VERSION ""

NS_ :

BS_:

BU_: SCCM RF_HUB PTS ORC OCM IC HCP HALF ETM ESM ESC EPS ECM EBCM DIAGNOST DASM CBC AirSusp TCM DTCM ELSDM

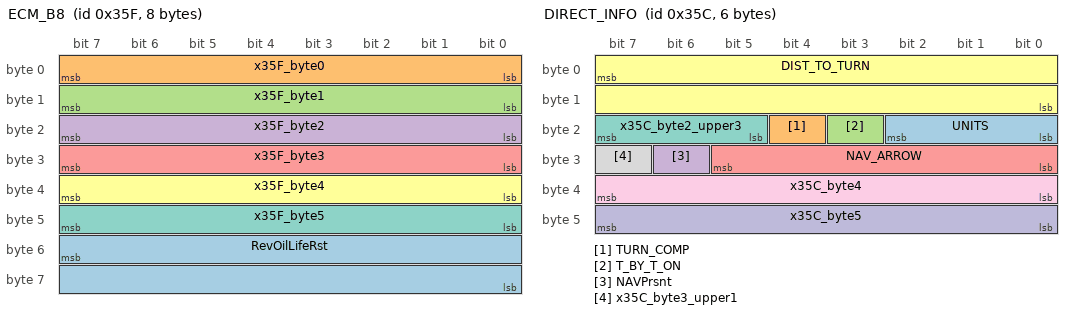
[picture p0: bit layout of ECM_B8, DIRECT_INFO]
BO_ 863 ECM_B8: 8 ECM
 SG_ RevOilLifeRst : 55|16@0+ (1000,0) [0|65534000] "Rev's"  CBC
 SG_ x35F_byte0 : 7|8@0+ (1,0) [0|0] "" Vector__XXX
 SG_ x35F_byte1 : 15|8@0+ (1,0) [0|0] "" Vector__XXX
 SG_ x35F_byte2 : 23|8@0+ (1,0) [0|0] "" Vector__XXX
 SG_ x35F_byte3 : 31|8@0+ (1,0) [0|0] "" Vector__XXX
 SG_ x35F_byte4 : 39|8@0+ (1,0) [0|0] "" Vector__XXX
 SG_ x35F_byte5 : 47|8@0+ (1,0) [0|0] "" Vector__XXX

BO_ 860 DIRECT_INFO: 6 CBC
 SG_ UNITS : 16|3@1+ (1,0) [0|7] ""  IC
 SG_ TURN_COMP : 20|1@1+ (1,0) [0|1] ""  IC
 SG_ T_BY_T_ON : 19|1@1+ (1,0) [0|1] ""  IC
 SG_ NAVPrsnt : 30|1@1+ (1,0) [0|1] ""  IC
 SG_ NAV_ARROW : 24|6@1+ (1,0) [1|63] "Arrow"  IC
 SG_ DIST_TO_TURN : 7|16@0+ (1,0) [0|65534] ""  IC
 SG_ x35C_byte2_upper3 : 21|3@1+ (1,0) [0|7] "" Vector__XXX
 SG_ x35C_byte3_upper1 : 31|1@1+ (1,0) [0|1] "" Vector__XXX
 SG_ x35C_byte4 : 32|8@1+ (1,0) [0|255] "" Vector__XXX
 SG_ x35C_byte5 : 40|8@1+ (1,0) [0|255] "" Vector__XXX

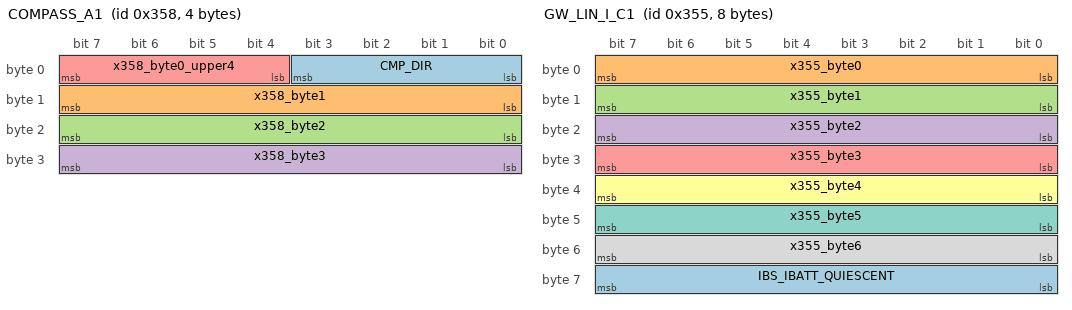
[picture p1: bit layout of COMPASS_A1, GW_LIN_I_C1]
BO_ 856 COMPASS_A1: 4 CBC
 SG_ CMP_DIR : 0|4@1+ (1,0) [0|0] ""  IC
 SG_ x358_byte1 : 8|8@1+ (1,0) [0|255] "" Vector__XXX
 SG_ x358_byte2 : 16|8@1+ (1,0) [0|255] "" Vector__XXX
 SG_ x358_byte3 : 24|8@1+ (1,0) [0|255] "" Vector__XXX
 SG_ x358_byte0_upper4 : 4|4@1+ (1,0) [0|15] "" Vector__XXX

BO_ 853 GW_LIN_I_C1: 8 CBC
 SG_ IBS_IBATT_QUIESCENT : 56|8@1+ (0.00390625,0) [0|0.984375] "Amp" Vector__XXX
 SG_ x355_byte0 : 0|8@1+ (1,0) [0|0] "" Vector__XXX
 SG_ x355_byte1 : 8|8@1+ (1,0) [0|0] "" Vector__XXX
 SG_ x355_byte2 : 16|8@1+ (1,0) [0|0] "" Vector__XXX
 SG_ x355_byte3 : 24|8@1+ (1,0) [0|0] "" Vector__XXX
 SG_ x355_byte4 : 32|8@1+ (1,0) [0|0] "" Vector__XXX
 SG_ x355_byte5 : 40|8@1+ (1,0) [0|0] "" Vector__XXX
 SG_ x355_byte6 : 48|8@1+ (1,0) [0|0] "" Vector__XXX

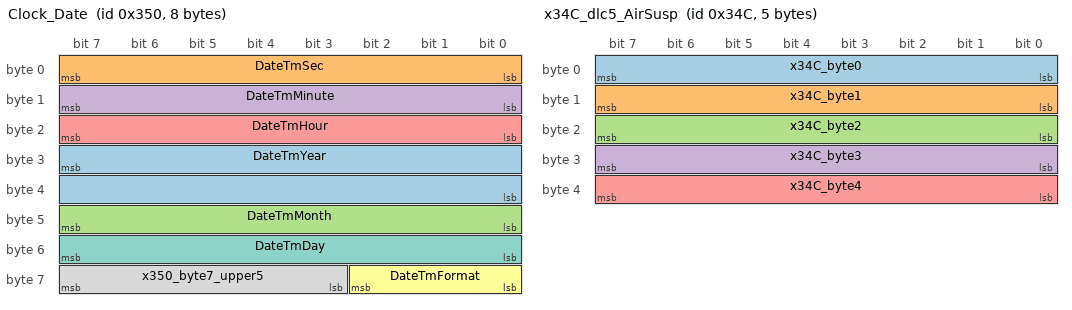
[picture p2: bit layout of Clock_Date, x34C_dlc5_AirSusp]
BO_ 848 Clock_Date: 8 CBC
 SG_ DateTmYear : 31|16@0+ (1,0) [0|65534] "Years"  RF_HUB,IC
 SG_ DateTmSec : 0|8@1+ (1,0) [0|59] "sec"  IC
 SG_ DateTmMonth : 40|8@1+ (1,0) [1|12] "Months"  RF_HUB,IC
 SG_ DateTmMinute : 8|8@1+ (1,0) [0|59] "min"  RF_HUB,IC
 SG_ DateTmHour : 16|8@1+ (1,0) [0|23] "Hours"  RF_HUB,IC
 SG_ DateTmFormat : 56|3@1+ (1,0) [0|0] ""  IC
 SG_ DateTmDay : 48|8@1+ (1,0) [1|31] "Days"  RF_HUB,IC
 SG_ x350_byte7_upper5 : 59|5@1+ (1,0) [0|31] "" Vector__XXX

BO_ 844 x34C_dlc5_AirSusp: 5 AirSusp
 SG_ x34C_byte0 : 0|8@1+ (1,0) [0|255] "" Vector__XXX
 SG_ x34C_byte1 : 8|8@1+ (1,0) [0|255] "" Vector__XXX
 SG_ x34C_byte2 : 16|8@1+ (1,0) [0|255] "" Vector__XXX
 SG_ x34C_byte3 : 24|8@1+ (1,0) [0|255] "" Vector__XXX
 SG_ x34C_byte4 : 32|8@1+ (1,0) [0|255] "" Vector__XXX

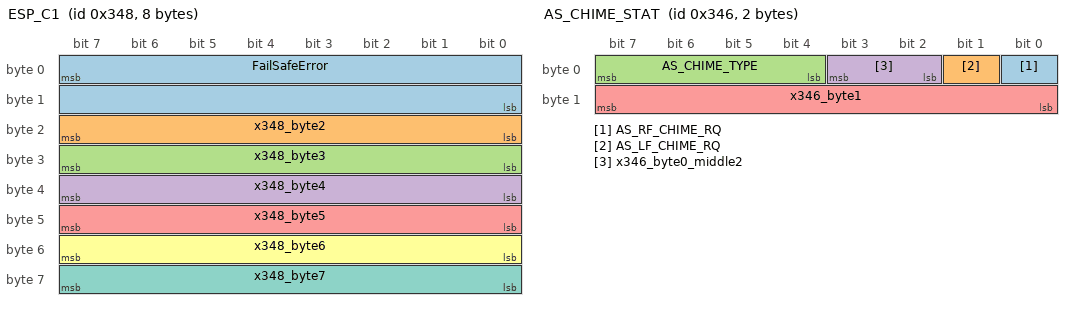
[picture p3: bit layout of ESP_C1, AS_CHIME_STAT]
BO_ 840 ESP_C1: 8 ESC
 SG_ FailSafeError : 7|16@0+ (1,0) [0|65534] ""  DASM
 SG_ x348_byte2 : 23|8@0+ (1,0) [0|255] "" Vector__XXX
 SG_ x348_byte3 : 31|8@0+ (1,0) [0|255] "" Vector__XXX
 SG_ x348_byte4 : 39|8@0+ (1,0) [0|255] "" Vector__XXX
 SG_ x348_byte5 : 47|8@0+ (1,0) [0|255] "" Vector__XXX
 SG_ x348_byte6 : 55|8@0+ (1,0) [0|255] "" Vector__XXX
 SG_ x348_byte7 : 63|8@0+ (1,0) [0|255] "" Vector__XXX

BO_ 838 AS_CHIME_STAT: 2 DASM
 SG_ AS_RF_CHIME_RQ : 0|1@1+ (1,0) [0|1] ""  CBC
 SG_ AS_LF_CHIME_RQ : 1|1@1+ (1,0) [0|1] ""  CBC
 SG_ AS_CHIME_TYPE : 4|4@1+ (1,0) [0|15] ""  ORC,CBC
 SG_ x346_byte0_middle2 : 2|2@1+ (1,0) [0|3] "" Vector__XXX
 SG_ x346_byte1 : 8|8@1+ (1,0) [0|255] "" Vector__XXX

BO_ 832 IC_500Cyc: 8 IC
 SG_ VehSpdDisp : 55|16@0+ (1,0) [0|65534] ""  CBC
 SG_ VehSpd_MPH : 47|1@1+ (1,0) [0|0] ""  CBC
 SG_ Est_Range_Disp : 32|8@1+ (1,0) [0|254] ""  ETM

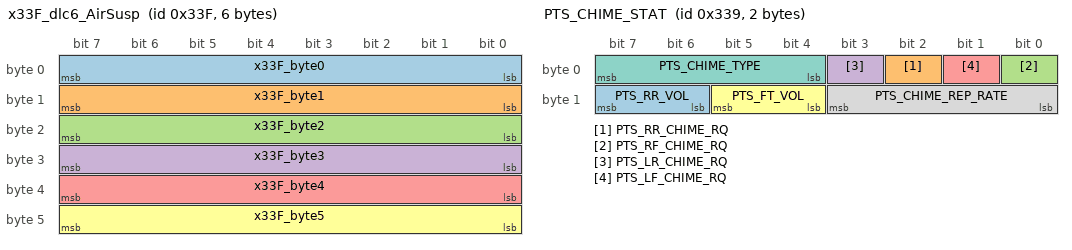
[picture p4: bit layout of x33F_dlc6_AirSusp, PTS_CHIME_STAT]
BO_ 831 x33F_dlc6_AirSusp: 6 AirSusp
 SG_ x33F_byte0 : 0|8@1+ (1,0) [0|255] "" Vector__XXX
 SG_ x33F_byte1 : 8|8@1+ (1,0) [0|255] "" Vector__XXX
 SG_ x33F_byte2 : 16|8@1+ (1,0) [0|255] "" Vector__XXX
 SG_ x33F_byte3 : 24|8@1+ (1,0) [0|255] "" Vector__XXX
 SG_ x33F_byte4 : 32|8@1+ (1,0) [0|255] "" Vector__XXX
 SG_ x33F_byte5 : 40|8@1+ (1,0) [0|255] "" Vector__XXX

BO_ 826 PTS_1: 8 PTS
 SG_ PTS_STAT : 60|2@1+ (1,0) [0|0] ""  CBC
 SG_ PTS_SRV_RQ : 5|1@1+ (1,0) [0|0] ""  IC
 SG_ PTS_RR_SRV : 59|1@1+ (1,0) [0|0] ""  IC
 SG_ PTS_RR_NA : 4|1@1+ (1,0) [0|0] ""  IC
 SG_ PTS_GraphicRR : 38|2@1+ (1,0) [0|0] ""  IC
 SG_ PTS_GraphicRL : 30|2@1+ (1,0) [0|0] ""  IC
 SG_ PTS_GraphicRC : 54|2@1+ (1,0) [0|0] ""  IC
 SG_ PTS_GraphicFR : 22|2@1+ (1,0) [0|0] ""  IC
 SG_ PTS_GraphicFL : 14|2@1+ (1,0) [0|0] ""  IC
 SG_ PTS_GraphicFC : 46|2@1+ (1,0) [0|0] ""  IC
 SG_ PTS_FT_SRV : 58|1@1+ (1,0) [0|0] ""  IC
 SG_ PTS_FT_NA : 3|1@1+ (1,0) [0|0] ""  IC
 SG_ PTS_CFG_STAT : 1|2@1+ (1,0) [0|0] ""  CBC
 SG_ PTS_AlrRR : 32|4@1+ (1,0) [0|0] ""  IC,CBC
 SG_ PTS_AlrRL : 24|4@1+ (1,0) [0|0] ""  IC,CBC
 SG_ PTS_AlrRC : 48|4@1+ (1,0) [0|0] ""  IC,CBC
 SG_ PTS_AlrFR : 16|4@1+ (1,0) [0|0] ""  IC,CBC
 SG_ PTS_AlrFL : 8|4@1+ (1,0) [0|0] ""  IC,CBC
 SG_ PTS_AlrFC : 40|4@1+ (1,0) [0|0] ""  IC,CBC

BO_ 825 PTS_CHIME_STAT: 2 PTS
 SG_ PTS_RR_VOL : 14|2@1+ (1,0) [0|0] ""  CBC
 SG_ PTS_RR_CHIME_RQ : 2|1@1+ (1,0) [0|0] ""  CBC
 SG_ PTS_RF_CHIME_RQ : 0|1@1+ (1,0) [0|0] ""  CBC
 SG_ PTS_LR_CHIME_RQ : 3|1@1+ (1,0) [0|0] ""  CBC
 SG_ PTS_LF_CHIME_RQ : 1|1@1+ (1,0) [0|0] ""  CBC
 SG_ PTS_FT_VOL : 12|2@1+ (1,0) [0|0] ""  CBC
 SG_ PTS_CHIME_TYPE : 4|4@1+ (1,0) [0|0] ""  CBC
 SG_ PTS_CHIME_REP_RATE : 8|4@1+ (1,0) [0|15] "Hz"  CBC

BO_ 820 CBC_PT1: 8 CBC
 SG_ WASH_FLUID_LO : 63|1@1+ (1,0) [0|0] ""  IC,ETM
 SG_ TurnInd_RT_ON : 31|1@1+ (1,0) [0|0] ""  IC,HALF
 SG_ TurnInd_LT_ON : 30|1@1+ (1,0) [0|0] ""  IC,HALF
 SG_ TLG_AJAR : 22|1@1+ (1,0) [0|0] ""  RF_HUB,PTS,IC,ETM
 SG_ SHIP_STAT : 28|2@1+ (1,0) [0|0] ""  RF_HUB,IC,HCP,DASM
 SG_ REV_GEAR : 4|1@1+ (1,0) [0|0] ""  ORC,HALF,EPS
 SG_ R_R_AJAR : 20|1@1+ (1,0) [0|0] ""  RF_HUB,IC,ETM
 SG_ PSG_AJAR : 18|1@1+ (1,0) [0|0] ""  RF_HUB,IC,ETM,ESC
 SG_ PARK_LMP_ON : 16|1@1+ (1,0) [0|0] ""  IC
 SG_ PANEL_INTS : 48|8@1+ (0.5,0) [0|100] "%"  SCCM,RF_HUB,IC,ESM
 SG_ LOBEAM_ON : 57|1@1+ (1,0) [0|0] "" Vector__XXX
 SG_ L_R_AJAR : 19|1@1+ (1,0) [0|0] ""  RF_HUB,IC,ETM
 SG_ IGN_OFF_TIME_LNG : 27|12@0+ (1,0) [0|4080] "min"  ESC,ECM,DASM
 SG_ HIBEAM_ON : 58|1@1+ (1,0) [0|0] ""  IC,HALF
 SG_ FT_WPR_NOT_PRK : 56|1@1+ (1,0) [0|0] ""  HALF,ECM,DASM
 SG_ FT_FOG_RQ : 2|1@1+ (1,0) [0|0] ""  IC
 SG_ FOB_SrchRq : 8|2@1+ (1,0) [0|0] ""  RF_HUB
 SG_ DRV_AJAR : 17|1@1+ (1,0) [0|0] ""  RF_HUB,PTS,IC,HCP,ETM,ESC,DASM
 SG_ DR_LK_STAT : 5|2@1+ (1,0) [0|0] "" Vector__XXX
 SG_ DAY_LGT_MD : 40|1@1+ (1,0) [0|0] ""  SCCM,RF_HUB,IC,ESM
 SG_ BRK_FLUID_LO : 62|1@1+ (1,0) [0|0] ""  IC,ETM,ESC
 SG_ AHB_ACT : 14|1@1+ (1,0) [0|0] ""  IC
 SG_ x334_byte0_lower2 : 0|2@1+ (1,0) [0|3] "" Vector__XXX
 SG_ x334_byte1_middle1 : 3|1@1+ (1,0) [0|1] "" Vector__XXX
 SG_ x334_byte0_upper1 : 7|1@1+ (1,0) [0|1] "" Vector__XXX
 SG_ x334_byte1_middle4 : 10|4@1+ (1,0) [0|15] "" Vector__XXX
 SG_ x334_byte1_upper1 : 15|1@1+ (1,0) [0|1] "" Vector__XXX
 SG_ x334_byte2_middle1 : 21|1@1+ (1,0) [0|1] "" Vector__XXX
 SG_ x334_ParkingBrakeState : 23|1@1+ (1,0) [0|1] "" Vector__XXX
 SG_ x334_byte5_upper7 : 41|7@1+ (1,0) [0|127] "" Vector__XXX
 SG_ x334_byte7_middle3 : 59|3@1+ (1,0) [0|7] "" Vector__XXX

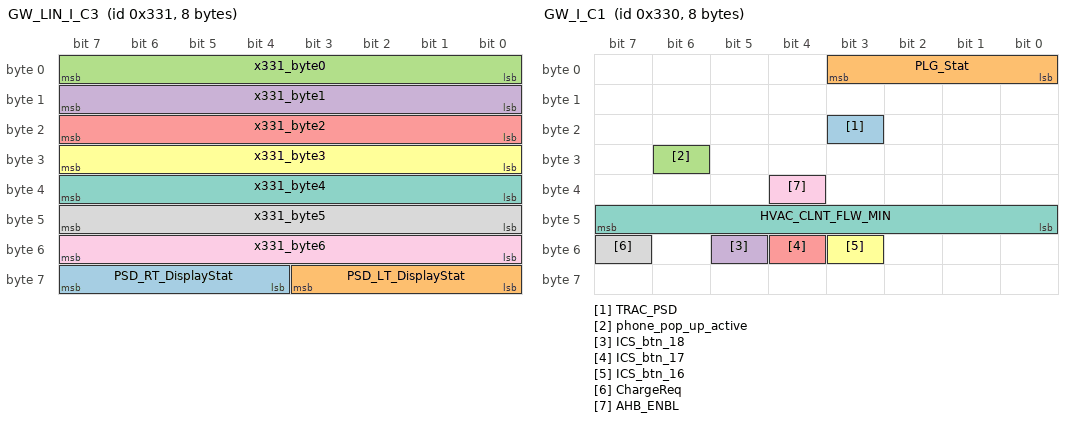
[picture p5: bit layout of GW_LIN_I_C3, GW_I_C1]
BO_ 817 GW_LIN_I_C3: 8 CBC
 SG_ PSD_RT_DisplayStat : 60|4@1+ (1,0) [0|0] ""  IC
 SG_ PSD_LT_DisplayStat : 56|4@1+ (1,0) [0|0] ""  IC
 SG_ x331_byte0 : 0|8@1+ (1,0) [0|255] "" Vector__XXX
 SG_ x331_byte1 : 8|8@1+ (1,0) [0|255] "" Vector__XXX
 SG_ x331_byte2 : 16|8@1+ (1,0) [0|255] "" Vector__XXX
 SG_ x331_byte3 : 24|8@1+ (1,0) [0|255] "" Vector__XXX
 SG_ x331_byte4 : 32|8@1+ (1,0) [0|255] "" Vector__XXX
 SG_ x331_byte5 : 40|8@1+ (1,0) [0|255] "" Vector__XXX
 SG_ x331_byte6 : 48|8@1+ (1,0) [0|255] "" Vector__XXX

BO_ 816 GW_I_C1: 8 CBC
 SG_ TRAC_PSD : 19|1@1+ (1,0) [0|0] ""  IC,ESC
 SG_ PLG_Stat : 0|4@1+ (1,0) [0|0] ""  IC
 SG_ phone_pop_up_active : 30|1@1+ (1,0) [0|0] ""  IC
 SG_ ICS_btn_18 : 53|1@1+ (1,0) [0|0] ""  HALF
 SG_ ICS_btn_17 : 52|1@1+ (1,0) [0|0] ""  PTS
 SG_ ICS_btn_16 : 51|1@1+ (1,0) [0|0] ""  PTS
 SG_ HVAC_CLNT_FLW_MIN : 40|8@1+ (0.521555,0) [0.521555|131.953415] "LpM" Vector__XXX
 SG_ ChargeReq : 55|1@1+ (1,0) [0|0] ""  IC,HCP
 SG_ AHB_ENBL : 36|1@1+ (1,0) [0|0] "" Vector__XXX

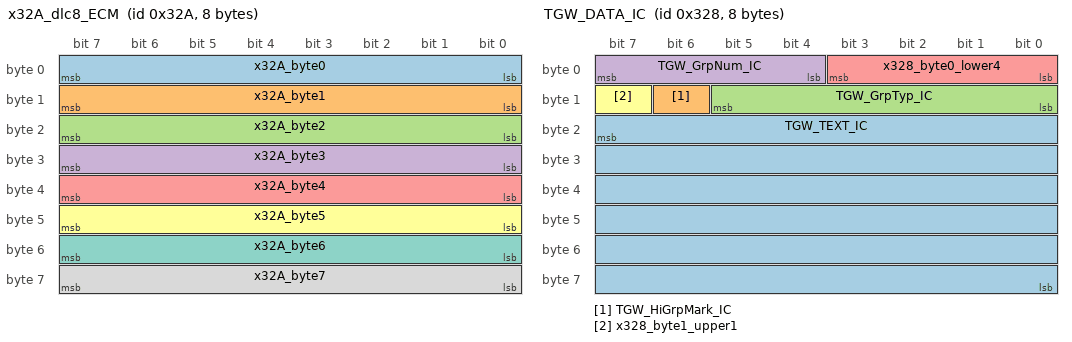
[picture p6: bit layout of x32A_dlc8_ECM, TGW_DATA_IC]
BO_ 810 x32A_dlc8_ECM: 8 ECM
 SG_ x32A_byte0 : 0|8@1+ (1,0) [0|255] "" Vector__XXX
 SG_ x32A_byte1 : 8|8@1+ (1,0) [0|255] "" Vector__XXX
 SG_ x32A_byte2 : 16|8@1+ (1,0) [0|255] "" Vector__XXX
 SG_ x32A_byte3 : 24|8@1+ (1,0) [0|255] "" Vector__XXX
 SG_ x32A_byte4 : 32|8@1+ (1,0) [0|255] "" Vector__XXX
 SG_ x32A_byte5 : 40|8@1+ (1,0) [0|255] "" Vector__XXX
 SG_ x32A_byte6 : 48|8@1+ (1,0) [0|255] "" Vector__XXX
 SG_ x32A_byte7 : 56|8@1+ (1,0) [0|255] "" Vector__XXX

BO_ 808 TGW_DATA_IC: 8 CBC
 SG_ TGW_TEXT_IC : 23|48@0+ (1,0) [0|0] ""  IC
 SG_ TGW_HiGrpMark_IC : 14|1@1+ (1,0) [0|0] ""  IC
 SG_ TGW_GrpTyp_IC : 8|6@1+ (1,0) [1|40] "Text"  IC
 SG_ TGW_GrpNum_IC : 4|4@1+ (1,1) [1|16] "Group"  IC
 SG_ x328_byte0_lower4 : 0|4@1+ (1,0) [0|15] "" Vector__XXX
 SG_ x328_byte1_upper1 : 15|1@1+ (1,0) [0|1] "" Vector__XXX

BO_ 804 CBC_PT4: 8 CBC
 SG_ WPR_SYS_WASH : 46|1@1+ (1,0) [0|0] ""  HALF,DASM,ESC
 SG_ WPR_SYS_OFF : 40|1@1+ (1,0) [0|0] ""  HALF,DASM,ESC
 SG_ WPR_SYS_MIST : 45|1@1+ (1,0) [0|0] ""  HALF,DASM,ESC
 SG_ WPR_SYS_LOW : 41|1@1+ (1,0) [0|0] ""  HALF,DASM,ESC
 SG_ WPR_SYS_INT : 43|1@1+ (1,0) [0|0] ""  HALF,DASM,ESC
 SG_ WPR_SYS_HIGH : 42|1@1+ (1,0) [0|0] ""  HALF,DASM,ESC
 SG_ WPR_SYS_FLT : 47|1@1+ (1,0) [0|0] ""  HALF,DASM,ESC
 SG_ WPR_SYS_AUTO : 44|1@1+ (1,0) [0|0] ""  HALF,DASM,ESC
 SG_ TurnLmp_RR_Flt : 25|1@1+ (1,0) [0|0] ""  HALF,IC
 SG_ TurnLmp_RL_Flt : 24|1@1+ (1,0) [0|0] ""  HALF,IC
 SG_ TurnLmp_FR_Flt : 14|1@1+ (1,0) [0|0] ""  HALF,IC
 SG_ TurnLmp_FL_Flt : 13|1@1+ (1,0) [0|0] ""  HALF,IC
 SG_ RemSt_Inhibit : 32|8@1+ (1,0) [0|0] ""  IC
 SG_ HdAjar : 10|1@1+ (1,0) [0|0] ""  IC,HCP
 SG_ ExteriorRearReleaseSwitchSts : 21|1@1+ (1,0) [0|0] ""  RF_HUB
 SG_ ACC_DLY_ACT : 26|1@1+ (1,0) [0|0] ""  IC
 SG_ x324_byte0 : 0|8@1+ (1,0) [0|255] "" Vector__XXX
 SG_ x324_byte1_lower2 : 8|2@1+ (1,0) [0|3] "" Vector__XXX
 SG_ x324_byte1_middle2 : 11|2@1+ (1,0) [0|3] "" Vector__XXX
 SG_ x324_byte1_upper1 : 15|1@1+ (1,0) [0|1] "" Vector__XXX
 SG_ x324_byte2_lower5 : 16|5@1+ (1,0) [0|31] "" Vector__XXX
 SG_ x324_byte2_upper2 : 22|2@1+ (1,0) [0|3] "" Vector__XXX
 SG_ x324_byte3_upper5 : 27|5@1+ (1,0) [0|31] "" Vector__XXX
 SG_ x324_byte6 : 48|8@1+ (1,0) [0|255] "" Vector__XXX
 SG_ x324_byte7 : 56|8@1+ (1,0) [0|255] "" Vector__XXX

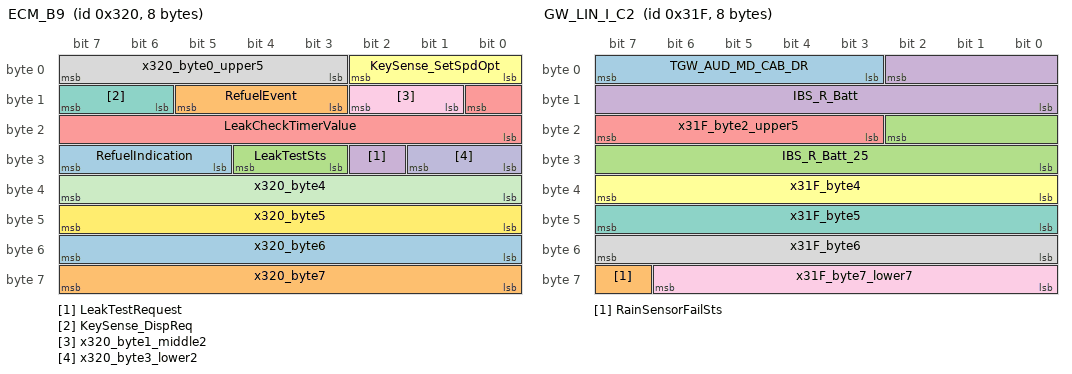
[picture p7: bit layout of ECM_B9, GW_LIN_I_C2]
BO_ 800 ECM_B9: 8 ECM
 SG_ RefuelIndication : 29|3@1+ (1,0) [0|0] ""  IC
 SG_ RefuelEvent : 11|3@1+ (1,0) [0|0] ""  CBC
 SG_ LeakTestSts : 27|2@1+ (1,0) [0|0] ""  CBC
 SG_ LeakTestRequest : 26|1@1+ (1,0) [0|0] ""  CBC
 SG_ LeakCheckTimerValue : 8|9@0+ (1,0) [0|510] "min"  CBC
 SG_ KeySense_SetSpdOpt : 0|3@1+ (1,0) [0|0] ""  ORC,IC,DASM,CBC
 SG_ KeySense_DispReq : 14|2@1+ (1,0) [0|0] ""  IC
 SG_ x320_byte0_upper5 : 3|5@1+ (1,0) [0|0] "" Vector__XXX
 SG_ x320_byte1_middle2 : 9|2@1+ (1,0) [0|0] "" Vector__XXX
 SG_ x320_byte3_lower2 : 24|2@1+ (1,0) [0|0] "" Vector__XXX
 SG_ x320_byte4 : 32|8@1+ (1,0) [0|0] "" Vector__XXX
 SG_ x320_byte5 : 40|8@1+ (1,0) [0|0] "" Vector__XXX
 SG_ x320_byte6 : 48|8@1+ (1,0) [0|0] "" Vector__XXX
 SG_ x320_byte7 : 56|8@1+ (1,0) [0|0] "" Vector__XXX

BO_ 799 GW_LIN_I_C2: 8 CBC
 SG_ TGW_AUD_MD_CAB_DR : 3|5@1+ (1,0) [0|0] ""  IC
 SG_ RainSensorFailSts : 63|1@1+ (1,0) [0|0] ""  IC
 SG_ IBS_R_Batt_25 : 18|11@0+ (0.05,0) [0|20] "mOhm" Vector__XXX
 SG_ IBS_R_Batt : 2|11@0+ (0.05,0) [0|20] "mOhm" Vector__XXX
 SG_ x31F_byte2_upper5 : 19|5@1+ (1,0) [0|31] "" Vector__XXX
 SG_ x31F_byte4 : 32|8@1+ (1,0) [0|255] "" Vector__XXX
 SG_ x31F_byte5 : 40|8@1+ (1,0) [0|255] "" Vector__XXX
 SG_ x31F_byte6 : 48|8@1+ (1,0) [0|255] "" Vector__XXX
 SG_ x31F_byte7_lower7 : 56|7@1+ (1,0) [0|127] "" Vector__XXX

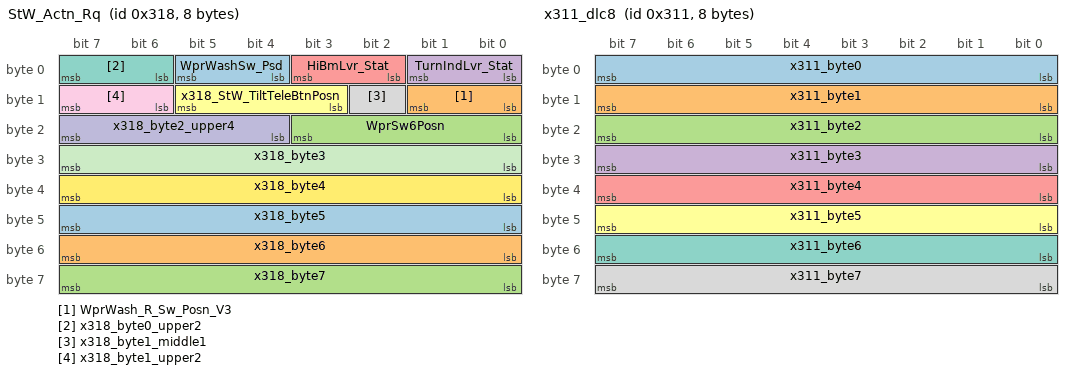
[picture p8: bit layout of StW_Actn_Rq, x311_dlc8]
BO_ 792 StW_Actn_Rq: 8 SCCM
 SG_ WprWashSw_Psd : 4|2@1+ (1,0) [0|0] ""  CBC
 SG_ WprWash_R_Sw_Posn_V3 : 8|2@1+ (1,0) [0|0] ""  CBC
 SG_ WprSw6Posn : 16|4@1+ (1,0) [0|0] ""  DASM,CBC
 SG_ TurnIndLvr_Stat : 0|2@1+ (1,0) [0|0] ""  PTS,HALF,DASM,CBC
 SG_ HiBmLvr_Stat : 2|2@1+ (1,0) [0|0] ""  CBC
 SG_ x318_StW_TiltTeleBtnPosn : 11|3@1+ (1,0) [0|7] "Enum" Vector__XXX
 SG_ x318_byte0_upper2 : 6|2@1+ (1,0) [0|3] "" Vector__XXX
 SG_ x318_byte1_middle1 : 10|1@1+ (1,0) [0|1] "" Vector__XXX
 SG_ x318_byte1_upper2 : 14|2@1+ (1,0) [0|3] "" Vector__XXX
 SG_ x318_byte2_upper4 : 20|4@1+ (1,0) [0|0] "" Vector__XXX
 SG_ x318_byte3 : 24|8@1+ (1,0) [0|0] "" Vector__XXX
 SG_ x318_byte4 : 32|8@1+ (1,0) [0|0] "" Vector__XXX
 SG_ x318_byte5 : 40|8@1+ (1,0) [0|0] "" Vector__XXX
 SG_ x318_byte6 : 48|8@1+ (1,0) [0|0] "" Vector__XXX
 SG_ x318_byte7 : 56|8@1+ (1,0) [0|0] "" Vector__XXX

BO_ 785 x311_dlc8: 8 Vector__XXX
 SG_ x311_byte0 : 0|8@1+ (1,0) [0|255] "" Vector__XXX
 SG_ x311_byte1 : 8|8@1+ (1,0) [0|255] "" Vector__XXX
 SG_ x311_byte2 : 16|8@1+ (1,0) [0|255] "" Vector__XXX
 SG_ x311_byte3 : 24|8@1+ (1,0) [0|255] "" Vector__XXX
 SG_ x311_byte4 : 32|8@1+ (1,0) [0|255] "" Vector__XXX
 SG_ x311_byte5 : 40|8@1+ (1,0) [0|255] "" Vector__XXX
 SG_ x311_byte6 : 48|8@1+ (1,0) [0|255] "" Vector__XXX
 SG_ x311_byte7 : 56|8@1+ (1,0) [0|255] "" Vector__XXX

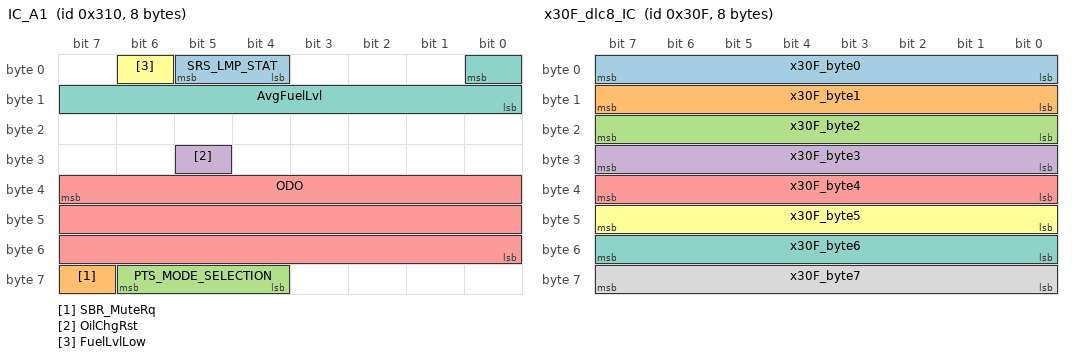
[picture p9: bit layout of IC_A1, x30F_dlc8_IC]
BO_ 784 IC_A1: 8 IC
 SG_ SRS_LMP_STAT : 4|2@1+ (1,0) [0|0] ""  ETM,ORC
 SG_ SBR_MuteRq : 63|1@1+ (1,0) [0|0] ""  CBC
 SG_ PTS_MODE_SELECTION : 60|3@1+ (1,0) [0|0] ""  PTS
 SG_ OilChgRst : 29|1@1+ (1,0) [0|0] ""  ECM
 SG_ ODO : 39|24@0+ (0.1,0) [0|1677721.4] "km"  HCP,HALF,OCM,ORC,ESM,ECM,DASM,ESC,SCCM,EPS,PTS,CBC,RF_HUB
 SG_ FuelLvlLow : 6|1@1+ (1,0) [0|0] ""  HCP,ETM,ECM,CBC
 SG_ AvgFuelLvl : 0|9@0+ (0.5,0) [0|255] "liters"  ETM,CBC,EBCM

BO_ 783 x30F_dlc8_IC: 8 IC
 SG_ x30F_byte0 : 0|8@1+ (1,0) [0|255] "" Vector__XXX
 SG_ x30F_byte1 : 8|8@1+ (1,0) [0|255] "" Vector__XXX
 SG_ x30F_byte2 : 16|8@1+ (1,0) [0|255] "" Vector__XXX
 SG_ x30F_byte3 : 24|8@1+ (1,0) [0|255] "" Vector__XXX
 SG_ x30F_byte4 : 32|8@1+ (1,0) [0|255] "" Vector__XXX
 SG_ x30F_byte5 : 40|8@1+ (1,0) [0|255] "" Vector__XXX
 SG_ x30F_byte6 : 48|8@1+ (1,0) [0|255] "" Vector__XXX
 SG_ x30F_byte7 : 56|8@1+ (1,0) [0|255] "" Vector__XXX

BO_ 782 IC_A5: 8 IC
 SG_ Total_Range : 18|11@0+ (1,0) [0|2046] "km"  ETM,CBC
 SG_ Gas_Range : 1|10@0+ (1,0) [0|1022] "km"  ETM,CBC

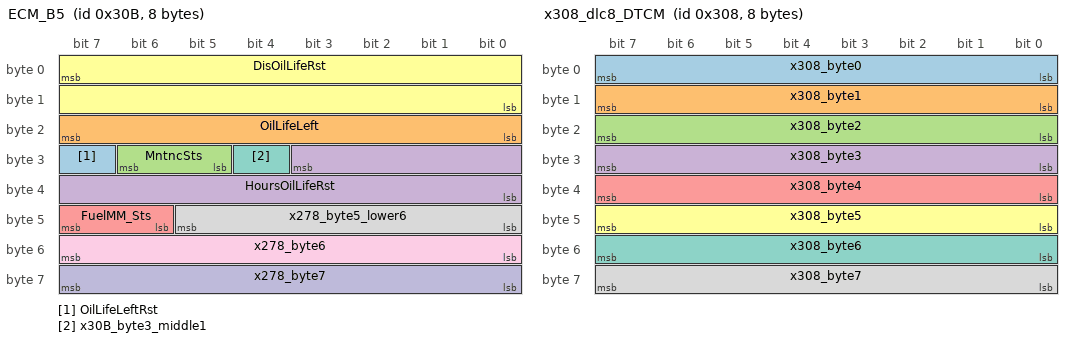
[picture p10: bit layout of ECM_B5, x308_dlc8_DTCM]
BO_ 779 ECM_B5: 8 ECM
 SG_ OilLifeLeftRst : 31|1@1+ (1,0) [0|0] ""  IC,ETM
 SG_ OilLifeLeft : 16|8@1+ (1,0) [0|100] "%"  ETM,IC
 SG_ MntncSts : 29|2@1+ (1,0) [0|0] ""  ETM,IC
 SG_ HoursOilLifeRst : 27|12@0+ (1,0) [0|4000] "Hours"  CBC
 SG_ FuelMM_Sts : 46|2@1+ (1,0) [0|0] ""  IC
 SG_ DisOilLifeRst : 7|16@0+ (1,0) [0|65534] "km"  IC,CBC
 SG_ x30B_byte3_middle1 : 28|1@1+ (1,0) [0|0] "" Vector__XXX
 SG_ x278_byte5_lower6 : 40|6@1+ (1,0) [0|0] "" Vector__XXX
 SG_ x278_byte6 : 48|8@1+ (1,0) [0|0] "" Vector__XXX
 SG_ x278_byte7 : 56|8@1+ (1,0) [0|0] "" Vector__XXX

BO_ 776 x308_dlc8_DTCM: 8 DTCM
 SG_ x308_byte0 : 0|8@1+ (1,0) [0|255] "" Vector__XXX
 SG_ x308_byte1 : 8|8@1+ (1,0) [0|255] "" Vector__XXX
 SG_ x308_byte2 : 16|8@1+ (1,0) [0|255] "" Vector__XXX
 SG_ x308_byte3 : 24|8@1+ (1,0) [0|255] "" Vector__XXX
 SG_ x308_byte4 : 32|8@1+ (1,0) [0|255] "" Vector__XXX
 SG_ x308_byte5 : 40|8@1+ (1,0) [0|255] "" Vector__XXX
 SG_ x308_byte6 : 48|8@1+ (1,0) [0|255] "" Vector__XXX
 SG_ x308_byte7 : 56|8@1+ (1,0) [0|255] "" Vector__XXX

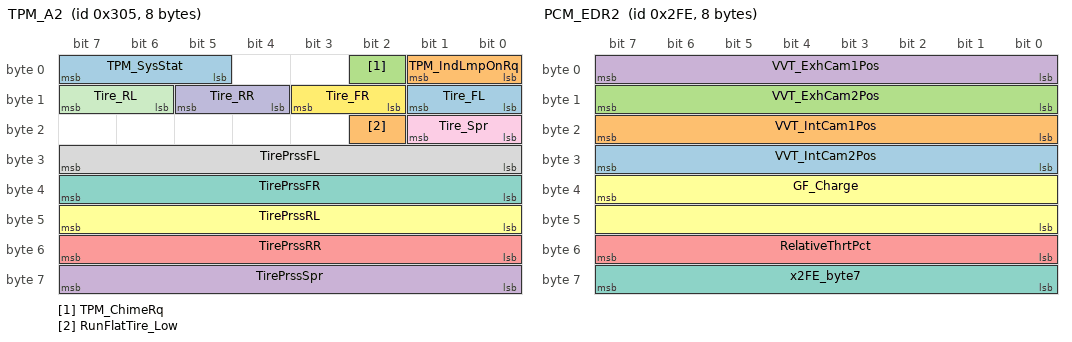
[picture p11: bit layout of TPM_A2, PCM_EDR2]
BO_ 773 TPM_A2: 8 RF_HUB
 SG_ TPM_SysStat : 5|3@1+ (1,0) [0|0] ""  IC
 SG_ TPM_IndLmpOnRq : 0|2@1+ (1,0) [0|0] ""  ETM,ORC,IC
 SG_ TPM_ChimeRq : 2|1@1+ (1,0) [0|0] ""  IC
 SG_ TirePrssSpr : 56|8@1+ (1,0) [0|126] "psi"  ORC,IC
 SG_ TirePrssRR : 48|8@1+ (1,0) [0|126] "psi"  ETM,ORC,IC
 SG_ TirePrssRL : 40|8@1+ (1,0) [0|126] "psi"  ETM,ORC,IC
 SG_ TirePrssFR : 32|8@1+ (1,0) [0|126] "psi"  ETM,ORC,IC
 SG_ TirePrssFL : 24|8@1+ (1,0) [0|126] "psi"  ETM,ORC,IC
 SG_ Tire_Spr : 16|2@1+ (1,0) [0|0] ""  ORC,IC
 SG_ Tire_RR : 12|2@1+ (1,0) [0|0] ""  ORC,IC,ETM
 SG_ Tire_RL : 14|2@1+ (1,0) [0|0] ""  ORC,IC,ETM
 SG_ Tire_FR : 10|2@1+ (1,0) [0|0] ""  ORC,IC,ETM
 SG_ Tire_FL : 8|2@1+ (1,0) [0|0] ""  ORC,IC,ETM
 SG_ RunFlatTire_Low : 18|1@1+ (1,0) [0|0] ""  IC

BO_ 766 PCM_EDR2: 8 ECM
 SG_ VVT_IntCam2Pos : 24|8@1+ (1,0) [1|255] "Degrees" Vector__XXX
 SG_ VVT_IntCam1Pos : 16|8@1+ (1,0) [1|255] "Degrees" Vector__XXX
 SG_ VVT_ExhCam2Pos : 8|8@1+ (1,0) [1|255] "Degrees" Vector__XXX
 SG_ VVT_ExhCam1Pos : 0|8@1+ (1,0) [1|255] "Degrees" Vector__XXX
 SG_ RelativeThrtPct : 48|8@1+ (0.4,0) [0|100] "%"  ORC
 SG_ GF_Charge : 39|16@0+ (0.2,0) [0|13106.8] "mg/cycle/cyl"  ORC
 SG_ x2FE_byte7 : 56|8@1+ (1,0) [0|0] "" Vector__XXX

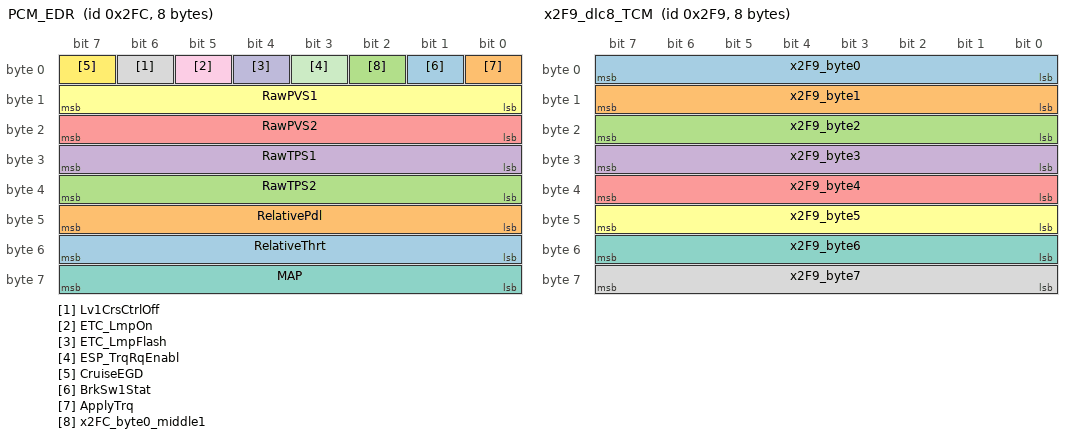
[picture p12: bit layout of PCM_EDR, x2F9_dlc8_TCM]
BO_ 764 PCM_EDR: 8 ECM
 SG_ RelativeThrt : 48|8@1+ (0.019607843,0) [0|4.98] "Volts" Vector__XXX
 SG_ RelativePdl : 40|8@1+ (0.019607843,0) [0|4.98] "Volts" Vector__XXX
 SG_ RawTPS2 : 32|8@1+ (0.019607843,0) [0|4.98] "Volts"  ORC
 SG_ RawTPS1 : 24|8@1+ (0.019607843,0) [0|4.98] "Volts"  ORC
 SG_ RawPVS2 : 16|8@1+ (0.019607843,0) [0|4.98] "Volts"  ORC
 SG_ RawPVS1 : 8|8@1+ (0.019607843,0) [0|4.98] "Volts"  ORC
 SG_ MAP : 56|8@1+ (0.8,0) [0|203.2] "kPa"  ORC
 SG_ Lv1CrsCtrlOff : 6|1@1+ (1,0) [0|0] ""  ORC
 SG_ ETC_LmpOn : 5|1@1+ (1,0) [0|0] ""  ORC
 SG_ ETC_LmpFlash : 4|1@1+ (1,0) [0|0] ""  ORC
 SG_ ESP_TrqRqEnabl : 3|1@1+ (1,0) [0|0] ""  ORC
 SG_ CruiseEGD : 7|1@1+ (1,0) [0|0] "" Vector__XXX
 SG_ BrkSw1Stat : 1|1@1+ (1,0) [0|0] "" Vector__XXX
 SG_ ApplyTrq : 0|1@1+ (1,0) [0|0] "" Vector__XXX
 SG_ x2FC_byte0_middle1 : 2|1@1+ (1,0) [0|0] "" Vector__XXX

BO_ 761 x2F9_dlc8_TCM: 8 TCM
 SG_ x2F9_byte0 : 0|8@1+ (1,0) [0|255] "" Vector__XXX
 SG_ x2F9_byte1 : 8|8@1+ (1,0) [0|255] "" Vector__XXX
 SG_ x2F9_byte2 : 16|8@1+ (1,0) [0|255] "" Vector__XXX
 SG_ x2F9_byte3 : 24|8@1+ (1,0) [0|255] "" Vector__XXX
 SG_ x2F9_byte4 : 32|8@1+ (1,0) [0|255] "" Vector__XXX
 SG_ x2F9_byte5 : 40|8@1+ (1,0) [0|255] "" Vector__XXX
 SG_ x2F9_byte6 : 48|8@1+ (1,0) [0|255] "" Vector__XXX
 SG_ x2F9_byte7 : 56|8@1+ (1,0) [0|255] "" Vector__XXX

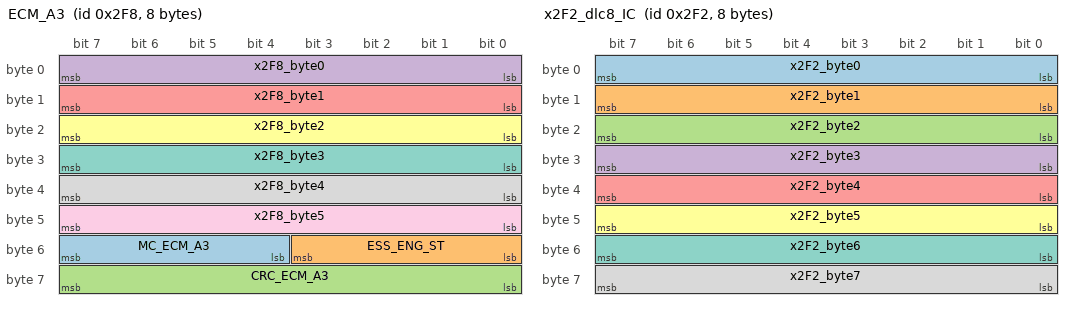
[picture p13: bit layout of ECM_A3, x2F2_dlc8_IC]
BO_ 760 ECM_A3: 8 ECM
 SG_ MC_ECM_A3 : 52|4@1+ (1,0) [0|15] ""  PTS,ESC,EPS
 SG_ ESS_ENG_ST : 48|4@1+ (1,0) [0|0] ""  SCCM,RF_HUB,PTS,ORC,OCM,IC,HCP,HALF,ESM,ESC,EPS,EBCM,DASM,CBC
 SG_ CRC_ECM_A3 : 56|8@1+ (1,0) [0|0] ""  PTS,ESC
 SG_ x2F8_byte0 : 0|8@1+ (1,0) [0|255] "" Vector__XXX
 SG_ x2F8_byte1 : 8|8@1+ (1,0) [0|255] "" Vector__XXX
 SG_ x2F8_byte2 : 16|8@1+ (1,0) [0|255] "" Vector__XXX
 SG_ x2F8_byte3 : 24|8@1+ (1,0) [0|255] "" Vector__XXX
 SG_ x2F8_byte4 : 32|8@1+ (1,0) [0|255] "" Vector__XXX
 SG_ x2F8_byte5 : 40|8@1+ (1,0) [0|255] "" Vector__XXX

BO_ 754 x2F2_dlc8_IC: 8 IC
 SG_ x2F2_byte0 : 0|8@1+ (1,0) [0|255] "" Vector__XXX
 SG_ x2F2_byte1 : 8|8@1+ (1,0) [0|255] "" Vector__XXX
 SG_ x2F2_byte2 : 16|8@1+ (1,0) [0|255] "" Vector__XXX
 SG_ x2F2_byte3 : 24|8@1+ (1,0) [0|255] "" Vector__XXX
 SG_ x2F2_byte4 : 32|8@1+ (1,0) [0|255] "" Vector__XXX
 SG_ x2F2_byte5 : 40|8@1+ (1,0) [0|255] "" Vector__XXX
 SG_ x2F2_byte6 : 48|8@1+ (1,0) [0|255] "" Vector__XXX
 SG_ x2F2_byte7 : 56|8@1+ (1,0) [0|255] "" Vector__XXX

BO_ 752 x2F0_dlc2_CBC: 2 CBC
 SG_ x2F0_byte0 : 0|8@1+ (1,0) [0|255] "" Vector__XXX
 SG_ x2F0_byte1 : 8|8@1+ (1,0) [0|255] "" Vector__XXX

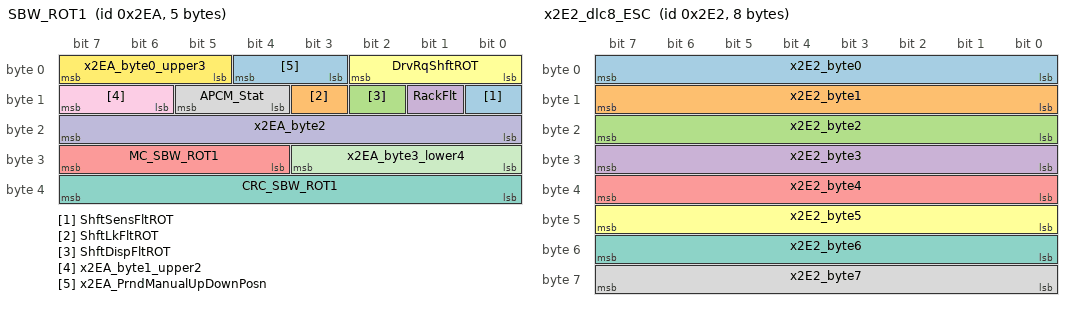
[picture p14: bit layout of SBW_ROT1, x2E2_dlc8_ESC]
BO_ 746 SBW_ROT1: 5 ESM
 SG_ ShftSensFltROT : 8|1@1+ (1,0) [0|0] ""  IC,HCP
 SG_ ShftLkFltROT : 11|1@1+ (1,0) [0|0] ""  HCP
 SG_ ShftDispFltROT : 10|1@1+ (1,0) [0|0] ""  HCP
 SG_ RackFlt : 9|1@1+ (1,0) [0|0] ""  HCP
 SG_ MC_SBW_ROT1 : 28|4@1+ (1,0) [0|15] ""  HCP
 SG_ DrvRqShftROT : 0|3@1+ (1,0) [0|0] ""  HCP,ECM,RF_HUB
 SG_ CRC_SBW_ROT1 : 32|8@1+ (1,0) [0|0] ""  HCP
 SG_ APCM_Stat : 12|2@1+ (1,0) [0|0] ""  HCP
 SG_ x2EA_byte1_upper2 : 14|2@1+ (1,0) [0|3] "" Vector__XXX
 SG_ x2EA_byte2 : 16|8@1+ (1,0) [0|255] "" Vector__XXX
 SG_ x2EA_byte3_lower4 : 24|4@1+ (1,0) [0|15] "" Vector__XXX
 SG_ x2EA_byte0_upper3 : 5|3@1+ (1,0) [0|31] "" Vector__XXX
 SG_ x2EA_PrndManualUpDownPosn : 3|2@1+ (1,0) [0|3] "" Vector__XXX

BO_ 738 x2E2_dlc8_ESC: 8 ESC
 SG_ x2E2_byte0 : 0|8@1+ (1,0) [0|255] "" Vector__XXX
 SG_ x2E2_byte1 : 8|8@1+ (1,0) [0|255] "" Vector__XXX
 SG_ x2E2_byte2 : 16|8@1+ (1,0) [0|255] "" Vector__XXX
 SG_ x2E2_byte3 : 24|8@1+ (1,0) [0|255] "" Vector__XXX
 SG_ x2E2_byte4 : 32|8@1+ (1,0) [0|255] "" Vector__XXX
 SG_ x2E2_byte5 : 40|8@1+ (1,0) [0|255] "" Vector__XXX
 SG_ x2E2_byte6 : 48|8@1+ (1,0) [0|255] "" Vector__XXX
 SG_ x2E2_byte7 : 56|8@1+ (1,0) [0|255] "" Vector__XXX

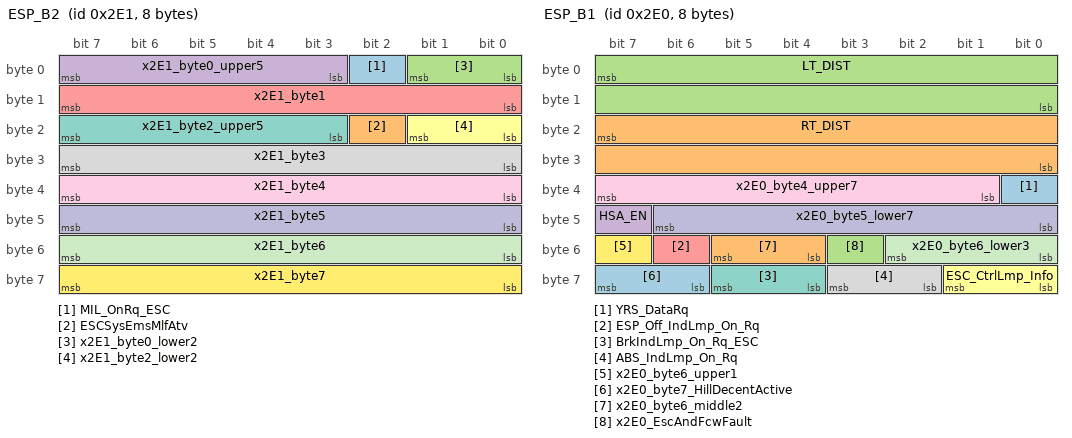
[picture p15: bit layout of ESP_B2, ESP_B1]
BO_ 737 ESP_B2: 8 ESC
 SG_ MIL_OnRq_ESC : 2|1@1+ (1,0) [0|0] ""  ECM
 SG_ ESCSysEmsMlfAtv : 18|1@1+ (1,0) [0|0] "" Vector__XXX
 SG_ x2E1_byte0_lower2 : 0|2@1+ (1,0) [0|3] "" Vector__XXX
 SG_ x2E1_byte0_upper5 : 3|5@1+ (1,0) [0|63] "" Vector__XXX
 SG_ x2E1_byte1 : 8|8@1+ (1,0) [0|255] "" Vector__XXX
 SG_ x2E1_byte2_lower2 : 16|2@1+ (1,0) [0|3] "" Vector__XXX
 SG_ x2E1_byte2_upper5 : 19|5@1+ (1,0) [0|31] "" Vector__XXX
 SG_ x2E1_byte3 : 24|8@1+ (1,0) [0|255] "" Vector__XXX
 SG_ x2E1_byte4 : 32|8@1+ (1,0) [0|255] "" Vector__XXX
 SG_ x2E1_byte5 : 40|8@1+ (1,0) [0|255] "" Vector__XXX
 SG_ x2E1_byte6 : 48|8@1+ (1,0) [0|255] "" Vector__XXX
 SG_ x2E1_byte7 : 56|8@1+ (1,0) [0|255] "" Vector__XXX

BO_ 736 ESP_B1: 8 ESC
 SG_ YRS_DataRq : 32|1@1+ (1,0) [0|0] ""  ORC
 SG_ RT_DIST : 23|16@0+ (4,0) [0|262136] "cm"  ECM,PTS,IC,CBC
 SG_ LT_DIST : 7|16@0+ (4,0) [0|262136] "cm"  ECM,PTS,IC,CBC
 SG_ HSA_EN : 47|1@1+ (1,0) [0|0] ""  CBC
 SG_ ESP_Off_IndLmp_On_Rq : 54|1@1+ (1,0) [0|0] ""  ORC,IC,CBC
 SG_ ESC_CtrlLmp_Info : 56|2@1+ (1,0) [0|0] ""  ORC,IC,ETM
 SG_ BrkIndLmp_On_Rq_ESC : 60|2@1+ (1,0) [0|0] ""  ORC,IC,ETM
 SG_ ABS_IndLmp_On_Rq : 58|2@1+ (1,0) [0|0] ""  IC,ETM
 SG_ x2E0_byte4_upper7 : 33|7@1+ (1,0) [0|127] "" Vector__XXX
 SG_ x2E0_byte5_lower7 : 40|7@1+ (1,0) [0|127] "" Vector__XXX
 SG_ x2E0_byte6_lower3 : 48|3@1+ (1,0) [0|7] "" Vector__XXX
 SG_ x2E0_byte6_upper1 : 55|1@1+ (1,0) [0|1] "" Vector__XXX
 SG_ x2E0_byte7_HillDecentActive : 62|2@1+ (1,0) [0|3] "" Vector__XXX
 SG_ x2E0_byte6_middle2 : 52|2@1+ (1,0) [0|3] "" Vector__XXX
 SG_ x2E0_EscAndFcwFault : 51|1@1+ (1,0) [0|1] "" Vector__XXX

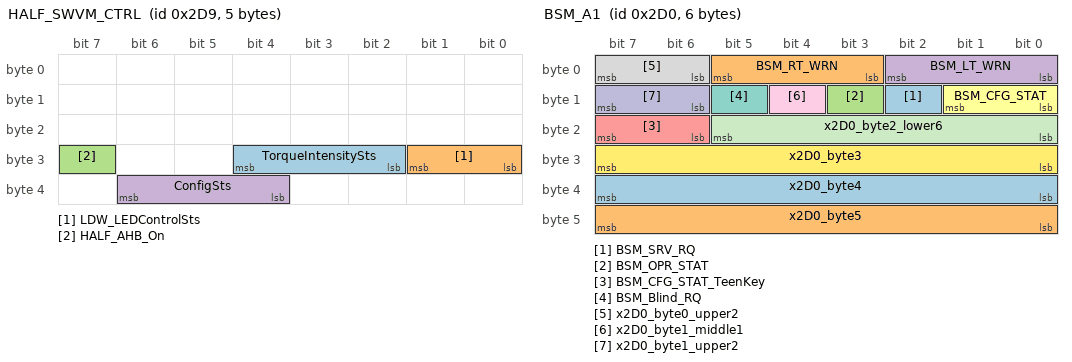
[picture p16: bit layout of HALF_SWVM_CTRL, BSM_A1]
BO_ 729 HALF_SWVM_CTRL: 5 HALF
 SG_ TorqueIntensitySts : 26|3@1+ (1,0) [0|0] ""  CBC
 SG_ LDW_LEDControlSts : 24|2@1+ (1,0) [0|0] ""  CBC
 SG_ HALF_AHB_On : 31|1@1+ (1,0) [0|0] ""  CBC
 SG_ ConfigSts : 36|3@1+ (1,0) [0|0] ""  CBC

BO_ 720 BSM_A1: 6 CBC
 SG_ BSM_SRV_RQ : 10|1@1+ (1,0) [0|0] ""  ORC,IC,DASM
 SG_ BSM_RT_WRN : 3|3@1+ (1,0) [0|0] ""  ORC,DASM
 SG_ BSM_OPR_STAT : 11|1@1+ (1,0) [0|0] ""  IC,DASM
 SG_ BSM_LT_WRN : 0|3@1+ (1,0) [0|0] ""  ORC,DASM
 SG_ BSM_CFG_STAT_TeenKey : 22|2@1+ (1,0) [0|0] ""  DASM
 SG_ BSM_CFG_STAT : 8|2@1+ (1,0) [0|0] ""  ORC,IC,DASM
 SG_ BSM_Blind_RQ : 13|1@1+ (1,0) [0|0] ""  ORC,IC,DASM
 SG_ x2D0_byte0_upper2 : 6|2@1+ (1,0) [0|3] "" Vector__XXX
 SG_ x2D0_byte1_middle1 : 12|1@1+ (1,0) [0|1] "" Vector__XXX
 SG_ x2D0_byte1_upper2 : 14|2@1+ (1,0) [0|3] "" Vector__XXX
 SG_ x2D0_byte2_lower6 : 16|6@1+ (1,0) [0|63] "" Vector__XXX
 SG_ x2D0_byte3 : 24|8@1+ (1,0) [0|255] "" Vector__XXX
 SG_ x2D0_byte4 : 32|8@1+ (1,0) [0|255] "" Vector__XXX
 SG_ x2D0_byte5 : 40|8@1+ (1,0) [0|255] "" Vector__XXX

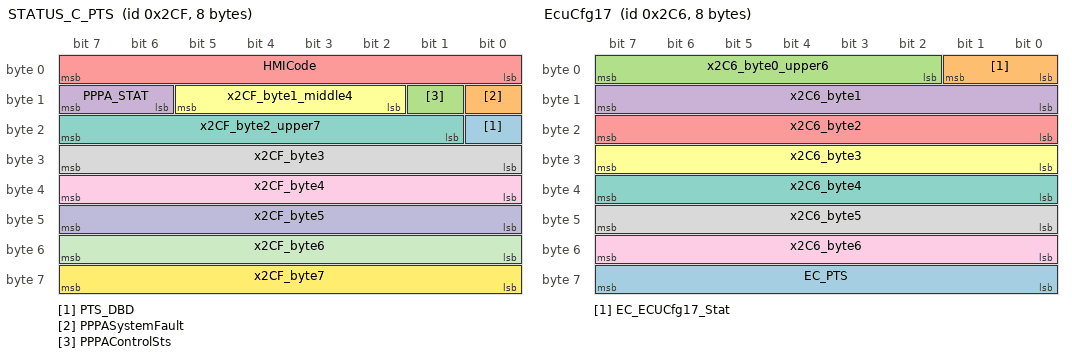
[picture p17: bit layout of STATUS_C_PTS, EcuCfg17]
BO_ 719 STATUS_C_PTS: 8 PTS
 SG_ PTS_DBD : 16|1@1+ (1,0) [0|0] ""  IC
 SG_ PPPASystemFault : 8|1@1+ (1,0) [0|0] ""  IC
 SG_ PPPAControlSts : 9|1@1+ (1,0) [0|0] ""  IC,ECM
 SG_ PPPA_STAT : 14|2@1+ (1,0) [0|0] ""  CBC
 SG_ HMICode : 0|8@1+ (1,0) [0|0] ""  IC
 SG_ x2CF_byte1_middle4 : 10|4@1+ (1,0) [0|15] "" Vector__XXX
 SG_ x2CF_byte2_upper7 : 17|7@1+ (1,0) [0|127] "" Vector__XXX
 SG_ x2CF_byte3 : 24|8@1+ (1,0) [0|255] "" Vector__XXX
 SG_ x2CF_byte4 : 32|8@1+ (1,0) [0|255] "" Vector__XXX
 SG_ x2CF_byte5 : 40|8@1+ (1,0) [0|255] "" Vector__XXX
 SG_ x2CF_byte6 : 48|8@1+ (1,0) [0|255] "" Vector__XXX
 SG_ x2CF_byte7 : 56|8@1+ (1,0) [0|255] "" Vector__XXX

BO_ 710 EcuCfg17: 8 CBC
 SG_ EC_PTS : 56|8@1+ (1,0) [0|0] ""  RF_HUB,PTS
 SG_ EC_ECUCfg17_Stat : 0|2@1+ (1,0) [0|0] ""  RF_HUB,PTS
 SG_ x2C6_byte0_upper6 : 2|6@1+ (1,0) [0|63] "" Vector__XXX
 SG_ x2C6_byte1 : 8|8@1+ (1,0) [0|255] "" Vector__XXX
 SG_ x2C6_byte2 : 16|8@1+ (1,0) [0|255] "" Vector__XXX
 SG_ x2C6_byte3 : 24|8@1+ (1,0) [0|255] "" Vector__XXX
 SG_ x2C6_byte4 : 32|8@1+ (1,0) [0|255] "" Vector__XXX
 SG_ x2C6_byte5 : 40|8@1+ (1,0) [0|255] "" Vector__XXX
 SG_ x2C6_byte6 : 48|8@1+ (1,0) [0|255] "" Vector__XXX

BO_ 709 EcuCfg16: 8 CBC
 SG_ EC_ECUCfg16_Stat : 0|2@1+ (1,0) [0|0] ""  RF_HUB
 SG_ EC_AudTel3B : 15|56@0+ (1,0) [0|0] ""  RF_HUB
 SG_ EC_AudTel3A : 2|6@1+ (1,0) [0|0] ""  RF_HUB

BO_ 706 EcuCfg15: 8 CBC
 SG_ EC_Suspension : 55|16@0+ (1,0) [0|0] ""  RF_HUB
 SG_ EC_ECUCfg15_Stat : 0|2@1+ (1,0) [0|0] ""  RF_HUB
 SG_ EC_CBC15B : 15|40@0+ (1,0) [0|0] ""  RF_HUB
 SG_ EC_CBC15A : 2|6@1+ (1,0) [0|0] ""  RF_HUB

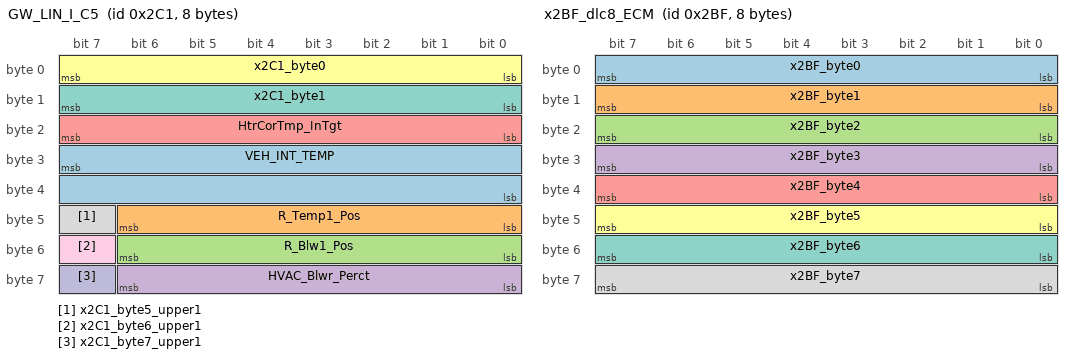
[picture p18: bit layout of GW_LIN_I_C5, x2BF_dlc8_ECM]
BO_ 705 GW_LIN_I_C5: 8 CBC
 SG_ VEH_INT_TEMP : 31|16@0+ (0.01,-40) [-40|85] "°C"  HCP
 SG_ R_Temp1_Pos : 40|7@1+ (1,0) [0|100] "%"  HCP
 SG_ R_Blw1_Pos : 48|7@1+ (1,0) [0|100] "%"  HCP
 SG_ HVAC_Blwr_Perct : 56|7@1+ (1,0) [0|100] "%"  HCP
 SG_ HtrCorTmp_InTgt : 16|8@1+ (1,-40) [-40|214] "°C"  HCP
 SG_ x2C1_byte0 : 0|8@1+ (1,0) [0|255] "" Vector__XXX
 SG_ x2C1_byte1 : 8|8@1+ (1,0) [0|255] "" Vector__XXX
 SG_ x2C1_byte5_upper1 : 47|1@1+ (1,0) [0|1] "" Vector__XXX
 SG_ x2C1_byte6_upper1 : 55|1@1+ (1,0) [0|1] "" Vector__XXX
 SG_ x2C1_byte7_upper1 : 63|1@1+ (1,0) [0|1] "" Vector__XXX

BO_ 703 x2BF_dlc8_ECM: 8 ECM
 SG_ x2BF_byte0 : 0|8@1+ (1,0) [0|255] "" Vector__XXX
 SG_ x2BF_byte1 : 8|8@1+ (1,0) [0|255] "" Vector__XXX
 SG_ x2BF_byte2 : 16|8@1+ (1,0) [0|255] "" Vector__XXX
 SG_ x2BF_byte3 : 24|8@1+ (1,0) [0|255] "" Vector__XXX
 SG_ x2BF_byte4 : 32|8@1+ (1,0) [0|255] "" Vector__XXX
 SG_ x2BF_byte5 : 40|8@1+ (1,0) [0|255] "" Vector__XXX
 SG_ x2BF_byte6 : 48|8@1+ (1,0) [0|255] "" Vector__XXX
 SG_ x2BF_byte7 : 56|8@1+ (1,0) [0|255] "" Vector__XXX

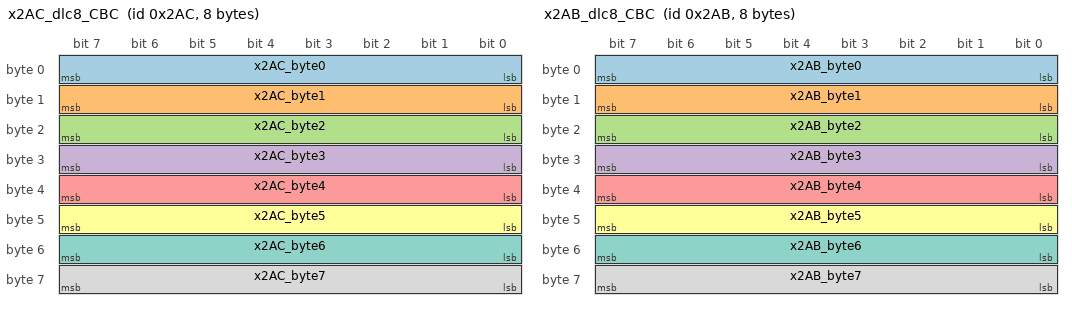
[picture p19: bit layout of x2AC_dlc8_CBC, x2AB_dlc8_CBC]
BO_ 684 x2AC_dlc8_CBC: 8 CBC
 SG_ x2AC_byte0 : 0|8@1+ (1,0) [0|255] "" Vector__XXX
 SG_ x2AC_byte1 : 8|8@1+ (1,0) [0|255] "" Vector__XXX
 SG_ x2AC_byte2 : 16|8@1+ (1,0) [0|255] "" Vector__XXX
 SG_ x2AC_byte3 : 24|8@1+ (1,0) [0|255] "" Vector__XXX
 SG_ x2AC_byte4 : 32|8@1+ (1,0) [0|255] "" Vector__XXX
 SG_ x2AC_byte5 : 40|8@1+ (1,0) [0|255] "" Vector__XXX
 SG_ x2AC_byte6 : 48|8@1+ (1,0) [0|255] "" Vector__XXX
 SG_ x2AC_byte7 : 56|8@1+ (1,0) [0|255] "" Vector__XXX

BO_ 683 x2AB_dlc8_CBC: 8 CBC
 SG_ x2AB_byte0 : 0|8@1+ (1,0) [0|255] "" Vector__XXX
 SG_ x2AB_byte1 : 8|8@1+ (1,0) [0|255] "" Vector__XXX
 SG_ x2AB_byte2 : 16|8@1+ (1,0) [0|255] "" Vector__XXX
 SG_ x2AB_byte3 : 24|8@1+ (1,0) [0|255] "" Vector__XXX
 SG_ x2AB_byte4 : 32|8@1+ (1,0) [0|255] "" Vector__XXX
 SG_ x2AB_byte5 : 40|8@1+ (1,0) [0|255] "" Vector__XXX
 SG_ x2AB_byte6 : 48|8@1+ (1,0) [0|255] "" Vector__XXX
 SG_ x2AB_byte7 : 56|8@1+ (1,0) [0|255] "" Vector__XXX

CM_ SG_ 863 RevOilLifeRst "Engine revolutions since last oil life reset";
CM_ SG_ 860 UNITS "Unit of measure";
CM_ SG_ 860 TURN_COMP "Turn complete";
CM_ SG_ 860 T_BY_T_ON "Turn by turn on";
CM_ SG_ 860 NAVPrsnt "A navigation system module is present";
CM_ SG_ 860 NAV_ARROW "Navigation arrow type. 62 and 63 show no arrow but still show text";
CM_ SG_ 860 DIST_TO_TURN "Numeric distance to next turn";
CM_ SG_ 856 CMP_DIR "Compass direction (WK/LX)";
CM_ SG_ 853 IBS_IBATT_QUIESCENT "Battery quiescent current";
CM_ SG_ 848 DateTmYear "Date year";
CM_ SG_ 848 DateTmSec "Time of day: SECONDS";
CM_ SG_ 848 DateTmMonth "Month";
CM_ SG_ 848 DateTmMinute "Time of day: MINUTES";
CM_ SG_ 848 DateTmHour "Time of day: HOURS";
CM_ SG_ 848 DateTmFormat "Date and Time Format";
CM_ SG_ 848 DateTmDay "Day";
CM_ BO_ 844 "Tx Rate: 954ms, Std Dev: 194.6ms";
CM_ SG_ 840 FailSafeError "Fail safe error";
CM_ SG_ 838 AS_RF_CHIME_RQ "AS right front chime on request; True = [1]";
CM_ SG_ 838 AS_LF_CHIME_RQ "AS left front chime on request; True = [1]";
CM_ SG_ 838 AS_CHIME_TYPE "AS chime type";
CM_ SG_ 832 VehSpdDisp "Vehicle speed - displayed";
CM_ SG_ 832 VehSpd_MPH "Vehicle speed signal is in miles per hour format";
CM_ SG_ 832 Est_Range_Disp "Estimated electric range for display";
CM_ BO_ 831 "Tx Rate: 199ms, Std Dev: 15.2ms";
CM_ SG_ 826 PTS_STAT "Park Assist System - LED control status";
CM_ SG_ 826 PTS_SRV_RQ "PTS service warning request; True = [1]";
CM_ SG_ 826 PTS_RR_SRV "Rear PTS sensor service request; True = [1]";
CM_ SG_ 826 PTS_RR_NA "Rear park assist not available - blinded sensor; True = [1]";
CM_ SG_ 826 PTS_GraphicRR "PTS graphic flash rate rear right";
CM_ SG_ 826 PTS_GraphicRL "PTS graphic flash rate rear left";
CM_ SG_ 826 PTS_GraphicRC "PTS graphic flash rate rear center";
CM_ SG_ 826 PTS_GraphicFR "PTS graphic flash rate front right";
CM_ SG_ 826 PTS_GraphicFL "PTS graphic flash rate front left";
CM_ SG_ 826 PTS_GraphicFC "PTS graphic flash rate front center";
CM_ SG_ 826 PTS_FT_SRV "Front PTS sensor service request; True = [1]";
CM_ SG_ 826 PTS_FT_NA "Front park assist not available - blinded sensor; True = [1]";
CM_ SG_ 826 PTS_CFG_STAT "Park assist configuration status";
CM_ SG_ 826 PTS_AlrRR "PTS alert rear right";
CM_ SG_ 826 PTS_AlrRL "PTS alert rear left";
CM_ SG_ 826 PTS_AlrRC "PTS alert rear center";
CM_ SG_ 826 PTS_AlrFR "PTS alert front right";
CM_ SG_ 826 PTS_AlrFL "PTS alert front left";
CM_ SG_ 826 PTS_AlrFC "PTS alert front center";
CM_ SG_ 825 PTS_RR_VOL "PTS Rear Volume Setting";
CM_ SG_ 825 PTS_RR_CHIME_RQ "PTS right rear chime on request; True = [1]";
CM_ SG_ 825 PTS_RF_CHIME_RQ "PTS right front chime on request; True = [1]";
CM_ SG_ 825 PTS_LR_CHIME_RQ "PTS left rear chime on request; True = [1]";
CM_ SG_ 825 PTS_LF_CHIME_RQ "PTS left front chime on request; True = [1]";
CM_ SG_ 825 PTS_FT_VOL "PTS Front Volume Setting";
CM_ SG_ 825 PTS_CHIME_TYPE "PTS chime type";
CM_ SG_ 825 PTS_CHIME_REP_RATE "PTS chime repetition rate";
CM_ SG_ 820 WASH_FLUID_LO "Low washer fluid warning (1=Fluid is low)";
CM_ SG_ 820 TurnInd_RT_ON "Turn indication right is on";
CM_ SG_ 820 TurnInd_LT_ON "Turn indication left is on";
CM_ SG_ 820 TLG_AJAR "Trunk/Liftgate ajar";
CM_ SG_ 820 SHIP_STAT "Shipping status";
CM_ SG_ 820 REV_GEAR "Reverse Gear (manual trans)";
CM_ SG_ 820 R_R_AJAR "Right rear door ajar";
CM_ SG_ 820 PSG_AJAR "Passenger door ajar";
CM_ SG_ 820 PARK_LMP_ON "Parklamps are on; off=[0], on=[1]";
CM_ SG_ 820 PANEL_INTS "Panel-/display intensity";
CM_ SG_ 820 LOBEAM_ON "Low beam is on; off=[0], on=[1]";
CM_ SG_ 820 L_R_AJAR "Left rear door ajar";
CM_ SG_ 820 IGN_OFF_TIME_LNG "Time since last ignition on (long)";
CM_ SG_ 820 HIBEAM_ON "High beam is on; off=[0], on=[1]";
CM_ SG_ 820 FT_WPR_NOT_PRK "Front wiper outside park position";
CM_ SG_ 820 FT_FOG_RQ "Front fog request; off=[0], on=[1]";
CM_ SG_ 820 FOB_SrchRq "FOB search request";
CM_ SG_ 820 DRV_AJAR "Driver door ajar (1 = Door Ajar)";
CM_ SG_ 820 DR_LK_STAT "Door lock status";
CM_ SG_ 820 DAY_LGT_MD "Day light brightness mode; Night=[0], Day=[1]";
CM_ SG_ 820 BRK_FLUID_LO "Low brake fluid warning; low = [1]";
CM_ SG_ 820 AHB_ACT "Automatic high beam active";
CM_ SG_ 817 PSD_RT_DisplayStat "Right power sliding door display status";
CM_ SG_ 817 PSD_LT_DisplayStat "Left power sliding door display status";
CM_ BO_ 816 "Tx Rate: 971ms, Std Dev: 171.5ms";
CM_ SG_ 816 TRAC_PSD "Traction on/off button pressed; [0] = Not Pressed, [1] = Pressed";
CM_ SG_ 816 PLG_Stat "Power liftgate status";
CM_ SG_ 816 phone_pop_up_active "Phone pop up is active; True = [1]";
CM_ SG_ 816 ICS_btn_18 "LDW Off pressed";
CM_ SG_ 816 ICS_btn_17 "PTS Off pressed";
CM_ SG_ 816 ICS_btn_16 "PPA pressed";
CM_ SG_ 816 HVAC_CLNT_FLW_MIN "HVAC coolant flow minimum request";
CM_ SG_ 816 ChargeReq "Request for scheduled charge; Charge now = [1]";
CM_ SG_ 816 AHB_ENBL "Auto highbeam enable";
CM_ BO_ 810 "Tx Rate: 100ms, Std Dev: 5.4ms";
CM_ SG_ 808 TGW_TEXT_IC "TGW text string information to IC";
CM_ SG_ 808 TGW_HiGrpMark_IC "TGW high group mark to IC; [0] = Not True, [1] = True";
CM_ SG_ 808 TGW_GrpTyp_IC "Group type to send text data from TGW to IC";
CM_ SG_ 808 TGW_GrpNum_IC "TGW group number to IC";
CM_ SG_ 804 WPR_SYS_WASH "Wiper system wash; [1] = wash request";
CM_ SG_ 804 WPR_SYS_OFF "Wiper system off; [1] = switch is OFF";
CM_ SG_ 804 WPR_SYS_MIST "Wiper system mist; [1] = mist request";
CM_ SG_ 804 WPR_SYS_LOW "Wiper system low; [1] = switch is LOW";
CM_ SG_ 804 WPR_SYS_INT "Wiper system intermittent; [1] = switch is INT";
CM_ SG_ 804 WPR_SYS_HIGH "Wiper system high; [1] = switch is HIGH";
CM_ SG_ 804 WPR_SYS_FLT "Wiper system fault present; [1] = fault present";
CM_ SG_ 804 WPR_SYS_AUTO "Wiper system auto; [1] = Auto wipers equipped";
CM_ SG_ 804 TurnLmp_RR_Flt "Turn indication lamp rear right fault";
CM_ SG_ 804 TurnLmp_RL_Flt "Turn indication lamp rear left fault";
CM_ SG_ 804 TurnLmp_FR_Flt "Turn indication lamp front right fault";
CM_ SG_ 804 TurnLmp_FL_Flt "Turn indication lamp front left fault";
CM_ SG_ 804 RemSt_Inhibit "Remote start inhibit";
CM_ SG_ 804 HdAjar "Hood latch ajar, left or single (1=ajar)";
CM_ SG_ 804 ExteriorRearReleaseSwitchSts "Exterior rear release switch status";
CM_ SG_ 804 ACC_DLY_ACT "Accessory Delay Active";
CM_ SG_ 800 RefuelIndication "Indication to the driver about the status of the refuel system";
CM_ SG_ 800 RefuelEvent "Status of refuel event";
CM_ SG_ 800 LeakTestSts "Status of leak test";
CM_ SG_ 800 LeakTestRequest "Leak test is requested after powerdown; No request = [0], Leak test requested = [1]";
CM_ SG_ 800 LeakCheckTimerValue "Requested leak test timer value";
CM_ SG_ 800 KeySense_SetSpdOpt "Key sense max speed option for ECM speed limiting";
CM_ SG_ 800 KeySense_DispReq "Key sense cluster EVIC request";
CM_ SG_ 799 TGW_AUD_MD_CAB_DR "TGW audio mode for Cabin/Driver";
CM_ SG_ 799 RainSensorFailSts "Fail present = 1";
CM_ SG_ 799 IBS_R_Batt_25 "Batt resistance at 100% SOC and 25 degC";
CM_ SG_ 799 IBS_R_Batt "Calculated battery resistance";
CM_ SG_ 792 WprWashSw_Psd "Front wiper switch pressed";
CM_ SG_ 792 WprWash_R_Sw_Posn_V3 "Backlite wiper/washer switch position";
CM_ SG_ 792 WprSw6Posn "Wiper switch (6 stages) position";
CM_ SG_ 792 TurnIndLvr_Stat "Turn indicator lever state";
CM_ SG_ 792 HiBmLvr_Stat "High beam lever state";
CM_ SG_ 792 x318_StW_TiltTeleBtnPosn "Steering wheel power tilt/telescope button position";
CM_ BO_ 785 "Tx Rate: 971ms, Std Dev: 171.5ms";
CM_ SG_ 784 SRS_LMP_STAT "Airbag indicator lamp status";
CM_ SG_ 784 SBR_MuteRq "Seatbelt reminder audio mute request; Mute = [1]";
CM_ SG_ 784 PTS_MODE_SELECTION "Park assist maneuver selection for PTS";
CM_ SG_ 784 OilChgRst "Oil change reminder reset request";
CM_ SG_ 784 ODO "Odometer";
CM_ SG_ 784 FuelLvlLow "Fuel level low";
CM_ SG_ 784 AvgFuelLvl "Average filtered fuel level in liters";
CM_ BO_ 783 "Tx Rate: 971ms, Std Dev: 171.5ms";
CM_ SG_ 782 Total_Range "Total range or DTE";
CM_ SG_ 782 Gas_Range "Gas range or DTE";
CM_ SG_ 779 OilLifeLeftRst "Oil life remaining has been reset";
CM_ SG_ 779 OilLifeLeft "Oil life left";
CM_ SG_ 779 MntncSts "Maintenance reminder status";
CM_ SG_ 779 HoursOilLifeRst "Hours since last oil life reset";
CM_ SG_ 779 FuelMM_Sts "Fuel maintenance mode status";
CM_ SG_ 779 DisOilLifeRst "Distance since last oil life reset";
CM_ BO_ 776 "Tx Rate: 895ms, Std Dev: 285.8ms";
CM_ SG_ 773 TPM_SysStat "TPM system localization status";
CM_ SG_ 773 TPM_IndLmpOnRq "Tire pressure indication request";
CM_ SG_ 773 TPM_ChimeRq "TPM chime request";
CM_ SG_ 773 TirePrssSpr "Tire pressure spare tire";
CM_ SG_ 773 TirePrssRR "Tire pressure rear right";
CM_ SG_ 773 TirePrssRL "Tire pressure rear left";
CM_ SG_ 773 TirePrssFR "Tire pressure front right";
CM_ SG_ 773 TirePrssFL "Tire pressure front left";
CM_ SG_ 773 Tire_Spr "Spare tire";
CM_ SG_ 773 Tire_RR "Tire rear right";
CM_ SG_ 773 Tire_RL "Tire rear left";
CM_ SG_ 773 Tire_FR "Tire front right";
CM_ SG_ 773 Tire_FL "Tire front left";
CM_ SG_ 773 RunFlatTire_Low "Run flat tire low pressure; true = [1]";
CM_ SG_ 766 VVT_IntCam2Pos "EDR ONLY - Centerline position for intake cam on bank 2";
CM_ SG_ 766 VVT_IntCam1Pos "EDR ONLY - Centerline position for intake cam on bank 1";
CM_ SG_ 766 VVT_ExhCam2Pos "EDR ONLY - Centerline position for exhaust cam on bank 2";
CM_ SG_ 766 VVT_ExhCam1Pos "EDR ONLY - Centerline position for exhaust cam on bank 1";
CM_ SG_ 766 RelativeThrtPct "EDR ONLY - Relative throttle percent";
CM_ SG_ 766 GF_Charge "EDR ONLY - Port flow per cylinder per stroke";
CM_ SG_ 764 RelativeThrt "EDR ONLY - Relative throttle value";
CM_ SG_ 764 RelativePdl "EDR ONLY - Relative pedal value";
CM_ SG_ 764 RawTPS2 "EDR ONLY - Raw throttle position sensor #2";
CM_ SG_ 764 RawTPS1 "EDR ONLY - Raw throttle position sensor #1";
CM_ SG_ 764 RawPVS2 "EDR ONLY - Raw pedal value sensor #2";
CM_ SG_ 764 RawPVS1 "EDR ONLY - Raw pedal value sensor #1";
CM_ SG_ 764 MAP "EDR ONLY - Intake manifold pressure";
CM_ SG_ 764 Lv1CrsCtrlOff "EDR ONLY - Level is requested cruise off";
CM_ SG_ 764 ETC_LmpOn "EDR ONLY - ETC lamp is on";
CM_ SG_ 764 ETC_LmpFlash "EDR ONLY - ETC lamp is flashing";
CM_ SG_ 764 ESP_TrqRqEnabl "EDR ONLY - ESP torque requests are allowed = [1]";
CM_ SG_ 764 CruiseEGD "EDR ONLY - Cruise system is engaged";
CM_ SG_ 764 BrkSw1Stat "EDR ONLY - Brake switch1 status, off = [0]";
CM_ SG_ 764 ApplyTrq "EDR ONLY - Torque may be applied to the wheels";
CM_ BO_ 761 "Tx Rate: 10ms, Std Dev: 0.3ms";
CM_ SG_ 760 MC_ECM_A3 "Message counter";
CM_ SG_ 760 ESS_ENG_ST "ESS Engine State";
CM_ SG_ 760 CRC_ECM_A3 "CRC-checksum byte 1 to 7 according to SAE J1850";
CM_ BO_ 754 "Tx Rate: 100ms, Std Dev: 5.4ms";
CM_ BO_ 752 "Tx Rate: 493ms, Std Dev: 60.2ms";
CM_ SG_ 746 ShftSensFltROT "Shift sensor single fault - rotary shifter, 1=fault";
CM_ SG_ 746 ShftLkFltROT "Shift lock fault - rotary shifter, 1=fault";
CM_ SG_ 746 ShftDispFltROT "Gear shifter display/trigger fault status - rotary shifter, 1=fault";
CM_ SG_ 746 RackFlt "Rack / detent sensor fault, 1=fault";
CM_ SG_ 746 MC_SBW_ROT1 "Message counter";
CM_ SG_ 746 DrvRqShftROT "Driver requested gear shift position";
CM_ SG_ 746 CRC_SBW_ROT1 "CRC-checksum byte 1 to 4 according to SAE J1850";
CM_ SG_ 746 APCM_Stat "Auto position correction mode status";
CM_ SG_ 746 x2EA_byte1_upper2 "added by New Eagle to ensure checksums arent messed up if FCA adds a new signal";
CM_ SG_ 746 x2EA_byte2 "added by New Eagle to ensure checksums arent messed up if FCA adds a new signal";
CM_ SG_ 746 x2EA_byte3_lower4 "added by New Eagle to ensure checksums arent messed up if FCA adds a new signal";
CM_ SG_ 746 x2EA_byte0_upper3 "added by New Eagle to ensure checksums arent messed up if FCA adds a new signal";
CM_ SG_ 746 x2EA_PrndManualUpDownPosn "Paddleshift requests on Grand Cherokee. ";
CM_ BO_ 738 "Tx Rate: 100ms, Std Dev: 5.4ms";
CM_ SG_ 737 MIL_OnRq_ESC "MIL on request from the ESC";
CM_ SG_ 737 ESCSysEmsMlfAtv "ESC emissions related malfunction active";
CM_ SG_ 736 YRS_DataRq "Request from ESC for YRS information";
CM_ SG_ 736 RT_DIST "Distance Traveled by Right Wheel. 2.5 cm per tooth on the encoder wheel";
CM_ SG_ 736 LT_DIST "Distance Traveled by Left Wheel. 2.5 cm per tooth on the encoder wheel";
CM_ SG_ 736 HSA_EN "Hill Start Assist enabled (1=enabled)";
CM_ SG_ 736 ESP_Off_IndLmp_On_Rq "ESP-OFF indication lamp on request";
CM_ SG_ 736 ESC_CtrlLmp_Info "ESC control lamp information";
CM_ SG_ 736 BrkIndLmp_On_Rq_ESC "Brake indication lamp (red) on request";
CM_ SG_ 736 ABS_IndLmp_On_Rq "ABS indication lamp on request";
CM_ SG_ 736 x2E0_byte7_HillDecentActive "values of 1 or 2 (not 3) will light the hill decent lamp on the cluster";
CM_ SG_ 736 x2E0_EscAndFcwFault "setting this chimes and lights an FCW fault lamp on the cluster, and flashes a \"Electronic Stability Control Off\" popup message";
CM_ SG_ 729 TorqueIntensitySts "LDW Torque Intesity Level";
CM_ SG_ 729 LDW_LEDControlSts "LDW switch LED status";
CM_ SG_ 729 HALF_AHB_On "Auto high beam on request from the HALF ECU";
CM_ SG_ 729 ConfigSts "LDW sensitivity level";
CM_ SG_ 720 BSM_SRV_RQ "BSM service warning request; 1= service request";
CM_ SG_ 720 BSM_RT_WRN "Blind spot detection Right side warning";
CM_ SG_ 720 BSM_OPR_STAT "BSM operation status; 1= operational failure";
CM_ SG_ 720 BSM_LT_WRN "Blind spot detection left side warning";
CM_ SG_ 720 BSM_CFG_STAT_TeenKey "BSM configuration status for teen key";
CM_ SG_ 720 BSM_CFG_STAT "BSM configuration status";
CM_ SG_ 720 BSM_Blind_RQ "Sensor blinded request from BSM; 1= sensor blocked request";
CM_ SG_ 719 PTS_DBD "Park assist system disabled; System_Disabled = [1]";
CM_ SG_ 719 PPPASystemFault "Indicates the fail status of PPPA; true = [1]";
CM_ SG_ 719 PPPAControlSts "Indicates the active state of PPPA; active = [1]";
CM_ SG_ 719 PPPA_STAT "Parallel & perpendicular park assist switch status";
CM_ SG_ 719 HMICode "HMI codes to be displayed";
CM_ SG_ 719 x2CF_byte1_middle4 "added by New Eagle to ensure checksums arent messed up if FCA adds a new signal";
CM_ SG_ 719 x2CF_byte2_upper7 "added by New Eagle to ensure checksums arent messed up if FCA adds a new signal";
CM_ SG_ 719 x2CF_byte3 "added by New Eagle to ensure checksums arent messed up if FCA adds a new signal";
CM_ SG_ 719 x2CF_byte4 "added by New Eagle to ensure checksums arent messed up if FCA adds a new signal";
CM_ SG_ 719 x2CF_byte5 "added by New Eagle to ensure checksums arent messed up if FCA adds a new signal";
CM_ SG_ 719 x2CF_byte6 "added by New Eagle to ensure checksums arent messed up if FCA adds a new signal";
CM_ SG_ 719 x2CF_byte7 "added by New Eagle to ensure checksums arent messed up if FCA adds a new signal";
CM_ SG_ 710 EC_PTS "Park assist ecu configuration";
CM_ SG_ 710 EC_ECUCfg17_Stat "ECU Configuration messages status 17";
CM_ SG_ 709 EC_ECUCfg16_Stat "ECU Configuration messages status 16";
CM_ SG_ 709 EC_AudTel3B "Audio and telematics ecu configuration 3B";
CM_ SG_ 709 EC_AudTel3A "Audio and telematics ecu configuration 3A";
CM_ SG_ 706 EC_Suspension "Suspension ecu configuration";
CM_ SG_ 706 EC_ECUCfg15_Stat "ECU Configuration messages status 15";
CM_ SG_ 706 EC_CBC15B "CBC ecu configuration 15B";
CM_ SG_ 706 EC_CBC15A "CBC ecu configuration 15A";
CM_ SG_ 705 VEH_INT_TEMP "Vehicle interior temperature";
CM_ SG_ 705 R_Temp1_Pos "Rear temperature 1 position";
CM_ SG_ 705 R_Blw1_Pos "Rear blower 1 position";
CM_ SG_ 705 HVAC_Blwr_Perct "HVAC blower PWM percentage for service mode";
CM_ SG_ 705 HtrCorTmp_InTgt "Heater core temp target";
CM_ BO_ 703 "Tx Rate: 100ms, Std Dev: 5.4ms";
CM_ BO_ 684 "Tx Rate: 971ms, Std Dev: 171.5ms";
CM_ BO_ 683 "Tx Rate: 100ms, Std Dev: 5.4ms";
BA_DEF_ SG_  "GenSigTimeout_CBC" INT 0 65535;
BA_DEF_ SG_  "GenSigTimeout_EPS" INT 0 65535;
BA_DEF_ SG_  "GenSigTimeout_ESM" INT 0 65535;
BA_DEF_ SG_  "GenSigTimeout_ETM" INT 0 65535;
BA_DEF_ SG_  "GenSigTimeout_HaLF" INT 0 65535;
BA_DEF_ SG_  "GenSigTimeout_IC" INT 0 65535;
BA_DEF_ SG_  "GenSigTimeout_OCM" INT 0 65535;
BA_DEF_ SG_  "GenSigTimeout_ORC" INT 0 65535;
BA_DEF_ SG_  "GenSigTimeout_PTS" INT 0 65535;
BA_DEF_ SG_  "GenSigTimeout_RF_HUB" INT 0 65535;
BA_DEF_ SG_  "GenSigTimeout_SCCM" INT 0 65535;
BA_DEF_ BO_  "GenMsgStartValue" STRING ;
BA_DEF_ SG_  "GenSigSNA" STRING ;
BA_DEF_ SG_  "RID" STRING ;
BA_DEF_ SG_  "FlexKomIsMotorola" ENUM  "nein","ja";
BA_DEF_ SG_  "FlexKomSigLaenge" INT 0 64;
BA_DEF_ SG_  "FlexKomSigStartPos" INT 0 63;
BA_DEF_ SG_  "FlexKomComment" STRING ;
BA_DEF_ SG_  "FlexKomSigName" STRING ;
BA_DEF_ SG_  "FlexKomSID" INT 0 2147483647;
BA_DEF_ SG_  "GenSigStartValue" HEX 0 -1;
BA_DEF_ SG_  "FlexKomSigStartValue" STRING ;
BA_DEF_ SG_  "GenSigCycleTime" INT 0 65535;
BA_DEF_ SG_  "GenSigSendType" ENUM  "cyclicX","spontanX","cyclicIfActiveX","spontanWithDelay","cyclicAndSpontanX","cyclicAndSpontanWithDelay","spontanWithRepitition","cyclicIfActiveAndSpontanWD","cyclicIfActiveFast","cyclicWithRepeatOnDemand","none";
BA_DEF_ BO_  "GenMsgNrOfRepetitions" INT 0 65535;
BA_DEF_ BO_  "GenMsgDelayTime" INT 0 65535;
BA_DEF_ BO_  "GenMsgStartDelayTime" INT 0 65535;
BA_DEF_ BO_  "GenMsgCycleTime" INT 0 65535;
BA_DEF_ BO_  "GenMsgSendType" ENUM  "cyclicX","spontanX","cyclicIfActiveX","spontanWithDelay","cyclicAndSpontanX","cyclicAndSpontanWithDelay","spontanWithRepitition","cyclicIfActiveAndSpontanWD","cyclicIfActiveFast","cyclicWithRepeatOnDemand","none";
BA_DEF_ BO_  "DiagResponse" ENUM  "nein","ja";
BA_DEF_ BO_  "DiagRequest" ENUM  "nein","ja";
BA_DEF_ BO_  "DiagState" ENUM  "nein","ja";
BA_DEF_ BO_  "App-Botschaft" ENUM  "nein","ja";
BA_DEF_ BO_  "NWM-Botschaft" ENUM  "nein","ja";
BA_DEF_DEF_  "GenSigTimeout_CBC" 0;
BA_DEF_DEF_  "GenSigTimeout_EPS" 0;
BA_DEF_DEF_  "GenSigTimeout_ESM" 0;
BA_DEF_DEF_  "GenSigTimeout_ETM" 0;
BA_DEF_DEF_  "GenSigTimeout_HaLF" 0;
BA_DEF_DEF_  "GenSigTimeout_IC" 0;
BA_DEF_DEF_  "GenSigTimeout_OCM" 0;
BA_DEF_DEF_  "GenSigTimeout_ORC" 0;
BA_DEF_DEF_  "GenSigTimeout_PTS" 0;
BA_DEF_DEF_  "GenSigTimeout_RF_HUB" 0;
BA_DEF_DEF_  "GenSigTimeout_SCCM" 0;
BA_DEF_DEF_  "GenMsgStartValue" "";
BA_DEF_DEF_  "GenSigSNA" "";
BA_DEF_DEF_  "RID" "";
BA_DEF_DEF_  "FlexKomIsMotorola" "nein";
BA_DEF_DEF_  "FlexKomSigLaenge" 0;
BA_DEF_DEF_  "FlexKomSigStartPos" 0;
BA_DEF_DEF_  "FlexKomComment" "";
BA_DEF_DEF_  "FlexKomSigName" "";
BA_DEF_DEF_  "FlexKomSID" 0;
BA_DEF_DEF_  "GenSigStartValue" 0;
BA_DEF_DEF_  "FlexKomSigStartValue" "";
BA_DEF_DEF_  "GenSigCycleTime" 0;
BA_DEF_DEF_  "GenSigSendType" "cyclicX";
BA_DEF_DEF_  "GenMsgNrOfRepetitions" 0;
BA_DEF_DEF_  "GenMsgDelayTime" 0;
BA_DEF_DEF_  "GenMsgStartDelayTime" 0;
BA_DEF_DEF_  "GenMsgCycleTime" 0;
BA_DEF_DEF_  "GenMsgSendType" "cyclicX";
BA_DEF_DEF_  "DiagResponse" "nein";
BA_DEF_DEF_  "DiagRequest" "nein";
BA_DEF_DEF_  "DiagState" "nein";
BA_DEF_DEF_  "App-Botschaft" "nein";
BA_DEF_DEF_  "NWM-Botschaft" "nein";
BA_ "GenMsgStartValue" BO_ 863 "000000000000FFFFh";
BA_ "GenMsgNrOfRepetitions" BO_ 863 2;
BA_ "GenMsgDelayTime" BO_ 863 20;
BA_ "GenMsgCycleTime" BO_ 863 100;
BA_ "GenSigSNA" SG_ 863 RevOilLifeRst "FFFFh";
BA_ "FlexKomIsMotorola" SG_ 863 RevOilLifeRst 1;
BA_ "FlexKomComment" SG_ 863 RevOilLifeRst "Engine revolutions since last oil life reset";
BA_ "FlexKomSigName" SG_ 863 RevOilLifeRst "RevOilLifeRst";
BA_ "FlexKomSigLaenge" SG_ 863 RevOilLifeRst 16;
BA_ "FlexKomSigStartPos" SG_ 863 RevOilLifeRst 55;
BA_ "FlexKomSID" SG_ 863 RevOilLifeRst 2109;
BA_ "GenSigTimeout_CBC" SG_ 863 RevOilLifeRst 1050;
BA_ "GenSigStartValue" SG_ 863 RevOilLifeRst 65535;
BA_ "FlexKomSigStartValue" SG_ 863 RevOilLifeRst "FFFFh";
BA_ "GenSigCycleTime" SG_ 863 RevOilLifeRst 100;
BA_ "GenMsgStartValue" BO_ 860 "000000000FFFh";
BA_ "GenMsgNrOfRepetitions" BO_ 860 2;
BA_ "GenMsgDelayTime" BO_ 860 20;
BA_ "GenMsgCycleTime" BO_ 860 1000;
BA_ "GenMsgSendType" BO_ 860 5;
BA_ "GenSigSNA" SG_ 860 UNITS "7h";
BA_ "FlexKomIsMotorola" SG_ 860 UNITS 1;
BA_ "FlexKomComment" SG_ 860 UNITS "Navigation turn information packet";
BA_ "FlexKomSigName" SG_ 860 UNITS "TURN_INFO";
BA_ "FlexKomSigLaenge" SG_ 860 UNITS 32;
BA_ "FlexKomSigStartPos" SG_ 860 UNITS 7;
BA_ "FlexKomSID" SG_ 860 UNITS 986;
BA_ "GenSigTimeout_IC" SG_ 860 UNITS 10500;
BA_ "FlexKomSigStartValue" SG_ 860 UNITS "00000000h";
BA_ "GenSigCycleTime" SG_ 860 UNITS 1000;
BA_ "GenSigSendType" SG_ 860 UNITS 5;
BA_ "GenSigSNA" SG_ 860 TURN_COMP "0h";
BA_ "FlexKomIsMotorola" SG_ 860 TURN_COMP 1;
BA_ "FlexKomComment" SG_ 860 TURN_COMP "Navigation turn information packet";
BA_ "FlexKomSigName" SG_ 860 TURN_COMP "TURN_INFO";
BA_ "FlexKomSigLaenge" SG_ 860 TURN_COMP 32;
BA_ "FlexKomSigStartPos" SG_ 860 TURN_COMP 7;
BA_ "FlexKomSID" SG_ 860 TURN_COMP 986;
BA_ "GenSigTimeout_IC" SG_ 860 TURN_COMP 10500;
BA_ "FlexKomSigStartValue" SG_ 860 TURN_COMP "00000000h";
BA_ "GenSigCycleTime" SG_ 860 TURN_COMP 1000;
BA_ "GenSigSendType" SG_ 860 TURN_COMP 5;
BA_ "GenSigSNA" SG_ 860 T_BY_T_ON "0h";
BA_ "FlexKomIsMotorola" SG_ 860 T_BY_T_ON 1;
BA_ "FlexKomComment" SG_ 860 T_BY_T_ON "Navigation turn information packet";
BA_ "FlexKomSigName" SG_ 860 T_BY_T_ON "TURN_INFO";
BA_ "FlexKomSigLaenge" SG_ 860 T_BY_T_ON 32;
BA_ "FlexKomSigStartPos" SG_ 860 T_BY_T_ON 7;
BA_ "FlexKomSID" SG_ 860 T_BY_T_ON 986;
BA_ "GenSigTimeout_IC" SG_ 860 T_BY_T_ON 10500;
BA_ "FlexKomSigStartValue" SG_ 860 T_BY_T_ON "00000000h";
BA_ "GenSigCycleTime" SG_ 860 T_BY_T_ON 1000;
BA_ "GenSigSendType" SG_ 860 T_BY_T_ON 5;
BA_ "GenSigSNA" SG_ 860 NAVPrsnt "0h";
BA_ "FlexKomIsMotorola" SG_ 860 NAVPrsnt 1;
BA_ "FlexKomComment" SG_ 860 NAVPrsnt "Navigation turn information packet";
BA_ "FlexKomSigName" SG_ 860 NAVPrsnt "TURN_INFO";
BA_ "FlexKomSigLaenge" SG_ 860 NAVPrsnt 32;
BA_ "FlexKomSigStartPos" SG_ 860 NAVPrsnt 7;
BA_ "FlexKomSID" SG_ 860 NAVPrsnt 986;
BA_ "FlexKomSigStartValue" SG_ 860 NAVPrsnt "00000000h";
BA_ "GenSigCycleTime" SG_ 860 NAVPrsnt 1000;
BA_ "GenSigSendType" SG_ 860 NAVPrsnt 5;
BA_ "GenSigSNA" SG_ 860 NAV_ARROW "0h";
BA_ "FlexKomIsMotorola" SG_ 860 NAV_ARROW 1;
BA_ "FlexKomComment" SG_ 860 NAV_ARROW "Navigation turn information packet";
BA_ "FlexKomSigName" SG_ 860 NAV_ARROW "TURN_INFO";
BA_ "FlexKomSigLaenge" SG_ 860 NAV_ARROW 32;
BA_ "FlexKomSigStartPos" SG_ 860 NAV_ARROW 7;
BA_ "FlexKomSID" SG_ 860 NAV_ARROW 986;
BA_ "GenSigTimeout_IC" SG_ 860 NAV_ARROW 10500;
BA_ "FlexKomSigStartValue" SG_ 860 NAV_ARROW "00000000h";
BA_ "GenSigCycleTime" SG_ 860 NAV_ARROW 1000;
BA_ "GenSigSendType" SG_ 860 NAV_ARROW 5;
BA_ "GenSigSNA" SG_ 860 DIST_TO_TURN "FFFFh";
BA_ "FlexKomIsMotorola" SG_ 860 DIST_TO_TURN 1;
BA_ "FlexKomComment" SG_ 860 DIST_TO_TURN "Navigation turn information packet";
BA_ "FlexKomSigName" SG_ 860 DIST_TO_TURN "TURN_INFO";
BA_ "FlexKomSigLaenge" SG_ 860 DIST_TO_TURN 32;
BA_ "FlexKomSigStartPos" SG_ 860 DIST_TO_TURN 7;
BA_ "FlexKomSID" SG_ 860 DIST_TO_TURN 986;
BA_ "GenSigTimeout_IC" SG_ 860 DIST_TO_TURN 10500;
BA_ "FlexKomSigStartValue" SG_ 860 DIST_TO_TURN "00000000h";
BA_ "GenSigCycleTime" SG_ 860 DIST_TO_TURN 1000;
BA_ "GenSigSendType" SG_ 860 DIST_TO_TURN 5;
BA_ "GenMsgStartDelayTime" BO_ 856 50;
BA_ "GenMsgStartValue" BO_ 856 "FF000000h";
BA_ "GenMsgNrOfRepetitions" BO_ 856 2;
BA_ "GenMsgDelayTime" BO_ 856 20;
BA_ "GenMsgCycleTime" BO_ 856 1000;
BA_ "GenSigSNA" SG_ 856 CMP_DIR "Fh";
BA_ "FlexKomIsMotorola" SG_ 856 CMP_DIR 1;
BA_ "FlexKomComment" SG_ 856 CMP_DIR "Compass direction (WK/LX)";
BA_ "FlexKomSigName" SG_ 856 CMP_DIR "CMP_DIR";
BA_ "FlexKomSigLaenge" SG_ 856 CMP_DIR 4;
BA_ "FlexKomSigStartPos" SG_ 856 CMP_DIR 3;
BA_ "FlexKomSID" SG_ 856 CMP_DIR 817;
BA_ "GenSigTimeout_IC" SG_ 856 CMP_DIR 10500;
BA_ "GenSigStartValue" SG_ 856 CMP_DIR 15;
BA_ "FlexKomSigStartValue" SG_ 856 CMP_DIR "0Fh";
BA_ "GenSigCycleTime" SG_ 856 CMP_DIR 1000;
BA_ "GenMsgStartDelayTime" BO_ 853 100;
BA_ "GenMsgStartValue" BO_ 853 "F0FF0300000C00FFh";
BA_ "GenMsgNrOfRepetitions" BO_ 853 2;
BA_ "GenMsgDelayTime" BO_ 853 20;
BA_ "GenMsgCycleTime" BO_ 853 1000;
BA_ "GenMsgSendType" BO_ 853 5;
BA_ "GenSigSNA" SG_ 853 IBS_IBATT_QUIESCENT "FFh";
BA_ "FlexKomIsMotorola" SG_ 853 IBS_IBATT_QUIESCENT 1;
BA_ "FlexKomComment" SG_ 853 IBS_IBATT_QUIESCENT "Battery quiescent current";
BA_ "FlexKomSigName" SG_ 853 IBS_IBATT_QUIESCENT "IBS_IBATT_QUIESCENT";
BA_ "FlexKomSigLaenge" SG_ 853 IBS_IBATT_QUIESCENT 8;
BA_ "FlexKomSigStartPos" SG_ 853 IBS_IBATT_QUIESCENT 63;
BA_ "FlexKomSID" SG_ 853 IBS_IBATT_QUIESCENT 1854;
BA_ "GenSigStartValue" SG_ 853 IBS_IBATT_QUIESCENT 255;
BA_ "FlexKomSigStartValue" SG_ 853 IBS_IBATT_QUIESCENT "FFh";
BA_ "GenSigCycleTime" SG_ 853 IBS_IBATT_QUIESCENT 1000;
BA_ "GenMsgStartValue" BO_ 848 "FFFFFFFFFFFFFF3Fh";
BA_ "GenMsgNrOfRepetitions" BO_ 848 2;
BA_ "GenMsgDelayTime" BO_ 848 20;
BA_ "GenMsgCycleTime" BO_ 848 1000;
BA_ "GenSigSNA" SG_ 848 DateTmYear "FFFFh";
BA_ "FlexKomIsMotorola" SG_ 848 DateTmYear 1;
BA_ "FlexKomComment" SG_ 848 DateTmYear "DATE";
BA_ "FlexKomSigName" SG_ 848 DateTmYear "DATE";
BA_ "FlexKomSigLaenge" SG_ 848 DateTmYear 32;
BA_ "FlexKomSigStartPos" SG_ 848 DateTmYear 31;
BA_ "FlexKomSID" SG_ 848 DateTmYear 645;
BA_ "GenSigTimeout_IC" SG_ 848 DateTmYear 10500;
BA_ "GenSigTimeout_RF_HUB" SG_ 848 DateTmYear 10500;
BA_ "GenSigStartValue" SG_ 848 DateTmYear 65535;
BA_ "FlexKomSigStartValue" SG_ 848 DateTmYear "FFFFFFFFh";
BA_ "GenSigCycleTime" SG_ 848 DateTmYear 1000;
BA_ "GenSigSNA" SG_ 848 DateTmSec "FFh";
BA_ "FlexKomIsMotorola" SG_ 848 DateTmSec 1;
BA_ "FlexKomComment" SG_ 848 DateTmSec "Time of day clock";
BA_ "FlexKomSigName" SG_ 848 DateTmSec "Clock";
BA_ "FlexKomSigLaenge" SG_ 848 DateTmSec 24;
BA_ "FlexKomSigStartPos" SG_ 848 DateTmSec 7;
BA_ "FlexKomSID" SG_ 848 DateTmSec 398;
BA_ "GenSigTimeout_IC" SG_ 848 DateTmSec 10500;
BA_ "GenSigTimeout_RF_HUB" SG_ 848 DateTmSec 10500;
BA_ "GenSigStartValue" SG_ 848 DateTmSec 255;
BA_ "FlexKomSigStartValue" SG_ 848 DateTmSec "FFFFFFh";
BA_ "GenSigCycleTime" SG_ 848 DateTmSec 1000;
BA_ "GenSigSNA" SG_ 848 DateTmMonth "FFh";
BA_ "FlexKomIsMotorola" SG_ 848 DateTmMonth 1;
BA_ "FlexKomComment" SG_ 848 DateTmMonth "DATE";
BA_ "FlexKomSigName" SG_ 848 DateTmMonth "DATE";
BA_ "FlexKomSigLaenge" SG_ 848 DateTmMonth 32;
BA_ "FlexKomSigStartPos" SG_ 848 DateTmMonth 31;
BA_ "FlexKomSID" SG_ 848 DateTmMonth 645;
BA_ "GenSigTimeout_IC" SG_ 848 DateTmMonth 10500;
BA_ "GenSigTimeout_RF_HUB" SG_ 848 DateTmMonth 10500;
BA_ "GenSigStartValue" SG_ 848 DateTmMonth 255;
BA_ "FlexKomSigStartValue" SG_ 848 DateTmMonth "FFFFFFFFh";
BA_ "GenSigCycleTime" SG_ 848 DateTmMonth 1000;
BA_ "GenSigSNA" SG_ 848 DateTmMinute "FFh";
BA_ "FlexKomIsMotorola" SG_ 848 DateTmMinute 1;
BA_ "FlexKomComment" SG_ 848 DateTmMinute "Time of day clock";
BA_ "FlexKomSigName" SG_ 848 DateTmMinute "Clock";
BA_ "FlexKomSigLaenge" SG_ 848 DateTmMinute 24;
BA_ "FlexKomSigStartPos" SG_ 848 DateTmMinute 7;
BA_ "FlexKomSID" SG_ 848 DateTmMinute 398;
BA_ "GenSigTimeout_IC" SG_ 848 DateTmMinute 10500;
BA_ "GenSigTimeout_RF_HUB" SG_ 848 DateTmMinute 10500;
BA_ "GenSigStartValue" SG_ 848 DateTmMinute 255;
BA_ "FlexKomSigStartValue" SG_ 848 DateTmMinute "FFFFFFh";
BA_ "GenSigCycleTime" SG_ 848 DateTmMinute 1000;
BA_ "GenSigSNA" SG_ 848 DateTmHour "FFh";
BA_ "FlexKomIsMotorola" SG_ 848 DateTmHour 1;
BA_ "FlexKomComment" SG_ 848 DateTmHour "Time of day clock";
BA_ "FlexKomSigName" SG_ 848 DateTmHour "Clock";
BA_ "FlexKomSigLaenge" SG_ 848 DateTmHour 24;
BA_ "FlexKomSigStartPos" SG_ 848 DateTmHour 7;
BA_ "FlexKomSID" SG_ 848 DateTmHour 398;
BA_ "GenSigTimeout_IC" SG_ 848 DateTmHour 10500;
BA_ "GenSigTimeout_RF_HUB" SG_ 848 DateTmHour 10500;
BA_ "GenSigStartValue" SG_ 848 DateTmHour 255;
BA_ "FlexKomSigStartValue" SG_ 848 DateTmHour "FFFFFFh";
BA_ "GenSigCycleTime" SG_ 848 DateTmHour 1000;
BA_ "GenSigSNA" SG_ 848 DateTmFormat "7h";
BA_ "FlexKomIsMotorola" SG_ 848 DateTmFormat 1;
BA_ "FlexKomComment" SG_ 848 DateTmFormat "Date and Time Format";
BA_ "FlexKomSigName" SG_ 848 DateTmFormat "DateTmFormat";
BA_ "FlexKomSigLaenge" SG_ 848 DateTmFormat 3;
BA_ "FlexKomSigStartPos" SG_ 848 DateTmFormat 58;
BA_ "FlexKomSID" SG_ 848 DateTmFormat 971;
BA_ "GenSigTimeout_IC" SG_ 848 DateTmFormat 10500;
BA_ "GenSigStartValue" SG_ 848 DateTmFormat 7;
BA_ "FlexKomSigStartValue" SG_ 848 DateTmFormat "07h";
BA_ "GenSigCycleTime" SG_ 848 DateTmFormat 1000;
BA_ "GenSigSNA" SG_ 848 DateTmDay "FFh";
BA_ "FlexKomIsMotorola" SG_ 848 DateTmDay 1;
BA_ "FlexKomComment" SG_ 848 DateTmDay "DATE";
BA_ "FlexKomSigName" SG_ 848 DateTmDay "DATE";
BA_ "FlexKomSigLaenge" SG_ 848 DateTmDay 32;
BA_ "FlexKomSigStartPos" SG_ 848 DateTmDay 31;
BA_ "FlexKomSID" SG_ 848 DateTmDay 645;
BA_ "GenSigTimeout_IC" SG_ 848 DateTmDay 10500;
BA_ "GenSigTimeout_RF_HUB" SG_ 848 DateTmDay 10500;
BA_ "GenSigStartValue" SG_ 848 DateTmDay 255;
BA_ "FlexKomSigStartValue" SG_ 848 DateTmDay "FFFFFFFFh";
BA_ "GenSigCycleTime" SG_ 848 DateTmDay 1000;
BA_ "GenMsgStartValue" BO_ 840 "0000000000000000h";
BA_ "GenMsgNrOfRepetitions" BO_ 840 2;
BA_ "GenMsgDelayTime" BO_ 840 20;
BA_ "GenMsgSendType" BO_ 840 1;
BA_ "GenSigSNA" SG_ 840 FailSafeError "FFFFh";
BA_ "FlexKomIsMotorola" SG_ 840 FailSafeError 1;
BA_ "FlexKomComment" SG_ 840 FailSafeError "Fail safe error";
BA_ "FlexKomSigName" SG_ 840 FailSafeError "FailSafeError";
BA_ "FlexKomSigLaenge" SG_ 840 FailSafeError 16;
BA_ "FlexKomSigStartPos" SG_ 840 FailSafeError 7;
BA_ "FlexKomSID" SG_ 840 FailSafeError 13;
BA_ "FlexKomSigStartValue" SG_ 840 FailSafeError "0000h";
BA_ "GenSigSendType" SG_ 840 FailSafeError 1;
BA_ "GenMsgStartValue" BO_ 838 "0000h";
BA_ "GenMsgNrOfRepetitions" BO_ 838 2;
BA_ "GenMsgDelayTime" BO_ 838 20;
BA_ "GenMsgCycleTime" BO_ 838 1000;
BA_ "GenMsgSendType" BO_ 838 5;
BA_ "GenSigSNA" SG_ 838 AS_RF_CHIME_RQ "0h";
BA_ "FlexKomIsMotorola" SG_ 838 AS_RF_CHIME_RQ 1;
BA_ "FlexKomComment" SG_ 838 AS_RF_CHIME_RQ "AS chime status";
BA_ "FlexKomSigName" SG_ 838 AS_RF_CHIME_RQ "AS_CHIME_STAT";
BA_ "FlexKomSigLaenge" SG_ 838 AS_RF_CHIME_RQ 16;
BA_ "FlexKomSigStartPos" SG_ 838 AS_RF_CHIME_RQ 7;
BA_ "FlexKomSID" SG_ 838 AS_RF_CHIME_RQ 1016;
BA_ "FlexKomSigStartValue" SG_ 838 AS_RF_CHIME_RQ "0000h";
BA_ "GenSigCycleTime" SG_ 838 AS_RF_CHIME_RQ 1000;
BA_ "GenSigSendType" SG_ 838 AS_RF_CHIME_RQ 5;
BA_ "GenSigSNA" SG_ 838 AS_LF_CHIME_RQ "0h";
BA_ "FlexKomIsMotorola" SG_ 838 AS_LF_CHIME_RQ 1;
BA_ "FlexKomComment" SG_ 838 AS_LF_CHIME_RQ "AS chime status";
BA_ "FlexKomSigName" SG_ 838 AS_LF_CHIME_RQ "AS_CHIME_STAT";
BA_ "FlexKomSigLaenge" SG_ 838 AS_LF_CHIME_RQ 16;
BA_ "FlexKomSigStartPos" SG_ 838 AS_LF_CHIME_RQ 7;
BA_ "FlexKomSID" SG_ 838 AS_LF_CHIME_RQ 1016;
BA_ "FlexKomSigStartValue" SG_ 838 AS_LF_CHIME_RQ "0000h";
BA_ "GenSigCycleTime" SG_ 838 AS_LF_CHIME_RQ 1000;
BA_ "GenSigSendType" SG_ 838 AS_LF_CHIME_RQ 5;
BA_ "GenSigSNA" SG_ 838 AS_CHIME_TYPE "Fh";
BA_ "FlexKomIsMotorola" SG_ 838 AS_CHIME_TYPE 1;
BA_ "FlexKomComment" SG_ 838 AS_CHIME_TYPE "AS chime status";
BA_ "FlexKomSigName" SG_ 838 AS_CHIME_TYPE "AS_CHIME_STAT";
BA_ "FlexKomSigLaenge" SG_ 838 AS_CHIME_TYPE 16;
BA_ "FlexKomSigStartPos" SG_ 838 AS_CHIME_TYPE 7;
BA_ "FlexKomSID" SG_ 838 AS_CHIME_TYPE 1016;
BA_ "GenSigTimeout_ORC" SG_ 838 AS_CHIME_TYPE 3500;
BA_ "GenSigTimeout_IC" SG_ 838 AS_CHIME_TYPE 10500;
BA_ "FlexKomSigStartValue" SG_ 838 AS_CHIME_TYPE "0000h";
BA_ "GenSigCycleTime" SG_ 838 AS_CHIME_TYPE 1000;
BA_ "GenSigSendType" SG_ 838 AS_CHIME_TYPE 5;
BA_ "GenMsgStartValue" BO_ 832 "FFFF0FFF0000FFFFh";
BA_ "GenMsgNrOfRepetitions" BO_ 832 2;
BA_ "GenMsgDelayTime" BO_ 832 20;
BA_ "GenMsgCycleTime" BO_ 832 500;
BA_ "GenSigSNA" SG_ 832 VehSpdDisp "FFFFh";
BA_ "FlexKomIsMotorola" SG_ 832 VehSpdDisp 1;
BA_ "FlexKomComment" SG_ 832 VehSpdDisp "Vehicle speed - displayed";
BA_ "FlexKomSigName" SG_ 832 VehSpdDisp "VehSpdDisp";
BA_ "FlexKomSigLaenge" SG_ 832 VehSpdDisp 16;
BA_ "FlexKomSigStartPos" SG_ 832 VehSpdDisp 55;
BA_ "FlexKomSID" SG_ 832 VehSpdDisp 1430;
BA_ "GenSigTimeout_CBC" SG_ 832 VehSpdDisp 5250;
BA_ "GenSigStartValue" SG_ 832 VehSpdDisp 65535;
BA_ "FlexKomSigStartValue" SG_ 832 VehSpdDisp "FFFFh";
BA_ "GenSigCycleTime" SG_ 832 VehSpdDisp 500;
BA_ "GenSigSNA" SG_ 832 VehSpd_MPH "0h";
BA_ "FlexKomIsMotorola" SG_ 832 VehSpd_MPH 1;
BA_ "FlexKomComment" SG_ 832 VehSpd_MPH "Vehicle speed signal is in miles per hour format";
BA_ "FlexKomSigName" SG_ 832 VehSpd_MPH "VehSpd_MPH";
BA_ "FlexKomSigLaenge" SG_ 832 VehSpd_MPH 1;
BA_ "FlexKomSigStartPos" SG_ 832 VehSpd_MPH 47;
BA_ "FlexKomSID" SG_ 832 VehSpd_MPH 1585;
BA_ "FlexKomSigStartValue" SG_ 832 VehSpd_MPH "00h";
BA_ "GenSigCycleTime" SG_ 832 VehSpd_MPH 500;
BA_ "GenSigCycleTime" SG_ 832 Est_Range_Disp 500;
BA_ "FlexKomSigStartValue" SG_ 832 Est_Range_Disp "00h";
BA_ "GenSigTimeout_ETM" SG_ 832 Est_Range_Disp 5250;
BA_ "FlexKomSID" SG_ 832 Est_Range_Disp 2543;
BA_ "FlexKomSigStartPos" SG_ 832 Est_Range_Disp 39;
BA_ "FlexKomSigLaenge" SG_ 832 Est_Range_Disp 8;
BA_ "FlexKomSigName" SG_ 832 Est_Range_Disp "Est_Range_Disp";
BA_ "FlexKomIsMotorola" SG_ 832 Est_Range_Disp 1;
BA_ "GenSigSNA" SG_ 832 Est_Range_Disp "FFh";
BA_ "FlexKomComment" SG_ 832 Est_Range_Disp "Estimated electric range for display";
BA_ "GenMsgStartValue" BO_ 826 "00F0F0F0F0F0F000h";
BA_ "GenMsgNrOfRepetitions" BO_ 826 2;
BA_ "GenMsgDelayTime" BO_ 826 20;
BA_ "GenMsgCycleTime" BO_ 826 500;
BA_ "GenMsgSendType" BO_ 826 5;
BA_ "GenSigSNA" SG_ 826 PTS_STAT "3h";
BA_ "FlexKomIsMotorola" SG_ 826 PTS_STAT 1;
BA_ "FlexKomComment" SG_ 826 PTS_STAT "Park Assist System - LED control status";
BA_ "FlexKomSigName" SG_ 826 PTS_STAT "PTS_STAT";
BA_ "FlexKomSigLaenge" SG_ 826 PTS_STAT 2;
BA_ "FlexKomSigStartPos" SG_ 826 PTS_STAT 61;
BA_ "FlexKomSID" SG_ 826 PTS_STAT 1862;
BA_ "GenSigTimeout_CBC" SG_ 826 PTS_STAT 5250;
BA_ "FlexKomSigStartValue" SG_ 826 PTS_STAT "00h";
BA_ "GenSigCycleTime" SG_ 826 PTS_STAT 500;
BA_ "GenSigSendType" SG_ 826 PTS_STAT 5;
BA_ "GenSigSNA" SG_ 826 PTS_SRV_RQ "0h";
BA_ "FlexKomIsMotorola" SG_ 826 PTS_SRV_RQ 1;
BA_ "FlexKomComment" SG_ 826 PTS_SRV_RQ "PTS service warning request; True = [1]";
BA_ "FlexKomSigName" SG_ 826 PTS_SRV_RQ "PTS_SRV_RQ";
BA_ "FlexKomSigLaenge" SG_ 826 PTS_SRV_RQ 1;
BA_ "FlexKomSigStartPos" SG_ 826 PTS_SRV_RQ 5;
BA_ "FlexKomSID" SG_ 826 PTS_SRV_RQ 54;
BA_ "GenSigTimeout_IC" SG_ 826 PTS_SRV_RQ 5250;
BA_ "FlexKomSigStartValue" SG_ 826 PTS_SRV_RQ "00h";
BA_ "GenSigCycleTime" SG_ 826 PTS_SRV_RQ 500;
BA_ "GenSigSendType" SG_ 826 PTS_SRV_RQ 5;
BA_ "GenSigSNA" SG_ 826 PTS_RR_SRV "0h";
BA_ "FlexKomIsMotorola" SG_ 826 PTS_RR_SRV 1;
BA_ "FlexKomComment" SG_ 826 PTS_RR_SRV "Rear PTS sensor service request; True = [1]";
BA_ "FlexKomSigName" SG_ 826 PTS_RR_SRV "PTS_RR_SRV";
BA_ "FlexKomSigLaenge" SG_ 826 PTS_RR_SRV 1;
BA_ "FlexKomSigStartPos" SG_ 826 PTS_RR_SRV 59;
BA_ "FlexKomSID" SG_ 826 PTS_RR_SRV 1353;
BA_ "GenSigTimeout_IC" SG_ 826 PTS_RR_SRV 5250;
BA_ "FlexKomSigStartValue" SG_ 826 PTS_RR_SRV "00h";
BA_ "GenSigCycleTime" SG_ 826 PTS_RR_SRV 500;
BA_ "GenSigSendType" SG_ 826 PTS_RR_SRV 5;
BA_ "GenSigSNA" SG_ 826 PTS_RR_NA "0h";
BA_ "FlexKomIsMotorola" SG_ 826 PTS_RR_NA 1;
BA_ "FlexKomComment" SG_ 826 PTS_RR_NA "Rear park assist not available - blinded sensor; T";
BA_ "FlexKomSigName" SG_ 826 PTS_RR_NA "PTS_RR_NA";
BA_ "FlexKomSigLaenge" SG_ 826 PTS_RR_NA 1;
BA_ "FlexKomSigStartPos" SG_ 826 PTS_RR_NA 4;
BA_ "FlexKomSID" SG_ 826 PTS_RR_NA 1315;
BA_ "GenSigTimeout_IC" SG_ 826 PTS_RR_NA 5250;
BA_ "FlexKomSigStartValue" SG_ 826 PTS_RR_NA "00h";
BA_ "GenSigCycleTime" SG_ 826 PTS_RR_NA 500;
BA_ "GenSigSendType" SG_ 826 PTS_RR_NA 5;
BA_ "GenSigSNA" SG_ 826 PTS_GraphicRR "3h";
BA_ "FlexKomIsMotorola" SG_ 826 PTS_GraphicRR 1;
BA_ "FlexKomComment" SG_ 826 PTS_GraphicRR "Park assist rear right warnings";
BA_ "FlexKomSigName" SG_ 826 PTS_GraphicRR "PTS_RR";
BA_ "FlexKomSigLaenge" SG_ 826 PTS_GraphicRR 8;
BA_ "FlexKomSigStartPos" SG_ 826 PTS_GraphicRR 39;
BA_ "FlexKomSID" SG_ 826 PTS_GraphicRR 1120;
BA_ "GenSigTimeout_IC" SG_ 826 PTS_GraphicRR 5250;
BA_ "GenSigStartValue" SG_ 826 PTS_GraphicRR 3;
BA_ "FlexKomSigStartValue" SG_ 826 PTS_GraphicRR "F0h";
BA_ "GenSigCycleTime" SG_ 826 PTS_GraphicRR 500;
BA_ "GenSigSendType" SG_ 826 PTS_GraphicRR 5;
BA_ "GenSigSNA" SG_ 826 PTS_GraphicRL "3h";
BA_ "FlexKomIsMotorola" SG_ 826 PTS_GraphicRL 1;
BA_ "FlexKomComment" SG_ 826 PTS_GraphicRL "Park assist rear left warnings";
BA_ "FlexKomSigName" SG_ 826 PTS_GraphicRL "PTS_RL";
BA_ "FlexKomSigLaenge" SG_ 826 PTS_GraphicRL 8;
BA_ "FlexKomSigStartPos" SG_ 826 PTS_GraphicRL 31;
BA_ "FlexKomSID" SG_ 826 PTS_GraphicRL 1119;
BA_ "GenSigTimeout_IC" SG_ 826 PTS_GraphicRL 5250;
BA_ "GenSigStartValue" SG_ 826 PTS_GraphicRL 3;
BA_ "FlexKomSigStartValue" SG_ 826 PTS_GraphicRL "F0h";
BA_ "GenSigCycleTime" SG_ 826 PTS_GraphicRL 500;
BA_ "GenSigSendType" SG_ 826 PTS_GraphicRL 5;
BA_ "GenSigSNA" SG_ 826 PTS_GraphicRC "3h";
BA_ "FlexKomIsMotorola" SG_ 826 PTS_GraphicRC 1;
BA_ "FlexKomComment" SG_ 826 PTS_GraphicRC "Park assist rear center warnings";
BA_ "FlexKomSigName" SG_ 826 PTS_GraphicRC "PTS_RC";
BA_ "FlexKomSigLaenge" SG_ 826 PTS_GraphicRC 8;
BA_ "FlexKomSigStartPos" SG_ 826 PTS_GraphicRC 55;
BA_ "FlexKomSID" SG_ 826 PTS_GraphicRC 1123;
BA_ "GenSigTimeout_IC" SG_ 826 PTS_GraphicRC 5250;
BA_ "GenSigStartValue" SG_ 826 PTS_GraphicRC 3;
BA_ "FlexKomSigStartValue" SG_ 826 PTS_GraphicRC "F0h";
BA_ "GenSigCycleTime" SG_ 826 PTS_GraphicRC 500;
BA_ "GenSigSendType" SG_ 826 PTS_GraphicRC 5;
BA_ "GenSigSNA" SG_ 826 PTS_GraphicFR "3h";
BA_ "FlexKomIsMotorola" SG_ 826 PTS_GraphicFR 1;
BA_ "FlexKomComment" SG_ 826 PTS_GraphicFR "Park assist front right warnings";
BA_ "FlexKomSigName" SG_ 826 PTS_GraphicFR "PTS_FR";
BA_ "FlexKomSigLaenge" SG_ 826 PTS_GraphicFR 8;
BA_ "FlexKomSigStartPos" SG_ 826 PTS_GraphicFR 23;
BA_ "FlexKomSID" SG_ 826 PTS_GraphicFR 1118;
BA_ "GenSigTimeout_IC" SG_ 826 PTS_GraphicFR 5250;
BA_ "GenSigStartValue" SG_ 826 PTS_GraphicFR 3;
BA_ "FlexKomSigStartValue" SG_ 826 PTS_GraphicFR "F0h";
BA_ "GenSigCycleTime" SG_ 826 PTS_GraphicFR 500;
BA_ "GenSigSendType" SG_ 826 PTS_GraphicFR 5;
BA_ "GenSigSNA" SG_ 826 PTS_GraphicFL "3h";
BA_ "FlexKomIsMotorola" SG_ 826 PTS_GraphicFL 1;
BA_ "FlexKomComment" SG_ 826 PTS_GraphicFL "Park assist front left warnings";
BA_ "FlexKomSigName" SG_ 826 PTS_GraphicFL "PTS_FL";
BA_ "FlexKomSigLaenge" SG_ 826 PTS_GraphicFL 8;
BA_ "FlexKomSigStartPos" SG_ 826 PTS_GraphicFL 15;
BA_ "FlexKomSID" SG_ 826 PTS_GraphicFL 1117;
BA_ "GenSigTimeout_IC" SG_ 826 PTS_GraphicFL 5250;
BA_ "GenSigStartValue" SG_ 826 PTS_GraphicFL 3;
BA_ "FlexKomSigStartValue" SG_ 826 PTS_GraphicFL "F0h";
BA_ "GenSigCycleTime" SG_ 826 PTS_GraphicFL 500;
BA_ "GenSigSendType" SG_ 826 PTS_GraphicFL 5;
BA_ "GenSigSNA" SG_ 826 PTS_GraphicFC "3h";
BA_ "FlexKomIsMotorola" SG_ 826 PTS_GraphicFC 1;
BA_ "FlexKomComment" SG_ 826 PTS_GraphicFC "Park assist front center warnings";
BA_ "FlexKomSigName" SG_ 826 PTS_GraphicFC "PTS_FC";
BA_ "FlexKomSigLaenge" SG_ 826 PTS_GraphicFC 8;
BA_ "FlexKomSigStartPos" SG_ 826 PTS_GraphicFC 47;
BA_ "FlexKomSID" SG_ 826 PTS_GraphicFC 1121;
BA_ "GenSigTimeout_IC" SG_ 826 PTS_GraphicFC 5250;
BA_ "GenSigStartValue" SG_ 826 PTS_GraphicFC 3;
BA_ "FlexKomSigStartValue" SG_ 826 PTS_GraphicFC "F0h";
BA_ "GenSigCycleTime" SG_ 826 PTS_GraphicFC 500;
BA_ "GenSigSendType" SG_ 826 PTS_GraphicFC 5;
BA_ "GenSigSendType" SG_ 826 PTS_FT_SRV 5;
BA_ "GenSigCycleTime" SG_ 826 PTS_FT_SRV 500;
BA_ "FlexKomSigStartValue" SG_ 826 PTS_FT_SRV "00h";
BA_ "GenSigTimeout_IC" SG_ 826 PTS_FT_SRV 5250;
BA_ "FlexKomSID" SG_ 826 PTS_FT_SRV 1354;
BA_ "FlexKomSigStartPos" SG_ 826 PTS_FT_SRV 58;
BA_ "FlexKomSigLaenge" SG_ 826 PTS_FT_SRV 1;
BA_ "FlexKomSigName" SG_ 826 PTS_FT_SRV "PTS_FT_SRV";
BA_ "FlexKomIsMotorola" SG_ 826 PTS_FT_SRV 1;
BA_ "GenSigSNA" SG_ 826 PTS_FT_SRV "0h";
BA_ "FlexKomComment" SG_ 826 PTS_FT_SRV "Front PTS sensor service request; True = [1]";
BA_ "GenSigSNA" SG_ 826 PTS_FT_NA "0h";
BA_ "FlexKomIsMotorola" SG_ 826 PTS_FT_NA 1;
BA_ "FlexKomComment" SG_ 826 PTS_FT_NA "Front park assist not available - blinded sensor; ";
BA_ "FlexKomSigName" SG_ 826 PTS_FT_NA "PTS_FT_NA";
BA_ "FlexKomSigLaenge" SG_ 826 PTS_FT_NA 1;
BA_ "FlexKomSigStartPos" SG_ 826 PTS_FT_NA 3;
BA_ "FlexKomSID" SG_ 826 PTS_FT_NA 1314;
BA_ "GenSigTimeout_IC" SG_ 826 PTS_FT_NA 5250;
BA_ "FlexKomSigStartValue" SG_ 826 PTS_FT_NA "00h";
BA_ "GenSigCycleTime" SG_ 826 PTS_FT_NA 500;
BA_ "GenSigSendType" SG_ 826 PTS_FT_NA 5;
BA_ "GenSigSNA" SG_ 826 PTS_CFG_STAT "3h";
BA_ "FlexKomIsMotorola" SG_ 826 PTS_CFG_STAT 1;
BA_ "FlexKomComment" SG_ 826 PTS_CFG_STAT "Park assist configuration status";
BA_ "FlexKomSigName" SG_ 826 PTS_CFG_STAT "PTS_CFG_STAT";
BA_ "FlexKomSigLaenge" SG_ 826 PTS_CFG_STAT 2;
BA_ "FlexKomSigStartPos" SG_ 826 PTS_CFG_STAT 2;
BA_ "FlexKomSID" SG_ 826 PTS_CFG_STAT 1114;
BA_ "GenSigTimeout_IC" SG_ 826 PTS_CFG_STAT 5250;
BA_ "GenSigTimeout_CBC" SG_ 826 PTS_CFG_STAT 5250;
BA_ "FlexKomSigStartValue" SG_ 826 PTS_CFG_STAT "00h";
BA_ "GenSigCycleTime" SG_ 826 PTS_CFG_STAT 500;
BA_ "GenSigSendType" SG_ 826 PTS_CFG_STAT 5;
BA_ "GenSigSNA" SG_ 826 PTS_AlrRR "Fh";
BA_ "FlexKomIsMotorola" SG_ 826 PTS_AlrRR 1;
BA_ "FlexKomComment" SG_ 826 PTS_AlrRR "Park assist rear right warnings";
BA_ "FlexKomSigName" SG_ 826 PTS_AlrRR "PTS_RR";
BA_ "FlexKomSigLaenge" SG_ 826 PTS_AlrRR 8;
BA_ "FlexKomSigStartPos" SG_ 826 PTS_AlrRR 39;
BA_ "FlexKomSID" SG_ 826 PTS_AlrRR 1120;
BA_ "GenSigTimeout_IC" SG_ 826 PTS_AlrRR 5250;
BA_ "GenSigTimeout_CBC" SG_ 826 PTS_AlrRR 5250;
BA_ "FlexKomSigStartValue" SG_ 826 PTS_AlrRR "F0h";
BA_ "GenSigCycleTime" SG_ 826 PTS_AlrRR 500;
BA_ "GenSigSendType" SG_ 826 PTS_AlrRR 5;
BA_ "GenSigSNA" SG_ 826 PTS_AlrRL "Fh";
BA_ "FlexKomIsMotorola" SG_ 826 PTS_AlrRL 1;
BA_ "FlexKomComment" SG_ 826 PTS_AlrRL "Park assist rear left warnings";
BA_ "FlexKomSigName" SG_ 826 PTS_AlrRL "PTS_RL";
BA_ "FlexKomSigLaenge" SG_ 826 PTS_AlrRL 8;
BA_ "FlexKomSigStartPos" SG_ 826 PTS_AlrRL 31;
BA_ "FlexKomSID" SG_ 826 PTS_AlrRL 1119;
BA_ "GenSigTimeout_IC" SG_ 826 PTS_AlrRL 5250;
BA_ "GenSigTimeout_CBC" SG_ 826 PTS_AlrRL 5250;
BA_ "FlexKomSigStartValue" SG_ 826 PTS_AlrRL "F0h";
BA_ "GenSigCycleTime" SG_ 826 PTS_AlrRL 500;
BA_ "GenSigSendType" SG_ 826 PTS_AlrRL 5;
BA_ "GenSigSNA" SG_ 826 PTS_AlrRC "Fh";
BA_ "FlexKomIsMotorola" SG_ 826 PTS_AlrRC 1;
BA_ "FlexKomComment" SG_ 826 PTS_AlrRC "Park assist rear center warnings";
BA_ "FlexKomSigName" SG_ 826 PTS_AlrRC "PTS_RC";
BA_ "FlexKomSigLaenge" SG_ 826 PTS_AlrRC 8;
BA_ "FlexKomSigStartPos" SG_ 826 PTS_AlrRC 55;
BA_ "FlexKomSID" SG_ 826 PTS_AlrRC 1123;
BA_ "GenSigTimeout_IC" SG_ 826 PTS_AlrRC 5250;
BA_ "GenSigTimeout_CBC" SG_ 826 PTS_AlrRC 5250;
BA_ "FlexKomSigStartValue" SG_ 826 PTS_AlrRC "F0h";
BA_ "GenSigCycleTime" SG_ 826 PTS_AlrRC 500;
BA_ "GenSigSendType" SG_ 826 PTS_AlrRC 5;
BA_ "GenSigSNA" SG_ 826 PTS_AlrFR "Fh";
BA_ "FlexKomIsMotorola" SG_ 826 PTS_AlrFR 1;
BA_ "FlexKomComment" SG_ 826 PTS_AlrFR "Park assist front right warnings";
BA_ "FlexKomSigName" SG_ 826 PTS_AlrFR "PTS_FR";
BA_ "FlexKomSigLaenge" SG_ 826 PTS_AlrFR 8;
BA_ "FlexKomSigStartPos" SG_ 826 PTS_AlrFR 23;
BA_ "FlexKomSID" SG_ 826 PTS_AlrFR 1118;
BA_ "GenSigTimeout_IC" SG_ 826 PTS_AlrFR 5250;
BA_ "GenSigTimeout_CBC" SG_ 826 PTS_AlrFR 5250;
BA_ "FlexKomSigStartValue" SG_ 826 PTS_AlrFR "F0h";
BA_ "GenSigCycleTime" SG_ 826 PTS_AlrFR 500;
BA_ "GenSigSendType" SG_ 826 PTS_AlrFR 5;
BA_ "GenSigSNA" SG_ 826 PTS_AlrFL "Fh";
BA_ "FlexKomIsMotorola" SG_ 826 PTS_AlrFL 1;
BA_ "FlexKomComment" SG_ 826 PTS_AlrFL "Park assist front left warnings";
BA_ "FlexKomSigName" SG_ 826 PTS_AlrFL "PTS_FL";
BA_ "FlexKomSigLaenge" SG_ 826 PTS_AlrFL 8;
BA_ "FlexKomSigStartPos" SG_ 826 PTS_AlrFL 15;
BA_ "FlexKomSID" SG_ 826 PTS_AlrFL 1117;
BA_ "GenSigTimeout_IC" SG_ 826 PTS_AlrFL 5250;
BA_ "GenSigTimeout_CBC" SG_ 826 PTS_AlrFL 5250;
BA_ "FlexKomSigStartValue" SG_ 826 PTS_AlrFL "F0h";
BA_ "GenSigCycleTime" SG_ 826 PTS_AlrFL 500;
BA_ "GenSigSendType" SG_ 826 PTS_AlrFL 5;
BA_ "GenSigSNA" SG_ 826 PTS_AlrFC "Fh";
BA_ "FlexKomIsMotorola" SG_ 826 PTS_AlrFC 1;
BA_ "FlexKomComment" SG_ 826 PTS_AlrFC "Park assist front center warnings";
BA_ "FlexKomSigName" SG_ 826 PTS_AlrFC "PTS_FC";
BA_ "FlexKomSigLaenge" SG_ 826 PTS_AlrFC 8;
BA_ "FlexKomSigStartPos" SG_ 826 PTS_AlrFC 47;
BA_ "FlexKomSID" SG_ 826 PTS_AlrFC 1121;
BA_ "GenSigTimeout_IC" SG_ 826 PTS_AlrFC 5250;
BA_ "GenSigTimeout_CBC" SG_ 826 PTS_AlrFC 5250;
BA_ "FlexKomSigStartValue" SG_ 826 PTS_AlrFC "F0h";
BA_ "GenSigCycleTime" SG_ 826 PTS_AlrFC 500;
BA_ "GenSigSendType" SG_ 826 PTS_AlrFC 5;
BA_ "GenMsgStartValue" BO_ 825 "0050h";
BA_ "GenMsgNrOfRepetitions" BO_ 825 2;
BA_ "GenMsgDelayTime" BO_ 825 20;
BA_ "GenMsgCycleTime" BO_ 825 500;
BA_ "GenMsgSendType" BO_ 825 5;
BA_ "GenSigSNA" SG_ 825 PTS_RR_VOL "3h";
BA_ "FlexKomIsMotorola" SG_ 825 PTS_RR_VOL 1;
BA_ "FlexKomComment" SG_ 825 PTS_RR_VOL "PTS chime status";
BA_ "FlexKomSigName" SG_ 825 PTS_RR_VOL "PTS_CHIME_STAT";
BA_ "FlexKomSigLaenge" SG_ 825 PTS_RR_VOL 16;
BA_ "FlexKomSigStartPos" SG_ 825 PTS_RR_VOL 7;
BA_ "FlexKomSID" SG_ 825 PTS_RR_VOL 1350;
BA_ "GenSigTimeout_IC" SG_ 825 PTS_RR_VOL 5250;
BA_ "GenSigTimeout_CBC" SG_ 825 PTS_RR_VOL 5250;
BA_ "GenSigStartValue" SG_ 825 PTS_RR_VOL 1;
BA_ "FlexKomSigStartValue" SG_ 825 PTS_RR_VOL "0050h";
BA_ "GenSigCycleTime" SG_ 825 PTS_RR_VOL 500;
BA_ "GenSigSendType" SG_ 825 PTS_RR_VOL 5;
BA_ "GenSigSNA" SG_ 825 PTS_RR_CHIME_RQ "0h";
BA_ "FlexKomIsMotorola" SG_ 825 PTS_RR_CHIME_RQ 1;
BA_ "FlexKomComment" SG_ 825 PTS_RR_CHIME_RQ "PTS chime status";
BA_ "FlexKomSigName" SG_ 825 PTS_RR_CHIME_RQ "PTS_CHIME_STAT";
BA_ "FlexKomSigLaenge" SG_ 825 PTS_RR_CHIME_RQ 16;
BA_ "FlexKomSigStartPos" SG_ 825 PTS_RR_CHIME_RQ 7;
BA_ "FlexKomSID" SG_ 825 PTS_RR_CHIME_RQ 1350;
BA_ "FlexKomSigStartValue" SG_ 825 PTS_RR_CHIME_RQ "0050h";
BA_ "GenSigCycleTime" SG_ 825 PTS_RR_CHIME_RQ 500;
BA_ "GenSigSendType" SG_ 825 PTS_RR_CHIME_RQ 5;
BA_ "GenSigSNA" SG_ 825 PTS_RF_CHIME_RQ "0h";
BA_ "FlexKomIsMotorola" SG_ 825 PTS_RF_CHIME_RQ 1;
BA_ "FlexKomComment" SG_ 825 PTS_RF_CHIME_RQ "PTS chime status";
BA_ "FlexKomSigName" SG_ 825 PTS_RF_CHIME_RQ "PTS_CHIME_STAT";
BA_ "FlexKomSigLaenge" SG_ 825 PTS_RF_CHIME_RQ 16;
BA_ "FlexKomSigStartPos" SG_ 825 PTS_RF_CHIME_RQ 7;
BA_ "FlexKomSID" SG_ 825 PTS_RF_CHIME_RQ 1350;
BA_ "FlexKomSigStartValue" SG_ 825 PTS_RF_CHIME_RQ "0050h";
BA_ "GenSigCycleTime" SG_ 825 PTS_RF_CHIME_RQ 500;
BA_ "GenSigSendType" SG_ 825 PTS_RF_CHIME_RQ 5;
BA_ "GenSigSNA" SG_ 825 PTS_LR_CHIME_RQ "0h";
BA_ "FlexKomIsMotorola" SG_ 825 PTS_LR_CHIME_RQ 1;
BA_ "FlexKomComment" SG_ 825 PTS_LR_CHIME_RQ "PTS chime status";
BA_ "FlexKomSigName" SG_ 825 PTS_LR_CHIME_RQ "PTS_CHIME_STAT";
BA_ "FlexKomSigLaenge" SG_ 825 PTS_LR_CHIME_RQ 16;
BA_ "FlexKomSigStartPos" SG_ 825 PTS_LR_CHIME_RQ 7;
BA_ "FlexKomSID" SG_ 825 PTS_LR_CHIME_RQ 1350;
BA_ "FlexKomSigStartValue" SG_ 825 PTS_LR_CHIME_RQ "0050h";
BA_ "GenSigCycleTime" SG_ 825 PTS_LR_CHIME_RQ 500;
BA_ "GenSigSendType" SG_ 825 PTS_LR_CHIME_RQ 5;
BA_ "GenSigSNA" SG_ 825 PTS_LF_CHIME_RQ "0h";
BA_ "FlexKomIsMotorola" SG_ 825 PTS_LF_CHIME_RQ 1;
BA_ "FlexKomComment" SG_ 825 PTS_LF_CHIME_RQ "PTS chime status";
BA_ "FlexKomSigName" SG_ 825 PTS_LF_CHIME_RQ "PTS_CHIME_STAT";
BA_ "FlexKomSigLaenge" SG_ 825 PTS_LF_CHIME_RQ 16;
BA_ "FlexKomSigStartPos" SG_ 825 PTS_LF_CHIME_RQ 7;
BA_ "FlexKomSID" SG_ 825 PTS_LF_CHIME_RQ 1350;
BA_ "FlexKomSigStartValue" SG_ 825 PTS_LF_CHIME_RQ "0050h";
BA_ "GenSigCycleTime" SG_ 825 PTS_LF_CHIME_RQ 500;
BA_ "GenSigSendType" SG_ 825 PTS_LF_CHIME_RQ 5;
BA_ "GenSigSNA" SG_ 825 PTS_FT_VOL "3h";
BA_ "FlexKomIsMotorola" SG_ 825 PTS_FT_VOL 1;
BA_ "FlexKomComment" SG_ 825 PTS_FT_VOL "PTS chime status";
BA_ "FlexKomSigName" SG_ 825 PTS_FT_VOL "PTS_CHIME_STAT";
BA_ "FlexKomSigLaenge" SG_ 825 PTS_FT_VOL 16;
BA_ "FlexKomSigStartPos" SG_ 825 PTS_FT_VOL 7;
BA_ "FlexKomSID" SG_ 825 PTS_FT_VOL 1350;
BA_ "GenSigTimeout_IC" SG_ 825 PTS_FT_VOL 5250;
BA_ "GenSigTimeout_CBC" SG_ 825 PTS_FT_VOL 5250;
BA_ "GenSigStartValue" SG_ 825 PTS_FT_VOL 1;
BA_ "FlexKomSigStartValue" SG_ 825 PTS_FT_VOL "0050h";
BA_ "GenSigCycleTime" SG_ 825 PTS_FT_VOL 500;
BA_ "GenSigSendType" SG_ 825 PTS_FT_VOL 5;
BA_ "GenSigSNA" SG_ 825 PTS_CHIME_TYPE "Fh";
BA_ "FlexKomIsMotorola" SG_ 825 PTS_CHIME_TYPE 1;
BA_ "FlexKomComment" SG_ 825 PTS_CHIME_TYPE "PTS chime status";
BA_ "FlexKomSigName" SG_ 825 PTS_CHIME_TYPE "PTS_CHIME_STAT";
BA_ "FlexKomSigLaenge" SG_ 825 PTS_CHIME_TYPE 16;
BA_ "FlexKomSigStartPos" SG_ 825 PTS_CHIME_TYPE 7;
BA_ "FlexKomSID" SG_ 825 PTS_CHIME_TYPE 1350;
BA_ "GenSigTimeout_CBC" SG_ 825 PTS_CHIME_TYPE 5250;
BA_ "FlexKomSigStartValue" SG_ 825 PTS_CHIME_TYPE "0050h";
BA_ "GenSigCycleTime" SG_ 825 PTS_CHIME_TYPE 500;
BA_ "GenSigSendType" SG_ 825 PTS_CHIME_TYPE 5;
BA_ "GenSigSNA" SG_ 825 PTS_CHIME_REP_RATE "0h";
BA_ "FlexKomIsMotorola" SG_ 825 PTS_CHIME_REP_RATE 1;
BA_ "FlexKomComment" SG_ 825 PTS_CHIME_REP_RATE "PTS chime status";
BA_ "FlexKomSigName" SG_ 825 PTS_CHIME_REP_RATE "PTS_CHIME_STAT";
BA_ "FlexKomSigLaenge" SG_ 825 PTS_CHIME_REP_RATE 16;
BA_ "FlexKomSigStartPos" SG_ 825 PTS_CHIME_REP_RATE 7;
BA_ "FlexKomSID" SG_ 825 PTS_CHIME_REP_RATE 1350;
BA_ "FlexKomSigStartValue" SG_ 825 PTS_CHIME_REP_RATE "0050h";
BA_ "GenSigCycleTime" SG_ 825 PTS_CHIME_REP_RATE 500;
BA_ "GenSigSendType" SG_ 825 PTS_CHIME_REP_RATE 5;
BA_ "GenMsgStartDelayTime" BO_ 820 20;
BA_ "GenMsgStartValue" BO_ 820 "6000003FFFFC0000h";
BA_ "GenMsgNrOfRepetitions" BO_ 820 2;
BA_ "GenMsgDelayTime" BO_ 820 20;
BA_ "GenMsgCycleTime" BO_ 820 1000;
BA_ "GenMsgSendType" BO_ 820 5;
BA_ "GenSigSNA" SG_ 820 WASH_FLUID_LO "0h";
BA_ "FlexKomIsMotorola" SG_ 820 WASH_FLUID_LO 1;
BA_ "FlexKomComment" SG_ 820 WASH_FLUID_LO "Low washer fluid warning (1=Fluid is low)";
BA_ "FlexKomSigName" SG_ 820 WASH_FLUID_LO "WASH_FLUID_LO";
BA_ "FlexKomSigLaenge" SG_ 820 WASH_FLUID_LO 1;
BA_ "FlexKomSigStartPos" SG_ 820 WASH_FLUID_LO 63;
BA_ "FlexKomSID" SG_ 820 WASH_FLUID_LO 965;
BA_ "GenSigTimeout_ETM" SG_ 820 WASH_FLUID_LO 10500;
BA_ "GenSigTimeout_IC" SG_ 820 WASH_FLUID_LO 10500;
BA_ "FlexKomSigStartValue" SG_ 820 WASH_FLUID_LO "00h";
BA_ "GenSigCycleTime" SG_ 820 WASH_FLUID_LO 1000;
BA_ "GenSigSendType" SG_ 820 WASH_FLUID_LO 5;
BA_ "GenSigSNA" SG_ 820 TurnInd_RT_ON "0h";
BA_ "FlexKomIsMotorola" SG_ 820 TurnInd_RT_ON 1;
BA_ "FlexKomComment" SG_ 820 TurnInd_RT_ON "Turn indication status";
BA_ "FlexKomSigName" SG_ 820 TurnInd_RT_ON "TurnInd_STAT";
BA_ "FlexKomSigLaenge" SG_ 820 TurnInd_RT_ON 2;
BA_ "FlexKomSigStartPos" SG_ 820 TurnInd_RT_ON 31;
BA_ "FlexKomSID" SG_ 820 TurnInd_RT_ON 759;
BA_ "GenSigTimeout_PTS" SG_ 820 TurnInd_RT_ON 10500;
BA_ "GenSigTimeout_IC" SG_ 820 TurnInd_RT_ON 10500;
BA_ "FlexKomSigStartValue" SG_ 820 TurnInd_RT_ON "00h";
BA_ "GenSigCycleTime" SG_ 820 TurnInd_RT_ON 1000;
BA_ "GenSigSendType" SG_ 820 TurnInd_RT_ON 5;
BA_ "GenSigSNA" SG_ 820 TurnInd_LT_ON "0h";
BA_ "FlexKomIsMotorola" SG_ 820 TurnInd_LT_ON 1;
BA_ "FlexKomComment" SG_ 820 TurnInd_LT_ON "Turn indication status";
BA_ "FlexKomSigName" SG_ 820 TurnInd_LT_ON "TurnInd_STAT";
BA_ "FlexKomSigLaenge" SG_ 820 TurnInd_LT_ON 2;
BA_ "FlexKomSigStartPos" SG_ 820 TurnInd_LT_ON 31;
BA_ "FlexKomSID" SG_ 820 TurnInd_LT_ON 759;
BA_ "GenSigTimeout_PTS" SG_ 820 TurnInd_LT_ON 10500;
BA_ "GenSigTimeout_IC" SG_ 820 TurnInd_LT_ON 10500;
BA_ "FlexKomSigStartValue" SG_ 820 TurnInd_LT_ON "00h";
BA_ "GenSigCycleTime" SG_ 820 TurnInd_LT_ON 1000;
BA_ "GenSigSendType" SG_ 820 TurnInd_LT_ON 5;
BA_ "GenSigSNA" SG_ 820 TLG_AJAR "0h";
BA_ "FlexKomIsMotorola" SG_ 820 TLG_AJAR 1;
BA_ "FlexKomComment" SG_ 820 TLG_AJAR "Door ajar";
BA_ "FlexKomSigName" SG_ 820 TLG_AJAR "DR_AJAR";
BA_ "FlexKomSigLaenge" SG_ 820 TLG_AJAR 6;
BA_ "FlexKomSigStartPos" SG_ 820 TLG_AJAR 22;
BA_ "FlexKomSID" SG_ 820 TLG_AJAR 797;
BA_ "GenSigTimeout_IC" SG_ 820 TLG_AJAR 10500;
BA_ "GenSigTimeout_RF_HUB" SG_ 820 TLG_AJAR 10500;
BA_ "FlexKomSigStartValue" SG_ 820 TLG_AJAR "00h";
BA_ "GenSigCycleTime" SG_ 820 TLG_AJAR 1000;
BA_ "GenSigSendType" SG_ 820 TLG_AJAR 5;
BA_ "GenSigSNA" SG_ 820 SHIP_STAT "3h";
BA_ "FlexKomIsMotorola" SG_ 820 SHIP_STAT 1;
BA_ "FlexKomComment" SG_ 820 SHIP_STAT "Shipping status";
BA_ "FlexKomSigName" SG_ 820 SHIP_STAT "SHIP_STAT";
BA_ "FlexKomSigLaenge" SG_ 820 SHIP_STAT 2;
BA_ "FlexKomSigStartPos" SG_ 820 SHIP_STAT 29;
BA_ "FlexKomSID" SG_ 820 SHIP_STAT 869;
BA_ "GenSigTimeout_ORC" SG_ 820 SHIP_STAT 3500;
BA_ "GenSigTimeout_IC" SG_ 820 SHIP_STAT 10500;
BA_ "GenSigTimeout_RF_HUB" SG_ 820 SHIP_STAT 10500;
BA_ "GenSigStartValue" SG_ 820 SHIP_STAT 3;
BA_ "FlexKomSigStartValue" SG_ 820 SHIP_STAT "03h";
BA_ "GenSigCycleTime" SG_ 820 SHIP_STAT 1000;
BA_ "GenSigSendType" SG_ 820 SHIP_STAT 5;
BA_ "GenSigSNA" SG_ 820 REV_GEAR "0h";
BA_ "FlexKomIsMotorola" SG_ 820 REV_GEAR 1;
BA_ "FlexKomComment" SG_ 820 REV_GEAR "Reverse Gear (manual trans)";
BA_ "FlexKomSigName" SG_ 820 REV_GEAR "REV_GEAR";
BA_ "FlexKomSigLaenge" SG_ 820 REV_GEAR 1;
BA_ "FlexKomSigStartPos" SG_ 820 REV_GEAR 4;
BA_ "FlexKomSID" SG_ 820 REV_GEAR 685;
BA_ "GenSigTimeout_ORC" SG_ 820 REV_GEAR 3500;
BA_ "GenSigTimeout_PTS" SG_ 820 REV_GEAR 3500;
BA_ "GenSigTimeout_IC" SG_ 820 REV_GEAR 10500;
BA_ "GenSigTimeout_RF_HUB" SG_ 820 REV_GEAR 10500;
BA_ "FlexKomSigStartValue" SG_ 820 REV_GEAR "00h";
BA_ "GenSigCycleTime" SG_ 820 REV_GEAR 1000;
BA_ "GenSigSendType" SG_ 820 REV_GEAR 5;
BA_ "GenSigSNA" SG_ 820 R_R_AJAR "0h";
BA_ "FlexKomIsMotorola" SG_ 820 R_R_AJAR 1;
BA_ "FlexKomComment" SG_ 820 R_R_AJAR "Door ajar";
BA_ "FlexKomSigName" SG_ 820 R_R_AJAR "DR_AJAR";
BA_ "FlexKomSigLaenge" SG_ 820 R_R_AJAR 6;
BA_ "FlexKomSigStartPos" SG_ 820 R_R_AJAR 22;
BA_ "FlexKomSID" SG_ 820 R_R_AJAR 797;
BA_ "GenSigTimeout_IC" SG_ 820 R_R_AJAR 10500;
BA_ "GenSigTimeout_RF_HUB" SG_ 820 R_R_AJAR 10500;
BA_ "FlexKomSigStartValue" SG_ 820 R_R_AJAR "00h";
BA_ "GenSigCycleTime" SG_ 820 R_R_AJAR 1000;
BA_ "GenSigSendType" SG_ 820 R_R_AJAR 5;
BA_ "GenSigSNA" SG_ 820 PSG_AJAR "0h";
BA_ "FlexKomIsMotorola" SG_ 820 PSG_AJAR 1;
BA_ "FlexKomComment" SG_ 820 PSG_AJAR "Door ajar";
BA_ "FlexKomSigName" SG_ 820 PSG_AJAR "DR_AJAR";
BA_ "FlexKomSigLaenge" SG_ 820 PSG_AJAR 6;
BA_ "FlexKomSigStartPos" SG_ 820 PSG_AJAR 22;
BA_ "FlexKomSID" SG_ 820 PSG_AJAR 797;
BA_ "GenSigTimeout_ORC" SG_ 820 PSG_AJAR 3500;
BA_ "GenSigTimeout_IC" SG_ 820 PSG_AJAR 10500;
BA_ "GenSigTimeout_RF_HUB" SG_ 820 PSG_AJAR 10500;
BA_ "FlexKomSigStartValue" SG_ 820 PSG_AJAR "00h";
BA_ "GenSigCycleTime" SG_ 820 PSG_AJAR 1000;
BA_ "GenSigSendType" SG_ 820 PSG_AJAR 5;
BA_ "GenSigSNA" SG_ 820 PARK_LMP_ON "0h";
BA_ "FlexKomIsMotorola" SG_ 820 PARK_LMP_ON 1;
BA_ "FlexKomComment" SG_ 820 PARK_LMP_ON "Parklamps are on; off=[0], on=[1]";
BA_ "FlexKomSigName" SG_ 820 PARK_LMP_ON "PARK_LMP_ON";
BA_ "FlexKomSigLaenge" SG_ 820 PARK_LMP_ON 1;
BA_ "FlexKomSigStartPos" SG_ 820 PARK_LMP_ON 16;
BA_ "FlexKomSID" SG_ 820 PARK_LMP_ON 767;
BA_ "GenSigTimeout_IC" SG_ 820 PARK_LMP_ON 10500;
BA_ "FlexKomSigStartValue" SG_ 820 PARK_LMP_ON "00h";
BA_ "GenSigCycleTime" SG_ 820 PARK_LMP_ON 1000;
BA_ "GenSigSendType" SG_ 820 PARK_LMP_ON 5;
BA_ "GenSigSNA" SG_ 820 PANEL_INTS "FFh";
BA_ "FlexKomIsMotorola" SG_ 820 PANEL_INTS 1;
BA_ "FlexKomComment" SG_ 820 PANEL_INTS "Interior lighting status powertrain";
BA_ "FlexKomSigName" SG_ 820 PANEL_INTS "IntLtSt_PT";
BA_ "FlexKomSigLaenge" SG_ 820 PANEL_INTS 24;
BA_ "FlexKomSigStartPos" SG_ 820 PANEL_INTS 47;
BA_ "FlexKomSID" SG_ 820 PANEL_INTS 1417;
BA_ "GenSigTimeout_ESM" SG_ 820 PANEL_INTS 10500;
BA_ "GenSigTimeout_SCCM" SG_ 820 PANEL_INTS 10500;
BA_ "GenSigTimeout_IC" SG_ 820 PANEL_INTS 10500;
BA_ "GenSigTimeout_RF_HUB" SG_ 820 PANEL_INTS 10500;
BA_ "FlexKomSigStartValue" SG_ 820 PANEL_INTS "000000h";
BA_ "GenSigCycleTime" SG_ 820 PANEL_INTS 1000;
BA_ "GenSigSendType" SG_ 820 PANEL_INTS 5;
BA_ "GenSigSNA" SG_ 820 LOBEAM_ON "0h";
BA_ "FlexKomIsMotorola" SG_ 820 LOBEAM_ON 1;
BA_ "FlexKomComment" SG_ 820 LOBEAM_ON "Low beam is on; off=[0], on=[1]";
BA_ "FlexKomSigName" SG_ 820 LOBEAM_ON "LOBEAM_ON";
BA_ "FlexKomSigLaenge" SG_ 820 LOBEAM_ON 1;
BA_ "FlexKomSigStartPos" SG_ 820 LOBEAM_ON 57;
BA_ "FlexKomSID" SG_ 820 LOBEAM_ON 883;
BA_ "GenSigTimeout_IC" SG_ 820 LOBEAM_ON 10500;
BA_ "FlexKomSigStartValue" SG_ 820 LOBEAM_ON "00h";
BA_ "GenSigCycleTime" SG_ 820 LOBEAM_ON 1000;
BA_ "GenSigSendType" SG_ 820 LOBEAM_ON 5;
BA_ "GenSigSNA" SG_ 820 L_R_AJAR "0h";
BA_ "FlexKomIsMotorola" SG_ 820 L_R_AJAR 1;
BA_ "FlexKomComment" SG_ 820 L_R_AJAR "Door ajar";
BA_ "FlexKomSigName" SG_ 820 L_R_AJAR "DR_AJAR";
BA_ "FlexKomSigLaenge" SG_ 820 L_R_AJAR 6;
BA_ "FlexKomSigStartPos" SG_ 820 L_R_AJAR 22;
BA_ "FlexKomSID" SG_ 820 L_R_AJAR 797;
BA_ "GenSigTimeout_IC" SG_ 820 L_R_AJAR 10500;
BA_ "GenSigTimeout_RF_HUB" SG_ 820 L_R_AJAR 10500;
BA_ "FlexKomSigStartValue" SG_ 820 L_R_AJAR "00h";
BA_ "GenSigCycleTime" SG_ 820 L_R_AJAR 1000;
BA_ "GenSigSendType" SG_ 820 L_R_AJAR 5;
BA_ "GenSigSNA" SG_ 820 IGN_OFF_TIME_LNG "FFFh";
BA_ "FlexKomIsMotorola" SG_ 820 IGN_OFF_TIME_LNG 1;
BA_ "FlexKomComment" SG_ 820 IGN_OFF_TIME_LNG "Time since last ignition on (long)";
BA_ "FlexKomSigName" SG_ 820 IGN_OFF_TIME_LNG "IGN_OFF_TIME_LNG";
BA_ "FlexKomSigLaenge" SG_ 820 IGN_OFF_TIME_LNG 16;
BA_ "FlexKomSigStartPos" SG_ 820 IGN_OFF_TIME_LNG 31;
BA_ "FlexKomSID" SG_ 820 IGN_OFF_TIME_LNG 998;
BA_ "GenSigTimeout_IC" SG_ 820 IGN_OFF_TIME_LNG 10500;
BA_ "GenSigTimeout_RF_HUB" SG_ 820 IGN_OFF_TIME_LNG 10500;
BA_ "GenSigStartValue" SG_ 820 IGN_OFF_TIME_LNG 4095;
BA_ "FlexKomSigStartValue" SG_ 820 IGN_OFF_TIME_LNG "0FFFh";
BA_ "GenSigCycleTime" SG_ 820 IGN_OFF_TIME_LNG 1000;
BA_ "GenSigSendType" SG_ 820 IGN_OFF_TIME_LNG 5;
BA_ "GenSigSNA" SG_ 820 HIBEAM_ON "0h";
BA_ "FlexKomIsMotorola" SG_ 820 HIBEAM_ON 1;
BA_ "FlexKomComment" SG_ 820 HIBEAM_ON "High beam is on; off=[0], on=[1]";
BA_ "FlexKomSigName" SG_ 820 HIBEAM_ON "HIBEAM_ON";
BA_ "FlexKomSigLaenge" SG_ 820 HIBEAM_ON 1;
BA_ "FlexKomSigStartPos" SG_ 820 HIBEAM_ON 58;
BA_ "FlexKomSID" SG_ 820 HIBEAM_ON 884;
BA_ "GenSigTimeout_IC" SG_ 820 HIBEAM_ON 10500;
BA_ "FlexKomSigStartValue" SG_ 820 HIBEAM_ON "00h";
BA_ "GenSigCycleTime" SG_ 820 HIBEAM_ON 1000;
BA_ "GenSigSendType" SG_ 820 HIBEAM_ON 5;
BA_ "GenSigSNA" SG_ 820 FT_WPR_NOT_PRK "0h";
BA_ "FlexKomIsMotorola" SG_ 820 FT_WPR_NOT_PRK 1;
BA_ "FlexKomComment" SG_ 820 FT_WPR_NOT_PRK "Front wiper outside park position";
BA_ "FlexKomSigName" SG_ 820 FT_WPR_NOT_PRK "FT_WPR_NOT_PRK";
BA_ "FlexKomSigLaenge" SG_ 820 FT_WPR_NOT_PRK 1;
BA_ "FlexKomSigStartPos" SG_ 820 FT_WPR_NOT_PRK 56;
BA_ "FlexKomSID" SG_ 820 FT_WPR_NOT_PRK 1046;
BA_ "FlexKomSigStartValue" SG_ 820 FT_WPR_NOT_PRK "00h";
BA_ "GenSigCycleTime" SG_ 820 FT_WPR_NOT_PRK 1000;
BA_ "GenSigSendType" SG_ 820 FT_WPR_NOT_PRK 5;
BA_ "GenSigSNA" SG_ 820 FT_FOG_RQ "0h";
BA_ "FlexKomIsMotorola" SG_ 820 FT_FOG_RQ 1;
BA_ "FlexKomComment" SG_ 820 FT_FOG_RQ "Front fog request; off=[0], on=[1]";
BA_ "FlexKomSigName" SG_ 820 FT_FOG_RQ "FT_FOG_RQ";
BA_ "FlexKomSigLaenge" SG_ 820 FT_FOG_RQ 1;
BA_ "FlexKomSigStartPos" SG_ 820 FT_FOG_RQ 2;
BA_ "FlexKomSID" SG_ 820 FT_FOG_RQ 758;
BA_ "GenSigTimeout_IC" SG_ 820 FT_FOG_RQ 10500;
BA_ "FlexKomSigStartValue" SG_ 820 FT_FOG_RQ "00h";
BA_ "GenSigCycleTime" SG_ 820 FT_FOG_RQ 1000;
BA_ "GenSigSendType" SG_ 820 FT_FOG_RQ 5;
BA_ "GenSigSNA" SG_ 820 FOB_SrchRq "0h";
BA_ "FlexKomIsMotorola" SG_ 820 FOB_SrchRq 1;
BA_ "FlexKomComment" SG_ 820 FOB_SrchRq "FOB search request";
BA_ "FlexKomSigName" SG_ 820 FOB_SrchRq "FOB_SrchRq";
BA_ "FlexKomSigLaenge" SG_ 820 FOB_SrchRq 2;
BA_ "FlexKomSigStartPos" SG_ 820 FOB_SrchRq 9;
BA_ "FlexKomSID" SG_ 820 FOB_SrchRq 1392;
BA_ "GenSigTimeout_RF_HUB" SG_ 820 FOB_SrchRq 5500;
BA_ "FlexKomSigStartValue" SG_ 820 FOB_SrchRq "00h";
BA_ "GenSigCycleTime" SG_ 820 FOB_SrchRq 1000;
BA_ "GenSigSendType" SG_ 820 FOB_SrchRq 5;
BA_ "GenSigSNA" SG_ 820 DRV_AJAR "0h";
BA_ "FlexKomIsMotorola" SG_ 820 DRV_AJAR 1;
BA_ "FlexKomComment" SG_ 820 DRV_AJAR "Door ajar";
BA_ "FlexKomSigName" SG_ 820 DRV_AJAR "DR_AJAR";
BA_ "FlexKomSigLaenge" SG_ 820 DRV_AJAR 6;
BA_ "FlexKomSigStartPos" SG_ 820 DRV_AJAR 22;
BA_ "FlexKomSID" SG_ 820 DRV_AJAR 797;
BA_ "GenSigTimeout_IC" SG_ 820 DRV_AJAR 10500;
BA_ "GenSigTimeout_RF_HUB" SG_ 820 DRV_AJAR 10500;
BA_ "FlexKomSigStartValue" SG_ 820 DRV_AJAR "00h";
BA_ "GenSigCycleTime" SG_ 820 DRV_AJAR 1000;
BA_ "GenSigSendType" SG_ 820 DRV_AJAR 5;
BA_ "GenSigSNA" SG_ 820 DR_LK_STAT "3h";
BA_ "FlexKomIsMotorola" SG_ 820 DR_LK_STAT 1;
BA_ "FlexKomComment" SG_ 820 DR_LK_STAT "Door lock status";
BA_ "FlexKomSigName" SG_ 820 DR_LK_STAT "DR_LK_STAT";
BA_ "FlexKomSigLaenge" SG_ 820 DR_LK_STAT 2;
BA_ "FlexKomSigStartPos" SG_ 820 DR_LK_STAT 6;
BA_ "FlexKomSID" SG_ 820 DR_LK_STAT 861;
BA_ "GenSigTimeout_RF_HUB" SG_ 820 DR_LK_STAT 10500;
BA_ "GenSigStartValue" SG_ 820 DR_LK_STAT 3;
BA_ "FlexKomSigStartValue" SG_ 820 DR_LK_STAT "03h";
BA_ "GenSigCycleTime" SG_ 820 DR_LK_STAT 1000;
BA_ "GenSigSendType" SG_ 820 DR_LK_STAT 5;
BA_ "GenSigSNA" SG_ 820 DAY_LGT_MD "0h";
BA_ "FlexKomIsMotorola" SG_ 820 DAY_LGT_MD 1;
BA_ "FlexKomComment" SG_ 820 DAY_LGT_MD "Interior lighting status powertrain";
BA_ "FlexKomSigName" SG_ 820 DAY_LGT_MD "IntLtSt_PT";
BA_ "FlexKomSigLaenge" SG_ 820 DAY_LGT_MD 24;
BA_ "FlexKomSigStartPos" SG_ 820 DAY_LGT_MD 47;
BA_ "FlexKomSID" SG_ 820 DAY_LGT_MD 1417;
BA_ "GenSigTimeout_ESM" SG_ 820 DAY_LGT_MD 10500;
BA_ "GenSigTimeout_SCCM" SG_ 820 DAY_LGT_MD 10500;
BA_ "GenSigTimeout_IC" SG_ 820 DAY_LGT_MD 10500;
BA_ "GenSigTimeout_RF_HUB" SG_ 820 DAY_LGT_MD 10500;
BA_ "FlexKomSigStartValue" SG_ 820 DAY_LGT_MD "000000h";
BA_ "GenSigCycleTime" SG_ 820 DAY_LGT_MD 1000;
BA_ "GenSigSendType" SG_ 820 DAY_LGT_MD 5;
BA_ "GenSigSNA" SG_ 820 BRK_FLUID_LO "0h";
BA_ "FlexKomIsMotorola" SG_ 820 BRK_FLUID_LO 1;
BA_ "FlexKomComment" SG_ 820 BRK_FLUID_LO "Low brake fluid warning; low = [1]";
BA_ "FlexKomSigName" SG_ 820 BRK_FLUID_LO "BRK_FLUID_LO";
BA_ "FlexKomSigLaenge" SG_ 820 BRK_FLUID_LO 1;
BA_ "FlexKomSigStartPos" SG_ 820 BRK_FLUID_LO 62;
BA_ "FlexKomSID" SG_ 820 BRK_FLUID_LO 885;
BA_ "GenSigTimeout_ETM" SG_ 820 BRK_FLUID_LO 10500;
BA_ "GenSigTimeout_IC" SG_ 820 BRK_FLUID_LO 10500;
BA_ "FlexKomSigStartValue" SG_ 820 BRK_FLUID_LO "00h";
BA_ "GenSigCycleTime" SG_ 820 BRK_FLUID_LO 1000;
BA_ "GenSigSendType" SG_ 820 BRK_FLUID_LO 5;
BA_ "GenSigSNA" SG_ 820 AHB_ACT "0h";
BA_ "FlexKomIsMotorola" SG_ 820 AHB_ACT 1;
BA_ "FlexKomComment" SG_ 820 AHB_ACT "Automatic high beam active";
BA_ "FlexKomSigName" SG_ 820 AHB_ACT "AHB_ACT";
BA_ "FlexKomSigLaenge" SG_ 820 AHB_ACT 1;
BA_ "FlexKomSigStartPos" SG_ 820 AHB_ACT 14;
BA_ "FlexKomSID" SG_ 820 AHB_ACT 732;
BA_ "GenSigTimeout_IC" SG_ 820 AHB_ACT 10500;
BA_ "FlexKomSigStartValue" SG_ 820 AHB_ACT "00h";
BA_ "GenSigCycleTime" SG_ 820 AHB_ACT 1000;
BA_ "GenSigSendType" SG_ 820 AHB_ACT 5;
BA_ "GenMsgStartValue" BO_ 817 "00000000001E0000h";
BA_ "GenMsgNrOfRepetitions" BO_ 817 2;
BA_ "GenMsgDelayTime" BO_ 817 20;
BA_ "GenMsgCycleTime" BO_ 817 1000;
BA_ "GenMsgSendType" BO_ 817 5;
BA_ "GenSigSNA" SG_ 817 PSD_RT_DisplayStat "0h";
BA_ "FlexKomIsMotorola" SG_ 817 PSD_RT_DisplayStat 1;
BA_ "FlexKomComment" SG_ 817 PSD_RT_DisplayStat "Right power sliding door display status";
BA_ "FlexKomSigName" SG_ 817 PSD_RT_DisplayStat "PSD_RT_DisplayStat";
BA_ "FlexKomSigLaenge" SG_ 817 PSD_RT_DisplayStat 4;
BA_ "FlexKomSigStartPos" SG_ 817 PSD_RT_DisplayStat 63;
BA_ "FlexKomSID" SG_ 817 PSD_RT_DisplayStat 2464;
BA_ "GenSigTimeout_IC" SG_ 817 PSD_RT_DisplayStat 10500;
BA_ "FlexKomSigStartValue" SG_ 817 PSD_RT_DisplayStat "00h";
BA_ "GenSigCycleTime" SG_ 817 PSD_RT_DisplayStat 1000;
BA_ "GenSigSendType" SG_ 817 PSD_RT_DisplayStat 5;
BA_ "GenSigSNA" SG_ 817 PSD_LT_DisplayStat "0h";
BA_ "FlexKomIsMotorola" SG_ 817 PSD_LT_DisplayStat 1;
BA_ "FlexKomComment" SG_ 817 PSD_LT_DisplayStat "Left power sliding door display status";
BA_ "FlexKomSigName" SG_ 817 PSD_LT_DisplayStat "PSD_LT_DisplayStat";
BA_ "FlexKomSigLaenge" SG_ 817 PSD_LT_DisplayStat 4;
BA_ "FlexKomSigStartPos" SG_ 817 PSD_LT_DisplayStat 59;
BA_ "FlexKomSID" SG_ 817 PSD_LT_DisplayStat 2463;
BA_ "GenSigTimeout_IC" SG_ 817 PSD_LT_DisplayStat 10500;
BA_ "FlexKomSigStartValue" SG_ 817 PSD_LT_DisplayStat "00h";
BA_ "GenSigCycleTime" SG_ 817 PSD_LT_DisplayStat 1000;
BA_ "GenSigSendType" SG_ 817 PSD_LT_DisplayStat 5;
BA_ "GenMsgStartValue" BO_ 808 "0000000000000000h";
BA_ "GenMsgNrOfRepetitions" BO_ 808 2;
BA_ "GenMsgDelayTime" BO_ 808 20;
BA_ "GenMsgCycleTime" BO_ 808 1000;
BA_ "GenMsgSendType" BO_ 808 5;
BA_ "GenSigSNA" SG_ 808 TGW_TEXT_IC "0h";
BA_ "FlexKomIsMotorola" SG_ 808 TGW_TEXT_IC 1;
BA_ "FlexKomComment" SG_ 808 TGW_TEXT_IC "TGW text data transfer to IC";
BA_ "FlexKomSigName" SG_ 808 TGW_TEXT_IC "TGW_DATA_IC";
BA_ "FlexKomSigLaenge" SG_ 808 TGW_TEXT_IC 64;
BA_ "FlexKomSigStartPos" SG_ 808 TGW_TEXT_IC 7;
BA_ "FlexKomSID" SG_ 808 TGW_TEXT_IC 985;
BA_ "FlexKomSigStartValue" SG_ 808 TGW_TEXT_IC "0000000000000000h";
BA_ "GenSigCycleTime" SG_ 808 TGW_TEXT_IC 1000;
BA_ "GenSigSendType" SG_ 808 TGW_TEXT_IC 5;
BA_ "GenSigSNA" SG_ 808 TGW_HiGrpMark_IC "0h";
BA_ "FlexKomIsMotorola" SG_ 808 TGW_HiGrpMark_IC 1;
BA_ "FlexKomComment" SG_ 808 TGW_HiGrpMark_IC "TGW text data transfer to IC";
BA_ "FlexKomSigName" SG_ 808 TGW_HiGrpMark_IC "TGW_DATA_IC";
BA_ "FlexKomSigLaenge" SG_ 808 TGW_HiGrpMark_IC 64;
BA_ "FlexKomSigStartPos" SG_ 808 TGW_HiGrpMark_IC 7;
BA_ "FlexKomSID" SG_ 808 TGW_HiGrpMark_IC 985;
BA_ "FlexKomSigStartValue" SG_ 808 TGW_HiGrpMark_IC "0000000000000000h";
BA_ "GenSigCycleTime" SG_ 808 TGW_HiGrpMark_IC 1000;
BA_ "GenSigSendType" SG_ 808 TGW_HiGrpMark_IC 5;
BA_ "GenSigSNA" SG_ 808 TGW_GrpTyp_IC "3Fh";
BA_ "FlexKomIsMotorola" SG_ 808 TGW_GrpTyp_IC 1;
BA_ "FlexKomComment" SG_ 808 TGW_GrpTyp_IC "TGW text data transfer to IC";
BA_ "FlexKomSigName" SG_ 808 TGW_GrpTyp_IC "TGW_DATA_IC";
BA_ "FlexKomSigLaenge" SG_ 808 TGW_GrpTyp_IC 64;
BA_ "FlexKomSigStartPos" SG_ 808 TGW_GrpTyp_IC 7;
BA_ "FlexKomSID" SG_ 808 TGW_GrpTyp_IC 985;
BA_ "FlexKomSigStartValue" SG_ 808 TGW_GrpTyp_IC "0000000000000000h";
BA_ "GenSigCycleTime" SG_ 808 TGW_GrpTyp_IC 1000;
BA_ "GenSigSendType" SG_ 808 TGW_GrpTyp_IC 5;
BA_ "GenSigSNA" SG_ 808 TGW_GrpNum_IC "0h";
BA_ "FlexKomIsMotorola" SG_ 808 TGW_GrpNum_IC 1;
BA_ "FlexKomComment" SG_ 808 TGW_GrpNum_IC "TGW text data transfer to IC";
BA_ "FlexKomSigName" SG_ 808 TGW_GrpNum_IC "TGW_DATA_IC";
BA_ "FlexKomSigLaenge" SG_ 808 TGW_GrpNum_IC 64;
BA_ "FlexKomSigStartPos" SG_ 808 TGW_GrpNum_IC 7;
BA_ "FlexKomSID" SG_ 808 TGW_GrpNum_IC 985;
BA_ "FlexKomSigStartValue" SG_ 808 TGW_GrpNum_IC "0000000000000000h";
BA_ "GenSigCycleTime" SG_ 808 TGW_GrpNum_IC 1000;
BA_ "GenSigSendType" SG_ 808 TGW_GrpNum_IC 5;
BA_ "GenMsgStartDelayTime" BO_ 804 30;
BA_ "GenMsgStartValue" BO_ 804 "000C000000010000h";
BA_ "GenMsgNrOfRepetitions" BO_ 804 2;
BA_ "GenMsgDelayTime" BO_ 804 20;
BA_ "GenMsgCycleTime" BO_ 804 1000;
BA_ "GenMsgSendType" BO_ 804 5;
BA_ "GenSigSNA" SG_ 804 WPR_SYS_WASH "0h";
BA_ "FlexKomIsMotorola" SG_ 804 WPR_SYS_WASH 1;
BA_ "FlexKomComment" SG_ 804 WPR_SYS_WASH "Wiper System Status";
BA_ "FlexKomSigName" SG_ 804 WPR_SYS_WASH "WPR_SYS_STAT";
BA_ "FlexKomSigLaenge" SG_ 804 WPR_SYS_WASH 8;
BA_ "FlexKomSigStartPos" SG_ 804 WPR_SYS_WASH 47;
BA_ "FlexKomSID" SG_ 804 WPR_SYS_WASH 1048;
BA_ "FlexKomSigStartValue" SG_ 804 WPR_SYS_WASH "01h";
BA_ "GenSigCycleTime" SG_ 804 WPR_SYS_WASH 1000;
BA_ "GenSigSNA" SG_ 804 WPR_SYS_OFF "1h";
BA_ "FlexKomIsMotorola" SG_ 804 WPR_SYS_OFF 1;
BA_ "FlexKomComment" SG_ 804 WPR_SYS_OFF "Wiper System Status";
BA_ "FlexKomSigName" SG_ 804 WPR_SYS_OFF "WPR_SYS_STAT";
BA_ "FlexKomSigLaenge" SG_ 804 WPR_SYS_OFF 8;
BA_ "FlexKomSigStartPos" SG_ 804 WPR_SYS_OFF 47;
BA_ "FlexKomSID" SG_ 804 WPR_SYS_OFF 1048;
BA_ "GenSigStartValue" SG_ 804 WPR_SYS_OFF 1;
BA_ "FlexKomSigStartValue" SG_ 804 WPR_SYS_OFF "01h";
BA_ "GenSigCycleTime" SG_ 804 WPR_SYS_OFF 1000;
BA_ "GenSigSNA" SG_ 804 WPR_SYS_MIST "0h";
BA_ "FlexKomIsMotorola" SG_ 804 WPR_SYS_MIST 1;
BA_ "FlexKomComment" SG_ 804 WPR_SYS_MIST "Wiper System Status";
BA_ "FlexKomSigName" SG_ 804 WPR_SYS_MIST "WPR_SYS_STAT";
BA_ "FlexKomSigLaenge" SG_ 804 WPR_SYS_MIST 8;
BA_ "FlexKomSigStartPos" SG_ 804 WPR_SYS_MIST 47;
BA_ "FlexKomSID" SG_ 804 WPR_SYS_MIST 1048;
BA_ "FlexKomSigStartValue" SG_ 804 WPR_SYS_MIST "01h";
BA_ "GenSigCycleTime" SG_ 804 WPR_SYS_MIST 1000;
BA_ "GenSigSNA" SG_ 804 WPR_SYS_LOW "0h";
BA_ "FlexKomIsMotorola" SG_ 804 WPR_SYS_LOW 1;
BA_ "FlexKomComment" SG_ 804 WPR_SYS_LOW "Wiper System Status";
BA_ "FlexKomSigName" SG_ 804 WPR_SYS_LOW "WPR_SYS_STAT";
BA_ "FlexKomSigLaenge" SG_ 804 WPR_SYS_LOW 8;
BA_ "FlexKomSigStartPos" SG_ 804 WPR_SYS_LOW 47;
BA_ "FlexKomSID" SG_ 804 WPR_SYS_LOW 1048;
BA_ "FlexKomSigStartValue" SG_ 804 WPR_SYS_LOW "01h";
BA_ "GenSigCycleTime" SG_ 804 WPR_SYS_LOW 1000;
BA_ "GenSigSNA" SG_ 804 WPR_SYS_INT "0h";
BA_ "FlexKomIsMotorola" SG_ 804 WPR_SYS_INT 1;
BA_ "FlexKomComment" SG_ 804 WPR_SYS_INT "Wiper System Status";
BA_ "FlexKomSigName" SG_ 804 WPR_SYS_INT "WPR_SYS_STAT";
BA_ "FlexKomSigLaenge" SG_ 804 WPR_SYS_INT 8;
BA_ "FlexKomSigStartPos" SG_ 804 WPR_SYS_INT 47;
BA_ "FlexKomSID" SG_ 804 WPR_SYS_INT 1048;
BA_ "FlexKomSigStartValue" SG_ 804 WPR_SYS_INT "01h";
BA_ "GenSigCycleTime" SG_ 804 WPR_SYS_INT 1000;
BA_ "GenSigSNA" SG_ 804 WPR_SYS_HIGH "0h";
BA_ "FlexKomIsMotorola" SG_ 804 WPR_SYS_HIGH 1;
BA_ "FlexKomComment" SG_ 804 WPR_SYS_HIGH "Wiper System Status";
BA_ "FlexKomSigName" SG_ 804 WPR_SYS_HIGH "WPR_SYS_STAT";
BA_ "FlexKomSigLaenge" SG_ 804 WPR_SYS_HIGH 8;
BA_ "FlexKomSigStartPos" SG_ 804 WPR_SYS_HIGH 47;
BA_ "FlexKomSID" SG_ 804 WPR_SYS_HIGH 1048;
BA_ "FlexKomSigStartValue" SG_ 804 WPR_SYS_HIGH "01h";
BA_ "GenSigCycleTime" SG_ 804 WPR_SYS_HIGH 1000;
BA_ "GenSigSNA" SG_ 804 WPR_SYS_FLT "0h";
BA_ "FlexKomIsMotorola" SG_ 804 WPR_SYS_FLT 1;
BA_ "FlexKomComment" SG_ 804 WPR_SYS_FLT "Wiper System Status";
BA_ "FlexKomSigName" SG_ 804 WPR_SYS_FLT "WPR_SYS_STAT";
BA_ "FlexKomSigLaenge" SG_ 804 WPR_SYS_FLT 8;
BA_ "FlexKomSigStartPos" SG_ 804 WPR_SYS_FLT 47;
BA_ "FlexKomSID" SG_ 804 WPR_SYS_FLT 1048;
BA_ "FlexKomSigStartValue" SG_ 804 WPR_SYS_FLT "01h";
BA_ "GenSigCycleTime" SG_ 804 WPR_SYS_FLT 1000;
BA_ "GenSigSNA" SG_ 804 WPR_SYS_AUTO "0h";
BA_ "FlexKomIsMotorola" SG_ 804 WPR_SYS_AUTO 1;
BA_ "FlexKomComment" SG_ 804 WPR_SYS_AUTO "Wiper System Status";
BA_ "FlexKomSigName" SG_ 804 WPR_SYS_AUTO "WPR_SYS_STAT";
BA_ "FlexKomSigLaenge" SG_ 804 WPR_SYS_AUTO 8;
BA_ "FlexKomSigStartPos" SG_ 804 WPR_SYS_AUTO 47;
BA_ "FlexKomSID" SG_ 804 WPR_SYS_AUTO 1048;
BA_ "FlexKomSigStartValue" SG_ 804 WPR_SYS_AUTO "01h";
BA_ "GenSigCycleTime" SG_ 804 WPR_SYS_AUTO 1000;
BA_ "GenSigSNA" SG_ 804 TurnLmp_RR_Flt "0h";
BA_ "FlexKomIsMotorola" SG_ 804 TurnLmp_RR_Flt 1;
BA_ "FlexKomComment" SG_ 804 TurnLmp_RR_Flt "Turn indication lamp rear fault";
BA_ "FlexKomSigName" SG_ 804 TurnLmp_RR_Flt "TurnLmp_R_Flt";
BA_ "FlexKomSigLaenge" SG_ 804 TurnLmp_RR_Flt 2;
BA_ "FlexKomSigStartPos" SG_ 804 TurnLmp_RR_Flt 25;
BA_ "FlexKomSID" SG_ 804 TurnLmp_RR_Flt 1033;
BA_ "GenSigTimeout_IC" SG_ 804 TurnLmp_RR_Flt 10500;
BA_ "FlexKomSigStartValue" SG_ 804 TurnLmp_RR_Flt "00h";
BA_ "GenSigCycleTime" SG_ 804 TurnLmp_RR_Flt 1000;
BA_ "GenSigSendType" SG_ 804 TurnLmp_RR_Flt 5;
BA_ "GenSigSNA" SG_ 804 TurnLmp_RL_Flt "0h";
BA_ "FlexKomIsMotorola" SG_ 804 TurnLmp_RL_Flt 1;
BA_ "FlexKomComment" SG_ 804 TurnLmp_RL_Flt "Turn indication lamp rear fault";
BA_ "FlexKomSigName" SG_ 804 TurnLmp_RL_Flt "TurnLmp_R_Flt";
BA_ "FlexKomSigLaenge" SG_ 804 TurnLmp_RL_Flt 2;
BA_ "FlexKomSigStartPos" SG_ 804 TurnLmp_RL_Flt 25;
BA_ "FlexKomSID" SG_ 804 TurnLmp_RL_Flt 1033;
BA_ "GenSigTimeout_IC" SG_ 804 TurnLmp_RL_Flt 10500;
BA_ "FlexKomSigStartValue" SG_ 804 TurnLmp_RL_Flt "00h";
BA_ "GenSigCycleTime" SG_ 804 TurnLmp_RL_Flt 1000;
BA_ "GenSigSendType" SG_ 804 TurnLmp_RL_Flt 5;
BA_ "GenSigSNA" SG_ 804 TurnLmp_FR_Flt "0h";
BA_ "FlexKomIsMotorola" SG_ 804 TurnLmp_FR_Flt 1;
BA_ "FlexKomComment" SG_ 804 TurnLmp_FR_Flt "Turn indication lamp front fault";
BA_ "FlexKomSigName" SG_ 804 TurnLmp_FR_Flt "TurnLmp_F_Flt";
BA_ "FlexKomSigLaenge" SG_ 804 TurnLmp_FR_Flt 2;
BA_ "FlexKomSigStartPos" SG_ 804 TurnLmp_FR_Flt 14;
BA_ "FlexKomSID" SG_ 804 TurnLmp_FR_Flt 973;
BA_ "GenSigTimeout_IC" SG_ 804 TurnLmp_FR_Flt 10500;
BA_ "FlexKomSigStartValue" SG_ 804 TurnLmp_FR_Flt "00h";
BA_ "GenSigCycleTime" SG_ 804 TurnLmp_FR_Flt 1000;
BA_ "GenSigSendType" SG_ 804 TurnLmp_FR_Flt 5;
BA_ "GenSigSNA" SG_ 804 TurnLmp_FL_Flt "0h";
BA_ "FlexKomIsMotorola" SG_ 804 TurnLmp_FL_Flt 1;
BA_ "FlexKomComment" SG_ 804 TurnLmp_FL_Flt "Turn indication lamp front fault";
BA_ "FlexKomSigName" SG_ 804 TurnLmp_FL_Flt "TurnLmp_F_Flt";
BA_ "FlexKomSigLaenge" SG_ 804 TurnLmp_FL_Flt 2;
BA_ "FlexKomSigStartPos" SG_ 804 TurnLmp_FL_Flt 14;
BA_ "FlexKomSID" SG_ 804 TurnLmp_FL_Flt 973;
BA_ "GenSigTimeout_IC" SG_ 804 TurnLmp_FL_Flt 10500;
BA_ "FlexKomSigStartValue" SG_ 804 TurnLmp_FL_Flt "00h";
BA_ "GenSigCycleTime" SG_ 804 TurnLmp_FL_Flt 1000;
BA_ "GenSigSendType" SG_ 804 TurnLmp_FL_Flt 5;
BA_ "GenSigSNA" SG_ 804 RemSt_Inhibit "FFh";
BA_ "FlexKomIsMotorola" SG_ 804 RemSt_Inhibit 1;
BA_ "FlexKomComment" SG_ 804 RemSt_Inhibit "Remote start inhibit";
BA_ "FlexKomSigName" SG_ 804 RemSt_Inhibit "RemSt_Inhibit";
BA_ "FlexKomSigLaenge" SG_ 804 RemSt_Inhibit 8;
BA_ "FlexKomSigStartPos" SG_ 804 RemSt_Inhibit 39;
BA_ "FlexKomSID" SG_ 804 RemSt_Inhibit 1047;
BA_ "GenSigTimeout_ETM" SG_ 804 RemSt_Inhibit 10500;
BA_ "GenSigTimeout_IC" SG_ 804 RemSt_Inhibit 10500;
BA_ "FlexKomSigStartValue" SG_ 804 RemSt_Inhibit "00h";
BA_ "GenSigCycleTime" SG_ 804 RemSt_Inhibit 1000;
BA_ "GenSigSendType" SG_ 804 RemSt_Inhibit 5;
BA_ "GenSigSNA" SG_ 804 HdAjar "1h";
BA_ "FlexKomIsMotorola" SG_ 804 HdAjar 1;
BA_ "FlexKomComment" SG_ 804 HdAjar "Hood latch ajar, left or single (1=ajar)";
BA_ "FlexKomSigName" SG_ 804 HdAjar "HdAjar";
BA_ "FlexKomSigLaenge" SG_ 804 HdAjar 1;
BA_ "FlexKomSigStartPos" SG_ 804 HdAjar 10;
BA_ "FlexKomSID" SG_ 804 HdAjar 1818;
BA_ "GenSigStartValue" SG_ 804 HdAjar 1;
BA_ "FlexKomSigStartValue" SG_ 804 HdAjar "01h";
BA_ "GenSigCycleTime" SG_ 804 HdAjar 1000;
BA_ "GenSigSendType" SG_ 804 HdAjar 5;
BA_ "GenSigSNA" SG_ 804 ExteriorRearReleaseSwitchSts "0h";
BA_ "FlexKomIsMotorola" SG_ 804 ExteriorRearReleaseSwitchSts 1;
BA_ "FlexKomComment" SG_ 804 ExteriorRearReleaseSwitchSts "Exterior rear release switch status";
BA_ "FlexKomSigName" SG_ 804 ExteriorRearReleaseSwitchSts "ExteriorRearReleaseSwitchSts";
BA_ "FlexKomSigLaenge" SG_ 804 ExteriorRearReleaseSwitchSts 1;
BA_ "FlexKomSigStartPos" SG_ 804 ExteriorRearReleaseSwitchSts 21;
BA_ "FlexKomSID" SG_ 804 ExteriorRearReleaseSwitchSts 1846;
BA_ "GenSigTimeout_RF_HUB" SG_ 804 ExteriorRearReleaseSwitchSts 10500;
BA_ "FlexKomSigStartValue" SG_ 804 ExteriorRearReleaseSwitchSts "00h";
BA_ "GenSigCycleTime" SG_ 804 ExteriorRearReleaseSwitchSts 1000;
BA_ "GenSigSendType" SG_ 804 ExteriorRearReleaseSwitchSts 5;
BA_ "GenSigSNA" SG_ 804 ACC_DLY_ACT "0h";
BA_ "FlexKomIsMotorola" SG_ 804 ACC_DLY_ACT 1;
BA_ "FlexKomComment" SG_ 804 ACC_DLY_ACT "Accessory Delay Active";
BA_ "FlexKomSigName" SG_ 804 ACC_DLY_ACT "ACC_DLY_ACT";
BA_ "FlexKomSigLaenge" SG_ 804 ACC_DLY_ACT 1;
BA_ "FlexKomSigStartPos" SG_ 804 ACC_DLY_ACT 26;
BA_ "FlexKomSID" SG_ 804 ACC_DLY_ACT 841;
BA_ "GenSigTimeout_SCCM" SG_ 804 ACC_DLY_ACT 10500;
BA_ "GenSigTimeout_IC" SG_ 804 ACC_DLY_ACT 10500;
BA_ "FlexKomSigStartValue" SG_ 804 ACC_DLY_ACT "00h";
BA_ "GenSigCycleTime" SG_ 804 ACC_DLY_ACT 1000;
BA_ "GenSigSendType" SG_ 804 ACC_DLY_ACT 5;
BA_ "GenMsgStartValue" BO_ 800 "0000000000000000h";
BA_ "GenMsgNrOfRepetitions" BO_ 800 2;
BA_ "GenMsgDelayTime" BO_ 800 20;
BA_ "GenMsgCycleTime" BO_ 800 100;
BA_ "GenSigCycleTime" SG_ 800 RefuelIndication 100;
BA_ "FlexKomSigStartValue" SG_ 800 RefuelIndication "00h";
BA_ "FlexKomSID" SG_ 800 RefuelIndication 2578;
BA_ "FlexKomSigStartPos" SG_ 800 RefuelIndication 31;
BA_ "FlexKomSigLaenge" SG_ 800 RefuelIndication 3;
BA_ "FlexKomSigName" SG_ 800 RefuelIndication "RefuelIndication";
BA_ "FlexKomIsMotorola" SG_ 800 RefuelIndication 1;
BA_ "GenSigSNA" SG_ 800 RefuelIndication "0h";
BA_ "FlexKomComment" SG_ 800 RefuelIndication "Indication to the driver about the status of the r";
BA_ "GenSigCycleTime" SG_ 800 RefuelEvent 100;
BA_ "FlexKomSigStartValue" SG_ 800 RefuelEvent "00h";
BA_ "FlexKomSID" SG_ 800 RefuelEvent 2574;
BA_ "FlexKomSigStartPos" SG_ 800 RefuelEvent 13;
BA_ "FlexKomSigLaenge" SG_ 800 RefuelEvent 3;
BA_ "FlexKomSigName" SG_ 800 RefuelEvent "RefuelEvent";
BA_ "FlexKomComment" SG_ 800 RefuelEvent "Status of refuel event";
BA_ "FlexKomIsMotorola" SG_ 800 RefuelEvent 1;
BA_ "GenSigSNA" SG_ 800 RefuelEvent "0h";
BA_ "GenSigCycleTime" SG_ 800 LeakTestSts 100;
BA_ "FlexKomSigStartValue" SG_ 800 LeakTestSts "00h";
BA_ "FlexKomSID" SG_ 800 LeakTestSts 2576;
BA_ "FlexKomSigStartPos" SG_ 800 LeakTestSts 28;
BA_ "FlexKomSigLaenge" SG_ 800 LeakTestSts 2;
BA_ "FlexKomSigName" SG_ 800 LeakTestSts "LeakTestSts";
BA_ "FlexKomComment" SG_ 800 LeakTestSts "Status of leak test";
BA_ "FlexKomIsMotorola" SG_ 800 LeakTestSts 1;
BA_ "GenSigSNA" SG_ 800 LeakTestSts "0h";
BA_ "GenSigCycleTime" SG_ 800 LeakTestRequest 100;
BA_ "FlexKomSigStartValue" SG_ 800 LeakTestRequest "00h";
BA_ "FlexKomSID" SG_ 800 LeakTestRequest 2577;
BA_ "FlexKomSigStartPos" SG_ 800 LeakTestRequest 26;
BA_ "FlexKomSigLaenge" SG_ 800 LeakTestRequest 1;
BA_ "FlexKomSigName" SG_ 800 LeakTestRequest "LeakTestRequest";
BA_ "FlexKomIsMotorola" SG_ 800 LeakTestRequest 1;
BA_ "GenSigSNA" SG_ 800 LeakTestRequest "0h";
BA_ "FlexKomComment" SG_ 800 LeakTestRequest "Leak test is requested after powerdown; No request";
BA_ "GenSigCycleTime" SG_ 800 LeakCheckTimerValue 100;
BA_ "FlexKomSigStartValue" SG_ 800 LeakCheckTimerValue "0000h";
BA_ "FlexKomSID" SG_ 800 LeakCheckTimerValue 2575;
BA_ "FlexKomSigStartPos" SG_ 800 LeakCheckTimerValue 15;
BA_ "FlexKomSigLaenge" SG_ 800 LeakCheckTimerValue 16;
BA_ "FlexKomSigName" SG_ 800 LeakCheckTimerValue "LeakCheckTimerValue";
BA_ "FlexKomComment" SG_ 800 LeakCheckTimerValue "Requested leak test timer value";
BA_ "FlexKomIsMotorola" SG_ 800 LeakCheckTimerValue 1;
BA_ "GenSigSNA" SG_ 800 LeakCheckTimerValue "1FFh";
BA_ "GenSigSNA" SG_ 800 KeySense_SetSpdOpt "7h";
BA_ "FlexKomIsMotorola" SG_ 800 KeySense_SetSpdOpt 1;
BA_ "FlexKomComment" SG_ 800 KeySense_SetSpdOpt "Key sense max speed option for ECM speed limiting";
BA_ "FlexKomSigName" SG_ 800 KeySense_SetSpdOpt "KeySense_SetSpdOpt";
BA_ "FlexKomSigLaenge" SG_ 800 KeySense_SetSpdOpt 3;
BA_ "FlexKomSigStartPos" SG_ 800 KeySense_SetSpdOpt 2;
BA_ "FlexKomSID" SG_ 800 KeySense_SetSpdOpt 2394;
BA_ "FlexKomSigStartValue" SG_ 800 KeySense_SetSpdOpt "00h";
BA_ "GenSigCycleTime" SG_ 800 KeySense_SetSpdOpt 100;
BA_ "GenSigSNA" SG_ 800 KeySense_DispReq "0h";
BA_ "FlexKomIsMotorola" SG_ 800 KeySense_DispReq 1;
BA_ "FlexKomComment" SG_ 800 KeySense_DispReq "Key sense cluster EVIC request";
BA_ "FlexKomSigName" SG_ 800 KeySense_DispReq "KeySense_DispReq";
BA_ "FlexKomSigLaenge" SG_ 800 KeySense_DispReq 2;
BA_ "FlexKomSigStartPos" SG_ 800 KeySense_DispReq 15;
BA_ "FlexKomSID" SG_ 800 KeySense_DispReq 2393;
BA_ "GenSigTimeout_IC" SG_ 800 KeySense_DispReq 1050;
BA_ "FlexKomSigStartValue" SG_ 800 KeySense_DispReq "00h";
BA_ "GenSigCycleTime" SG_ 800 KeySense_DispReq 100;
BA_ "GenMsgStartDelayTime" BO_ 799 130;
BA_ "GenMsgStartValue" BO_ 799 "07FF07FF00000004h";
BA_ "GenMsgNrOfRepetitions" BO_ 799 2;
BA_ "GenMsgDelayTime" BO_ 799 20;
BA_ "GenMsgCycleTime" BO_ 799 1000;
BA_ "GenMsgSendType" BO_ 799 5;
BA_ "GenSigSNA" SG_ 799 TGW_AUD_MD_CAB_DR "1Fh";
BA_ "FlexKomIsMotorola" SG_ 799 TGW_AUD_MD_CAB_DR 1;
BA_ "FlexKomComment" SG_ 799 TGW_AUD_MD_CAB_DR "TGW audio mode for Cabin/Driver";
BA_ "FlexKomSigName" SG_ 799 TGW_AUD_MD_CAB_DR "TGW_AUD_MD_CAB_DR";
BA_ "FlexKomSigLaenge" SG_ 799 TGW_AUD_MD_CAB_DR 5;
BA_ "FlexKomSigStartPos" SG_ 799 TGW_AUD_MD_CAB_DR 7;
BA_ "FlexKomSID" SG_ 799 TGW_AUD_MD_CAB_DR 672;
BA_ "GenSigTimeout_IC" SG_ 799 TGW_AUD_MD_CAB_DR 10500;
BA_ "FlexKomSigStartValue" SG_ 799 TGW_AUD_MD_CAB_DR "00h";
BA_ "GenSigCycleTime" SG_ 799 TGW_AUD_MD_CAB_DR 1000;
BA_ "GenSigSendType" SG_ 799 TGW_AUD_MD_CAB_DR 5;
BA_ "GenSigSNA" SG_ 799 RainSensorFailSts "0h";
BA_ "FlexKomIsMotorola" SG_ 799 RainSensorFailSts 1;
BA_ "FlexKomComment" SG_ 799 RainSensorFailSts "Fail present = 1";
BA_ "FlexKomSigName" SG_ 799 RainSensorFailSts "RainSensorFailSts";
BA_ "FlexKomSigLaenge" SG_ 799 RainSensorFailSts 1;
BA_ "FlexKomSigStartPos" SG_ 799 RainSensorFailSts 63;
BA_ "FlexKomSID" SG_ 799 RainSensorFailSts 2046;
BA_ "GenSigTimeout_IC" SG_ 799 RainSensorFailSts 10500;
BA_ "FlexKomSigStartValue" SG_ 799 RainSensorFailSts "00h";
BA_ "GenSigCycleTime" SG_ 799 RainSensorFailSts 1000;
BA_ "GenSigSendType" SG_ 799 RainSensorFailSts 5;
BA_ "GenSigSNA" SG_ 799 IBS_R_Batt_25 "7FFh";
BA_ "FlexKomIsMotorola" SG_ 799 IBS_R_Batt_25 1;
BA_ "FlexKomComment" SG_ 799 IBS_R_Batt_25 "Batt resistance at 100% SOC and 25 degC";
BA_ "FlexKomSigName" SG_ 799 IBS_R_Batt_25 "IBS_R_Batt_25";
BA_ "FlexKomSigLaenge" SG_ 799 IBS_R_Batt_25 16;
BA_ "FlexKomSigStartPos" SG_ 799 IBS_R_Batt_25 23;
BA_ "FlexKomSID" SG_ 799 IBS_R_Batt_25 1947;
BA_ "GenSigStartValue" SG_ 799 IBS_R_Batt_25 2047;
BA_ "FlexKomSigStartValue" SG_ 799 IBS_R_Batt_25 "07FFh";
BA_ "GenSigCycleTime" SG_ 799 IBS_R_Batt_25 1000;
BA_ "GenSigSNA" SG_ 799 IBS_R_Batt "7FFh";
BA_ "FlexKomIsMotorola" SG_ 799 IBS_R_Batt 1;
BA_ "FlexKomComment" SG_ 799 IBS_R_Batt "Calculated battery resistance";
BA_ "FlexKomSigName" SG_ 799 IBS_R_Batt "IBS_R_Batt";
BA_ "FlexKomSigLaenge" SG_ 799 IBS_R_Batt 16;
BA_ "FlexKomSigStartPos" SG_ 799 IBS_R_Batt 7;
BA_ "FlexKomSID" SG_ 799 IBS_R_Batt 1948;
BA_ "GenSigStartValue" SG_ 799 IBS_R_Batt 2047;
BA_ "FlexKomSigStartValue" SG_ 799 IBS_R_Batt "07FFh";
BA_ "GenSigCycleTime" SG_ 799 IBS_R_Batt 1000;
BA_ "GenMsgStartValue" BO_ 792 "000000000000FF00h";
BA_ "GenMsgNrOfRepetitions" BO_ 792 2;
BA_ "GenMsgDelayTime" BO_ 792 20;
BA_ "GenMsgCycleTime" BO_ 792 100;
BA_ "GenMsgSendType" BO_ 792 5;
BA_ "GenSigSNA" SG_ 792 WprWashSw_Psd "0h";
BA_ "FlexKomIsMotorola" SG_ 792 WprWashSw_Psd 1;
BA_ "FlexKomComment" SG_ 792 WprWashSw_Psd "Steering wheel actuation request";
BA_ "FlexKomSigName" SG_ 792 WprWashSw_Psd "StW_Actn_Rq";
BA_ "FlexKomSigLaenge" SG_ 792 WprWashSw_Psd 64;
BA_ "FlexKomSigStartPos" SG_ 792 WprWashSw_Psd 7;
BA_ "FlexKomSID" SG_ 792 WprWashSw_Psd 420;
BA_ "FlexKomSigStartValue" SG_ 792 WprWashSw_Psd "000000000000FF00h";
BA_ "GenSigCycleTime" SG_ 792 WprWashSw_Psd 100;
BA_ "GenSigSendType" SG_ 792 WprWashSw_Psd 5;
BA_ "GenSigSNA" SG_ 792 WprWash_R_Sw_Posn_V3 "0h";
BA_ "FlexKomIsMotorola" SG_ 792 WprWash_R_Sw_Posn_V3 1;
BA_ "FlexKomComment" SG_ 792 WprWash_R_Sw_Posn_V3 "Steering wheel actuation request";
BA_ "FlexKomSigName" SG_ 792 WprWash_R_Sw_Posn_V3 "StW_Actn_Rq";
BA_ "FlexKomSigLaenge" SG_ 792 WprWash_R_Sw_Posn_V3 64;
BA_ "FlexKomSigStartPos" SG_ 792 WprWash_R_Sw_Posn_V3 7;
BA_ "FlexKomSID" SG_ 792 WprWash_R_Sw_Posn_V3 420;
BA_ "FlexKomSigStartValue" SG_ 792 WprWash_R_Sw_Posn_V3 "000000000000FF00h";
BA_ "GenSigCycleTime" SG_ 792 WprWash_R_Sw_Posn_V3 100;
BA_ "GenSigSendType" SG_ 792 WprWash_R_Sw_Posn_V3 5;
BA_ "GenSigSNA" SG_ 792 WprSw6Posn "Fh";
BA_ "FlexKomIsMotorola" SG_ 792 WprSw6Posn 1;
BA_ "FlexKomComment" SG_ 792 WprSw6Posn "Steering wheel actuation request";
BA_ "FlexKomSigName" SG_ 792 WprSw6Posn "StW_Actn_Rq";
BA_ "FlexKomSigLaenge" SG_ 792 WprSw6Posn 64;
BA_ "FlexKomSigStartPos" SG_ 792 WprSw6Posn 7;
BA_ "FlexKomSID" SG_ 792 WprSw6Posn 420;
BA_ "GenSigTimeout_CBC" SG_ 792 WprSw6Posn 1050;
BA_ "FlexKomSigStartValue" SG_ 792 WprSw6Posn "000000000000FF00h";
BA_ "GenSigCycleTime" SG_ 792 WprSw6Posn 100;
BA_ "GenSigSendType" SG_ 792 WprSw6Posn 5;
BA_ "GenSigSNA" SG_ 792 TurnIndLvr_Stat "0h";
BA_ "FlexKomIsMotorola" SG_ 792 TurnIndLvr_Stat 1;
BA_ "FlexKomComment" SG_ 792 TurnIndLvr_Stat "Steering wheel actuation request";
BA_ "FlexKomSigName" SG_ 792 TurnIndLvr_Stat "StW_Actn_Rq";
BA_ "FlexKomSigLaenge" SG_ 792 TurnIndLvr_Stat 64;
BA_ "FlexKomSigStartPos" SG_ 792 TurnIndLvr_Stat 7;
BA_ "FlexKomSID" SG_ 792 TurnIndLvr_Stat 420;
BA_ "GenSigTimeout_PTS" SG_ 792 TurnIndLvr_Stat 1050;
BA_ "FlexKomSigStartValue" SG_ 792 TurnIndLvr_Stat "000000000000FF00h";
BA_ "GenSigCycleTime" SG_ 792 TurnIndLvr_Stat 100;
BA_ "GenSigSendType" SG_ 792 TurnIndLvr_Stat 5;
BA_ "GenSigSNA" SG_ 792 HiBmLvr_Stat "0h";
BA_ "FlexKomIsMotorola" SG_ 792 HiBmLvr_Stat 1;
BA_ "FlexKomComment" SG_ 792 HiBmLvr_Stat "Steering wheel actuation request";
BA_ "FlexKomSigName" SG_ 792 HiBmLvr_Stat "StW_Actn_Rq";
BA_ "FlexKomSigLaenge" SG_ 792 HiBmLvr_Stat 64;
BA_ "FlexKomSigStartPos" SG_ 792 HiBmLvr_Stat 7;
BA_ "FlexKomSID" SG_ 792 HiBmLvr_Stat 420;
BA_ "FlexKomSigStartValue" SG_ 792 HiBmLvr_Stat "000000000000FF00h";
BA_ "GenSigCycleTime" SG_ 792 HiBmLvr_Stat 100;
BA_ "GenSigSendType" SG_ 792 HiBmLvr_Stat 5;
BA_ "GenMsgStartValue" BO_ 784 "01FF0000FFFFFF07h";
BA_ "GenMsgNrOfRepetitions" BO_ 784 2;
BA_ "GenMsgDelayTime" BO_ 784 20;
BA_ "GenMsgCycleTime" BO_ 784 1000;
BA_ "GenMsgSendType" BO_ 784 5;
BA_ "GenSigSNA" SG_ 784 SRS_LMP_STAT "3h";
BA_ "FlexKomIsMotorola" SG_ 784 SRS_LMP_STAT 1;
BA_ "FlexKomComment" SG_ 784 SRS_LMP_STAT "Airbag indicator lamp status";
BA_ "FlexKomSigName" SG_ 784 SRS_LMP_STAT "SRS_LMP_STAT";
BA_ "FlexKomSigLaenge" SG_ 784 SRS_LMP_STAT 2;
BA_ "FlexKomSigStartPos" SG_ 784 SRS_LMP_STAT 5;
BA_ "FlexKomSID" SG_ 784 SRS_LMP_STAT 851;
BA_ "GenSigTimeout_ETM" SG_ 784 SRS_LMP_STAT 10500;
BA_ "GenSigTimeout_ORC" SG_ 784 SRS_LMP_STAT 3500;
BA_ "FlexKomSigStartValue" SG_ 784 SRS_LMP_STAT "00h";
BA_ "GenSigCycleTime" SG_ 784 SRS_LMP_STAT 1000;
BA_ "GenSigSendType" SG_ 784 SRS_LMP_STAT 5;
BA_ "GenSigSNA" SG_ 784 SBR_MuteRq "0h";
BA_ "FlexKomIsMotorola" SG_ 784 SBR_MuteRq 1;
BA_ "FlexKomComment" SG_ 784 SBR_MuteRq "Seatbelt reminder audio mute request; Mute = [1]";
BA_ "FlexKomSigName" SG_ 784 SBR_MuteRq "SBR_MuteRq";
BA_ "FlexKomSigLaenge" SG_ 784 SBR_MuteRq 1;
BA_ "FlexKomSigStartPos" SG_ 784 SBR_MuteRq 63;
BA_ "FlexKomSID" SG_ 784 SBR_MuteRq 2303;
BA_ "FlexKomSigStartValue" SG_ 784 SBR_MuteRq "00h";
BA_ "GenSigCycleTime" SG_ 784 SBR_MuteRq 1000;
BA_ "GenSigSendType" SG_ 784 SBR_MuteRq 5;
BA_ "GenSigSNA" SG_ 784 PTS_MODE_SELECTION "7h";
BA_ "FlexKomIsMotorola" SG_ 784 PTS_MODE_SELECTION 1;
BA_ "FlexKomComment" SG_ 784 PTS_MODE_SELECTION "Park assist maneuver selection for PTS";
BA_ "FlexKomSigName" SG_ 784 PTS_MODE_SELECTION "PTS_MODE_SELECTION";
BA_ "FlexKomSigLaenge" SG_ 784 PTS_MODE_SELECTION 3;
BA_ "FlexKomSigStartPos" SG_ 784 PTS_MODE_SELECTION 62;
BA_ "FlexKomSID" SG_ 784 PTS_MODE_SELECTION 1910;
BA_ "GenSigTimeout_PTS" SG_ 784 PTS_MODE_SELECTION 10500;
BA_ "FlexKomSigStartValue" SG_ 784 PTS_MODE_SELECTION "00h";
BA_ "GenSigCycleTime" SG_ 784 PTS_MODE_SELECTION 1000;
BA_ "GenSigSendType" SG_ 784 PTS_MODE_SELECTION 5;
BA_ "GenSigSNA" SG_ 784 OilChgRst "0h";
BA_ "FlexKomIsMotorola" SG_ 784 OilChgRst 1;
BA_ "FlexKomComment" SG_ 784 OilChgRst "Oil change reminder reset request";
BA_ "FlexKomSigName" SG_ 784 OilChgRst "OilChgRst";
BA_ "FlexKomSigLaenge" SG_ 784 OilChgRst 1;
BA_ "FlexKomSigStartPos" SG_ 784 OilChgRst 29;
BA_ "FlexKomSID" SG_ 784 OilChgRst 1819;
BA_ "FlexKomSigStartValue" SG_ 784 OilChgRst "00h";
BA_ "GenSigCycleTime" SG_ 784 OilChgRst 1000;
BA_ "GenSigSendType" SG_ 784 OilChgRst 5;
BA_ "GenSigSNA" SG_ 784 ODO "FFFFFFh";
BA_ "FlexKomIsMotorola" SG_ 784 ODO 1;
BA_ "FlexKomComment" SG_ 784 ODO "Odometer";
BA_ "FlexKomSigName" SG_ 784 ODO "ODO";
BA_ "FlexKomSigLaenge" SG_ 784 ODO 24;
BA_ "FlexKomSigStartPos" SG_ 784 ODO 39;
BA_ "FlexKomSID" SG_ 784 ODO 804;
BA_ "GenSigTimeout_ORC" SG_ 784 ODO 3500;
BA_ "GenSigTimeout_ESM" SG_ 784 ODO 10500;
BA_ "GenSigTimeout_SCCM" SG_ 784 ODO 10500;
BA_ "GenSigTimeout_EPS" SG_ 784 ODO 10500;
BA_ "GenSigTimeout_CBC" SG_ 784 ODO 10500;
BA_ "GenSigTimeout_RF_HUB" SG_ 784 ODO 10500;
BA_ "GenSigStartValue" SG_ 784 ODO 16777215;
BA_ "FlexKomSigStartValue" SG_ 784 ODO "FFFFFFh";
BA_ "GenSigCycleTime" SG_ 784 ODO 1000;
BA_ "GenSigSendType" SG_ 784 ODO 5;
BA_ "GenSigSNA" SG_ 784 FuelLvlLow "0h";
BA_ "FlexKomIsMotorola" SG_ 784 FuelLvlLow 1;
BA_ "FlexKomComment" SG_ 784 FuelLvlLow "Fuel level low";
BA_ "FlexKomSigName" SG_ 784 FuelLvlLow "FuelLvlLow";
BA_ "FlexKomSigLaenge" SG_ 784 FuelLvlLow 1;
BA_ "FlexKomSigStartPos" SG_ 784 FuelLvlLow 6;
BA_ "FlexKomSID" SG_ 784 FuelLvlLow 1049;
BA_ "GenSigTimeout_CBC" SG_ 784 FuelLvlLow 10500;
BA_ "FlexKomSigStartValue" SG_ 784 FuelLvlLow "00h";
BA_ "GenSigCycleTime" SG_ 784 FuelLvlLow 1000;
BA_ "GenSigSendType" SG_ 784 FuelLvlLow 5;
BA_ "GenSigSNA" SG_ 784 AvgFuelLvl "1FFh";
BA_ "FlexKomIsMotorola" SG_ 784 AvgFuelLvl 1;
BA_ "FlexKomComment" SG_ 784 AvgFuelLvl "Average filtered fuel level in liters";
BA_ "FlexKomSigName" SG_ 784 AvgFuelLvl "AvgFuelLvl";
BA_ "FlexKomSigLaenge" SG_ 784 AvgFuelLvl 16;
BA_ "FlexKomSigStartPos" SG_ 784 AvgFuelLvl 7;
BA_ "FlexKomSID" SG_ 784 AvgFuelLvl 848;
BA_ "GenSigTimeout_ETM" SG_ 784 AvgFuelLvl 10500;
BA_ "GenSigTimeout_CBC" SG_ 784 AvgFuelLvl 10500;
BA_ "GenSigStartValue" SG_ 784 AvgFuelLvl 511;
BA_ "FlexKomSigStartValue" SG_ 784 AvgFuelLvl "01FFh";
BA_ "GenSigCycleTime" SG_ 784 AvgFuelLvl 1000;
BA_ "GenSigSendType" SG_ 784 AvgFuelLvl 5;
BA_ "GenMsgStartValue" BO_ 782 "03FF07FF00000000h";
BA_ "GenMsgNrOfRepetitions" BO_ 782 2;
BA_ "GenMsgDelayTime" BO_ 782 20;
BA_ "GenMsgCycleTime" BO_ 782 1000;
BA_ "GenMsgSendType" BO_ 782 5;
BA_ "GenSigSNA" SG_ 782 Total_Range "7FFh";
BA_ "FlexKomIsMotorola" SG_ 782 Total_Range 1;
BA_ "FlexKomComment" SG_ 782 Total_Range "IC_A5 packet";
BA_ "FlexKomSigName" SG_ 782 Total_Range "IC_A5_Pkt";
BA_ "FlexKomSigLaenge" SG_ 782 Total_Range 64;
BA_ "FlexKomSigStartPos" SG_ 782 Total_Range 7;
BA_ "FlexKomSID" SG_ 782 Total_Range 2522;
BA_ "GenSigTimeout_CBC" SG_ 782 Total_Range 10500;
BA_ "GenSigStartValue" SG_ 782 Total_Range 2047;
BA_ "FlexKomSigStartValue" SG_ 782 Total_Range "03FF07FF00000000h";
BA_ "GenSigCycleTime" SG_ 782 Total_Range 1000;
BA_ "GenSigSendType" SG_ 782 Total_Range 5;
BA_ "GenSigSendType" SG_ 782 Gas_Range 5;
BA_ "GenSigCycleTime" SG_ 782 Gas_Range 1000;
BA_ "FlexKomSigStartValue" SG_ 782 Gas_Range "03FF07FF00000000h";
BA_ "GenSigStartValue" SG_ 782 Gas_Range 1023;
BA_ "GenSigTimeout_CBC" SG_ 782 Gas_Range 10500;
BA_ "FlexKomSID" SG_ 782 Gas_Range 2522;
BA_ "FlexKomSigStartPos" SG_ 782 Gas_Range 7;
BA_ "FlexKomSigLaenge" SG_ 782 Gas_Range 64;
BA_ "FlexKomSigName" SG_ 782 Gas_Range "IC_A5_Pkt";
BA_ "FlexKomComment" SG_ 782 Gas_Range "IC_A5 packet";
BA_ "FlexKomIsMotorola" SG_ 782 Gas_Range 1;
BA_ "GenSigSNA" SG_ 782 Gas_Range "3FFh";
BA_ "GenMsgStartValue" BO_ 779 "FFFFFF0FFF00FF00h";
BA_ "GenMsgNrOfRepetitions" BO_ 779 2;
BA_ "GenMsgDelayTime" BO_ 779 20;
BA_ "GenMsgCycleTime" BO_ 779 1000;
BA_ "GenSigSNA" SG_ 779 OilLifeLeftRst "0h";
BA_ "FlexKomIsMotorola" SG_ 779 OilLifeLeftRst 1;
BA_ "FlexKomComment" SG_ 779 OilLifeLeftRst "Oil life packet";
BA_ "FlexKomSigName" SG_ 779 OilLifeLeftRst "OilLifePkt";
BA_ "FlexKomSigLaenge" SG_ 779 OilLifeLeftRst 40;
BA_ "FlexKomSigStartPos" SG_ 779 OilLifeLeftRst 7;
BA_ "FlexKomSID" SG_ 779 OilLifeLeftRst 1668;
BA_ "GenSigTimeout_ETM" SG_ 779 OilLifeLeftRst 10500;
BA_ "FlexKomSigStartValue" SG_ 779 OilLifeLeftRst "FFFFFF0FFFh";
BA_ "GenSigCycleTime" SG_ 779 OilLifeLeftRst 1000;
BA_ "GenSigSNA" SG_ 779 OilLifeLeft "FFh";
BA_ "FlexKomIsMotorola" SG_ 779 OilLifeLeft 1;
BA_ "FlexKomComment" SG_ 779 OilLifeLeft "Oil life packet";
BA_ "FlexKomSigName" SG_ 779 OilLifeLeft "OilLifePkt";
BA_ "FlexKomSigLaenge" SG_ 779 OilLifeLeft 40;
BA_ "FlexKomSigStartPos" SG_ 779 OilLifeLeft 7;
BA_ "FlexKomSID" SG_ 779 OilLifeLeft 1668;
BA_ "GenSigTimeout_ETM" SG_ 779 OilLifeLeft 10500;
BA_ "GenSigTimeout_IC" SG_ 779 OilLifeLeft 10500;
BA_ "GenSigStartValue" SG_ 779 OilLifeLeft 255;
BA_ "FlexKomSigStartValue" SG_ 779 OilLifeLeft "FFFFFF0FFFh";
BA_ "GenSigCycleTime" SG_ 779 OilLifeLeft 1000;
BA_ "GenSigSNA" SG_ 779 MntncSts "3h";
BA_ "FlexKomIsMotorola" SG_ 779 MntncSts 1;
BA_ "FlexKomComment" SG_ 779 MntncSts "Oil life packet";
BA_ "FlexKomSigName" SG_ 779 MntncSts "OilLifePkt";
BA_ "FlexKomSigLaenge" SG_ 779 MntncSts 40;
BA_ "FlexKomSigStartPos" SG_ 779 MntncSts 7;
BA_ "FlexKomSID" SG_ 779 MntncSts 1668;
BA_ "GenSigTimeout_ETM" SG_ 779 MntncSts 10500;
BA_ "GenSigTimeout_IC" SG_ 779 MntncSts 10500;
BA_ "FlexKomSigStartValue" SG_ 779 MntncSts "FFFFFF0FFFh";
BA_ "GenSigCycleTime" SG_ 779 MntncSts 1000;
BA_ "GenSigSNA" SG_ 779 HoursOilLifeRst "FFFh";
BA_ "FlexKomIsMotorola" SG_ 779 HoursOilLifeRst 1;
BA_ "FlexKomComment" SG_ 779 HoursOilLifeRst "Oil life packet";
BA_ "FlexKomSigName" SG_ 779 HoursOilLifeRst "OilLifePkt";
BA_ "FlexKomSigLaenge" SG_ 779 HoursOilLifeRst 40;
BA_ "FlexKomSigStartPos" SG_ 779 HoursOilLifeRst 7;
BA_ "FlexKomSID" SG_ 779 HoursOilLifeRst 1668;
BA_ "GenSigTimeout_ETM" SG_ 779 HoursOilLifeRst 10500;
BA_ "GenSigTimeout_IC" SG_ 779 HoursOilLifeRst 10500;
BA_ "GenSigTimeout_CBC" SG_ 779 HoursOilLifeRst 10500;
BA_ "GenSigStartValue" SG_ 779 HoursOilLifeRst 4095;
BA_ "FlexKomSigStartValue" SG_ 779 HoursOilLifeRst "FFFFFF0FFFh";
BA_ "GenSigCycleTime" SG_ 779 HoursOilLifeRst 1000;
BA_ "GenSigCycleTime" SG_ 779 FuelMM_Sts 1000;
BA_ "FlexKomSigStartValue" SG_ 779 FuelMM_Sts "00h";
BA_ "GenSigTimeout_IC" SG_ 779 FuelMM_Sts 10500;
BA_ "FlexKomSID" SG_ 779 FuelMM_Sts 2550;
BA_ "FlexKomSigStartPos" SG_ 779 FuelMM_Sts 47;
BA_ "FlexKomSigLaenge" SG_ 779 FuelMM_Sts 8;
BA_ "FlexKomSigName" SG_ 779 FuelMM_Sts "FuelMM_Sts";
BA_ "FlexKomComment" SG_ 779 FuelMM_Sts "Fuel maintenance mode status";
BA_ "FlexKomIsMotorola" SG_ 779 FuelMM_Sts 1;
BA_ "GenSigSNA" SG_ 779 FuelMM_Sts "0h";
BA_ "GenSigSNA" SG_ 779 DisOilLifeRst "FFFFh";
BA_ "FlexKomIsMotorola" SG_ 779 DisOilLifeRst 1;
BA_ "FlexKomComment" SG_ 779 DisOilLifeRst "Oil life packet";
BA_ "FlexKomSigName" SG_ 779 DisOilLifeRst "OilLifePkt";
BA_ "FlexKomSigLaenge" SG_ 779 DisOilLifeRst 40;
BA_ "FlexKomSigStartPos" SG_ 779 DisOilLifeRst 7;
BA_ "FlexKomSID" SG_ 779 DisOilLifeRst 1668;
BA_ "GenSigTimeout_ETM" SG_ 779 DisOilLifeRst 10500;
BA_ "GenSigTimeout_IC" SG_ 779 DisOilLifeRst 10500;
BA_ "GenSigTimeout_CBC" SG_ 779 DisOilLifeRst 10500;
BA_ "GenSigStartValue" SG_ 779 DisOilLifeRst 65535;
BA_ "FlexKomSigStartValue" SG_ 779 DisOilLifeRst "FFFFFF0FFFh";
BA_ "GenSigCycleTime" SG_ 779 DisOilLifeRst 1000;
BA_ "GenMsgStartValue" BO_ 773 "000000FFFFFFFFFFh";
BA_ "GenMsgNrOfRepetitions" BO_ 773 2;
BA_ "GenMsgDelayTime" BO_ 773 20;
BA_ "GenMsgCycleTime" BO_ 773 1000;
BA_ "GenSigSNA" SG_ 773 TPM_SysStat "7h";
BA_ "FlexKomIsMotorola" SG_ 773 TPM_SysStat 1;
BA_ "FlexKomComment" SG_ 773 TPM_SysStat "Tire Pressure Packet";
BA_ "FlexKomSigName" SG_ 773 TPM_SysStat "TPM_A2_PKT";
BA_ "FlexKomSigLaenge" SG_ 773 TPM_SysStat 64;
BA_ "FlexKomSigStartPos" SG_ 773 TPM_SysStat 7;
BA_ "FlexKomSID" SG_ 773 TPM_SysStat 1611;
BA_ "GenSigTimeout_ORC" SG_ 773 TPM_SysStat 3500;
BA_ "GenSigTimeout_IC" SG_ 773 TPM_SysStat 10500;
BA_ "FlexKomSigStartValue" SG_ 773 TPM_SysStat "000000FFFFFFFFFFh";
BA_ "GenSigCycleTime" SG_ 773 TPM_SysStat 1000;
BA_ "GenSigSNA" SG_ 773 TPM_IndLmpOnRq "3h";
BA_ "FlexKomIsMotorola" SG_ 773 TPM_IndLmpOnRq 1;
BA_ "FlexKomComment" SG_ 773 TPM_IndLmpOnRq "Tire Pressure Packet";
BA_ "FlexKomSigName" SG_ 773 TPM_IndLmpOnRq "TPM_A2_PKT";
BA_ "FlexKomSigLaenge" SG_ 773 TPM_IndLmpOnRq 64;
BA_ "FlexKomSigStartPos" SG_ 773 TPM_IndLmpOnRq 7;
BA_ "FlexKomSID" SG_ 773 TPM_IndLmpOnRq 1611;
BA_ "GenSigTimeout_ETM" SG_ 773 TPM_IndLmpOnRq 10500;
BA_ "GenSigTimeout_ORC" SG_ 773 TPM_IndLmpOnRq 3500;
BA_ "GenSigTimeout_IC" SG_ 773 TPM_IndLmpOnRq 10500;
BA_ "FlexKomSigStartValue" SG_ 773 TPM_IndLmpOnRq "000000FFFFFFFFFFh";
BA_ "GenSigCycleTime" SG_ 773 TPM_IndLmpOnRq 1000;
BA_ "GenSigSNA" SG_ 773 TPM_ChimeRq "0h";
BA_ "FlexKomIsMotorola" SG_ 773 TPM_ChimeRq 1;
BA_ "FlexKomComment" SG_ 773 TPM_ChimeRq "Tire Pressure Packet";
BA_ "FlexKomSigName" SG_ 773 TPM_ChimeRq "TPM_A2_PKT";
BA_ "FlexKomSigLaenge" SG_ 773 TPM_ChimeRq 64;
BA_ "FlexKomSigStartPos" SG_ 773 TPM_ChimeRq 7;
BA_ "FlexKomSID" SG_ 773 TPM_ChimeRq 1611;
BA_ "GenSigTimeout_ORC" SG_ 773 TPM_ChimeRq 3500;
BA_ "GenSigTimeout_IC" SG_ 773 TPM_ChimeRq 10500;
BA_ "FlexKomSigStartValue" SG_ 773 TPM_ChimeRq "000000FFFFFFFFFFh";
BA_ "GenSigCycleTime" SG_ 773 TPM_ChimeRq 1000;
BA_ "GenSigSNA" SG_ 773 TirePrssSpr "FFh";
BA_ "FlexKomIsMotorola" SG_ 773 TirePrssSpr 1;
BA_ "FlexKomComment" SG_ 773 TirePrssSpr "Tire Pressure Packet";
BA_ "FlexKomSigName" SG_ 773 TirePrssSpr "TPM_A2_PKT";
BA_ "FlexKomSigLaenge" SG_ 773 TirePrssSpr 64;
BA_ "FlexKomSigStartPos" SG_ 773 TirePrssSpr 7;
BA_ "FlexKomSID" SG_ 773 TirePrssSpr 1611;
BA_ "GenSigTimeout_ORC" SG_ 773 TirePrssSpr 3500;
BA_ "GenSigTimeout_IC" SG_ 773 TirePrssSpr 10500;
BA_ "GenSigStartValue" SG_ 773 TirePrssSpr 255;
BA_ "FlexKomSigStartValue" SG_ 773 TirePrssSpr "000000FFFFFFFFFFh";
BA_ "GenSigCycleTime" SG_ 773 TirePrssSpr 1000;
BA_ "GenSigSNA" SG_ 773 TirePrssRR "FFh";
BA_ "FlexKomIsMotorola" SG_ 773 TirePrssRR 1;
BA_ "FlexKomComment" SG_ 773 TirePrssRR "Tire Pressure Packet";
BA_ "FlexKomSigName" SG_ 773 TirePrssRR "TPM_A2_PKT";
BA_ "FlexKomSigLaenge" SG_ 773 TirePrssRR 64;
BA_ "FlexKomSigStartPos" SG_ 773 TirePrssRR 7;
BA_ "FlexKomSID" SG_ 773 TirePrssRR 1611;
BA_ "GenSigTimeout_ETM" SG_ 773 TirePrssRR 10500;
BA_ "GenSigTimeout_ORC" SG_ 773 TirePrssRR 3500;
BA_ "GenSigTimeout_IC" SG_ 773 TirePrssRR 10500;
BA_ "GenSigStartValue" SG_ 773 TirePrssRR 255;
BA_ "FlexKomSigStartValue" SG_ 773 TirePrssRR "000000FFFFFFFFFFh";
BA_ "GenSigCycleTime" SG_ 773 TirePrssRR 1000;
BA_ "GenSigSNA" SG_ 773 TirePrssRL "FFh";
BA_ "FlexKomIsMotorola" SG_ 773 TirePrssRL 1;
BA_ "FlexKomComment" SG_ 773 TirePrssRL "Tire Pressure Packet";
BA_ "FlexKomSigName" SG_ 773 TirePrssRL "TPM_A2_PKT";
BA_ "FlexKomSigLaenge" SG_ 773 TirePrssRL 64;
BA_ "FlexKomSigStartPos" SG_ 773 TirePrssRL 7;
BA_ "FlexKomSID" SG_ 773 TirePrssRL 1611;
BA_ "GenSigTimeout_ETM" SG_ 773 TirePrssRL 10500;
BA_ "GenSigTimeout_ORC" SG_ 773 TirePrssRL 3500;
BA_ "GenSigTimeout_IC" SG_ 773 TirePrssRL 10500;
BA_ "GenSigStartValue" SG_ 773 TirePrssRL 255;
BA_ "FlexKomSigStartValue" SG_ 773 TirePrssRL "000000FFFFFFFFFFh";
BA_ "GenSigCycleTime" SG_ 773 TirePrssRL 1000;
BA_ "GenSigSNA" SG_ 773 TirePrssFR "FFh";
BA_ "FlexKomIsMotorola" SG_ 773 TirePrssFR 1;
BA_ "FlexKomComment" SG_ 773 TirePrssFR "Tire Pressure Packet";
BA_ "FlexKomSigName" SG_ 773 TirePrssFR "TPM_A2_PKT";
BA_ "FlexKomSigLaenge" SG_ 773 TirePrssFR 64;
BA_ "FlexKomSigStartPos" SG_ 773 TirePrssFR 7;
BA_ "FlexKomSID" SG_ 773 TirePrssFR 1611;
BA_ "GenSigTimeout_ETM" SG_ 773 TirePrssFR 10500;
BA_ "GenSigTimeout_ORC" SG_ 773 TirePrssFR 3500;
BA_ "GenSigTimeout_IC" SG_ 773 TirePrssFR 10500;
BA_ "GenSigStartValue" SG_ 773 TirePrssFR 255;
BA_ "FlexKomSigStartValue" SG_ 773 TirePrssFR "000000FFFFFFFFFFh";
BA_ "GenSigCycleTime" SG_ 773 TirePrssFR 1000;
BA_ "GenSigSNA" SG_ 773 TirePrssFL "FFh";
BA_ "FlexKomIsMotorola" SG_ 773 TirePrssFL 1;
BA_ "FlexKomComment" SG_ 773 TirePrssFL "Tire Pressure Packet";
BA_ "FlexKomSigName" SG_ 773 TirePrssFL "TPM_A2_PKT";
BA_ "FlexKomSigLaenge" SG_ 773 TirePrssFL 64;
BA_ "FlexKomSigStartPos" SG_ 773 TirePrssFL 7;
BA_ "FlexKomSID" SG_ 773 TirePrssFL 1611;
BA_ "GenSigTimeout_ETM" SG_ 773 TirePrssFL 10500;
BA_ "GenSigTimeout_ORC" SG_ 773 TirePrssFL 3500;
BA_ "GenSigTimeout_IC" SG_ 773 TirePrssFL 10500;
BA_ "GenSigStartValue" SG_ 773 TirePrssFL 255;
BA_ "FlexKomSigStartValue" SG_ 773 TirePrssFL "000000FFFFFFFFFFh";
BA_ "GenSigCycleTime" SG_ 773 TirePrssFL 1000;
BA_ "GenSigSNA" SG_ 773 Tire_Spr "3h";
BA_ "FlexKomIsMotorola" SG_ 773 Tire_Spr 1;
BA_ "FlexKomComment" SG_ 773 Tire_Spr "Tire Pressure Packet";
BA_ "FlexKomSigName" SG_ 773 Tire_Spr "TPM_A2_PKT";
BA_ "FlexKomSigLaenge" SG_ 773 Tire_Spr 64;
BA_ "FlexKomSigStartPos" SG_ 773 Tire_Spr 7;
BA_ "FlexKomSID" SG_ 773 Tire_Spr 1611;
BA_ "GenSigTimeout_ORC" SG_ 773 Tire_Spr 3500;
BA_ "GenSigTimeout_IC" SG_ 773 Tire_Spr 10500;
BA_ "FlexKomSigStartValue" SG_ 773 Tire_Spr "000000FFFFFFFFFFh";
BA_ "GenSigCycleTime" SG_ 773 Tire_Spr 1000;
BA_ "GenSigSNA" SG_ 773 Tire_RR "3h";
BA_ "FlexKomIsMotorola" SG_ 773 Tire_RR 1;
BA_ "FlexKomComment" SG_ 773 Tire_RR "Tire Pressure Packet";
BA_ "FlexKomSigName" SG_ 773 Tire_RR "TPM_A2_PKT";
BA_ "FlexKomSigLaenge" SG_ 773 Tire_RR 64;
BA_ "FlexKomSigStartPos" SG_ 773 Tire_RR 7;
BA_ "FlexKomSID" SG_ 773 Tire_RR 1611;
BA_ "GenSigTimeout_ETM" SG_ 773 Tire_RR 10500;
BA_ "GenSigTimeout_ORC" SG_ 773 Tire_RR 3500;
BA_ "GenSigTimeout_IC" SG_ 773 Tire_RR 10500;
BA_ "FlexKomSigStartValue" SG_ 773 Tire_RR "000000FFFFFFFFFFh";
BA_ "GenSigCycleTime" SG_ 773 Tire_RR 1000;
BA_ "GenSigSNA" SG_ 773 Tire_RL "3h";
BA_ "FlexKomIsMotorola" SG_ 773 Tire_RL 1;
BA_ "FlexKomComment" SG_ 773 Tire_RL "Tire Pressure Packet";
BA_ "FlexKomSigName" SG_ 773 Tire_RL "TPM_A2_PKT";
BA_ "FlexKomSigLaenge" SG_ 773 Tire_RL 64;
BA_ "FlexKomSigStartPos" SG_ 773 Tire_RL 7;
BA_ "FlexKomSID" SG_ 773 Tire_RL 1611;
BA_ "GenSigTimeout_ETM" SG_ 773 Tire_RL 10500;
BA_ "GenSigTimeout_ORC" SG_ 773 Tire_RL 3500;
BA_ "GenSigTimeout_IC" SG_ 773 Tire_RL 10500;
BA_ "FlexKomSigStartValue" SG_ 773 Tire_RL "000000FFFFFFFFFFh";
BA_ "GenSigCycleTime" SG_ 773 Tire_RL 1000;
BA_ "GenSigSNA" SG_ 773 Tire_FR "3h";
BA_ "FlexKomIsMotorola" SG_ 773 Tire_FR 1;
BA_ "FlexKomComment" SG_ 773 Tire_FR "Tire Pressure Packet";
BA_ "FlexKomSigName" SG_ 773 Tire_FR "TPM_A2_PKT";
BA_ "FlexKomSigLaenge" SG_ 773 Tire_FR 64;
BA_ "FlexKomSigStartPos" SG_ 773 Tire_FR 7;
BA_ "FlexKomSID" SG_ 773 Tire_FR 1611;
BA_ "GenSigTimeout_ETM" SG_ 773 Tire_FR 10500;
BA_ "GenSigTimeout_ORC" SG_ 773 Tire_FR 3500;
BA_ "GenSigTimeout_IC" SG_ 773 Tire_FR 10500;
BA_ "FlexKomSigStartValue" SG_ 773 Tire_FR "000000FFFFFFFFFFh";
BA_ "GenSigCycleTime" SG_ 773 Tire_FR 1000;
BA_ "GenSigSNA" SG_ 773 Tire_FL "3h";
BA_ "FlexKomIsMotorola" SG_ 773 Tire_FL 1;
BA_ "FlexKomComment" SG_ 773 Tire_FL "Tire Pressure Packet";
BA_ "FlexKomSigName" SG_ 773 Tire_FL "TPM_A2_PKT";
BA_ "FlexKomSigLaenge" SG_ 773 Tire_FL 64;
BA_ "FlexKomSigStartPos" SG_ 773 Tire_FL 7;
BA_ "FlexKomSID" SG_ 773 Tire_FL 1611;
BA_ "GenSigTimeout_ETM" SG_ 773 Tire_FL 10500;
BA_ "GenSigTimeout_ORC" SG_ 773 Tire_FL 3500;
BA_ "GenSigTimeout_IC" SG_ 773 Tire_FL 10500;
BA_ "FlexKomSigStartValue" SG_ 773 Tire_FL "000000FFFFFFFFFFh";
BA_ "GenSigCycleTime" SG_ 773 Tire_FL 1000;
BA_ "GenSigSNA" SG_ 773 RunFlatTire_Low "0h";
BA_ "FlexKomIsMotorola" SG_ 773 RunFlatTire_Low 1;
BA_ "FlexKomComment" SG_ 773 RunFlatTire_Low "Tire Pressure Packet";
BA_ "FlexKomSigName" SG_ 773 RunFlatTire_Low "TPM_A2_PKT";
BA_ "FlexKomSigLaenge" SG_ 773 RunFlatTire_Low 64;
BA_ "FlexKomSigStartPos" SG_ 773 RunFlatTire_Low 7;
BA_ "FlexKomSID" SG_ 773 RunFlatTire_Low 1611;
BA_ "GenSigTimeout_ORC" SG_ 773 RunFlatTire_Low 3500;
BA_ "GenSigTimeout_IC" SG_ 773 RunFlatTire_Low 10500;
BA_ "FlexKomSigStartValue" SG_ 773 RunFlatTire_Low "000000FFFFFFFFFFh";
BA_ "GenSigCycleTime" SG_ 773 RunFlatTire_Low 1000;
BA_ "GenMsgStartValue" BO_ 766 "FFFFFFFF0000FF00h";
BA_ "GenMsgNrOfRepetitions" BO_ 766 2;
BA_ "GenMsgDelayTime" BO_ 766 20;
BA_ "GenMsgCycleTime" BO_ 766 100;
BA_ "GenSigSNA" SG_ 766 VVT_IntCam2Pos "0h";
BA_ "FlexKomIsMotorola" SG_ 766 VVT_IntCam2Pos 1;
BA_ "FlexKomComment" SG_ 766 VVT_IntCam2Pos "EDR2 information packet only";
BA_ "FlexKomSigName" SG_ 766 VVT_IntCam2Pos "EDR2_Pkt";
BA_ "FlexKomSigLaenge" SG_ 766 VVT_IntCam2Pos 64;
BA_ "FlexKomSigStartPos" SG_ 766 VVT_IntCam2Pos 7;
BA_ "FlexKomSID" SG_ 766 VVT_IntCam2Pos 1093;
BA_ "GenSigTimeout_ORC" SG_ 766 VVT_IntCam2Pos 350;
BA_ "GenSigStartValue" SG_ 766 VVT_IntCam2Pos 255;
BA_ "FlexKomSigStartValue" SG_ 766 VVT_IntCam2Pos "FFFFFFFF0000FF00h";
BA_ "GenSigCycleTime" SG_ 766 VVT_IntCam2Pos 100;
BA_ "GenSigSNA" SG_ 766 VVT_IntCam1Pos "0h";
BA_ "FlexKomIsMotorola" SG_ 766 VVT_IntCam1Pos 1;
BA_ "FlexKomComment" SG_ 766 VVT_IntCam1Pos "EDR2 information packet only";
BA_ "FlexKomSigName" SG_ 766 VVT_IntCam1Pos "EDR2_Pkt";
BA_ "FlexKomSigLaenge" SG_ 766 VVT_IntCam1Pos 64;
BA_ "FlexKomSigStartPos" SG_ 766 VVT_IntCam1Pos 7;
BA_ "FlexKomSID" SG_ 766 VVT_IntCam1Pos 1093;
BA_ "GenSigTimeout_ORC" SG_ 766 VVT_IntCam1Pos 350;
BA_ "GenSigStartValue" SG_ 766 VVT_IntCam1Pos 255;
BA_ "FlexKomSigStartValue" SG_ 766 VVT_IntCam1Pos "FFFFFFFF0000FF00h";
BA_ "GenSigCycleTime" SG_ 766 VVT_IntCam1Pos 100;
BA_ "GenSigSNA" SG_ 766 VVT_ExhCam2Pos "0h";
BA_ "FlexKomIsMotorola" SG_ 766 VVT_ExhCam2Pos 1;
BA_ "FlexKomComment" SG_ 766 VVT_ExhCam2Pos "EDR2 information packet only";
BA_ "FlexKomSigName" SG_ 766 VVT_ExhCam2Pos "EDR2_Pkt";
BA_ "FlexKomSigLaenge" SG_ 766 VVT_ExhCam2Pos 64;
BA_ "FlexKomSigStartPos" SG_ 766 VVT_ExhCam2Pos 7;
BA_ "FlexKomSID" SG_ 766 VVT_ExhCam2Pos 1093;
BA_ "GenSigTimeout_ORC" SG_ 766 VVT_ExhCam2Pos 350;
BA_ "GenSigStartValue" SG_ 766 VVT_ExhCam2Pos 255;
BA_ "FlexKomSigStartValue" SG_ 766 VVT_ExhCam2Pos "FFFFFFFF0000FF00h";
BA_ "GenSigCycleTime" SG_ 766 VVT_ExhCam2Pos 100;
BA_ "GenSigSNA" SG_ 766 VVT_ExhCam1Pos "0h";
BA_ "FlexKomIsMotorola" SG_ 766 VVT_ExhCam1Pos 1;
BA_ "FlexKomComment" SG_ 766 VVT_ExhCam1Pos "EDR2 information packet only";
BA_ "FlexKomSigName" SG_ 766 VVT_ExhCam1Pos "EDR2_Pkt";
BA_ "FlexKomSigLaenge" SG_ 766 VVT_ExhCam1Pos 64;
BA_ "FlexKomSigStartPos" SG_ 766 VVT_ExhCam1Pos 7;
BA_ "FlexKomSID" SG_ 766 VVT_ExhCam1Pos 1093;
BA_ "GenSigTimeout_ORC" SG_ 766 VVT_ExhCam1Pos 350;
BA_ "GenSigStartValue" SG_ 766 VVT_ExhCam1Pos 255;
BA_ "FlexKomSigStartValue" SG_ 766 VVT_ExhCam1Pos "FFFFFFFF0000FF00h";
BA_ "GenSigCycleTime" SG_ 766 VVT_ExhCam1Pos 100;
BA_ "GenSigSNA" SG_ 766 RelativeThrtPct "FFh";
BA_ "FlexKomIsMotorola" SG_ 766 RelativeThrtPct 1;
BA_ "FlexKomComment" SG_ 766 RelativeThrtPct "EDR2 information packet only";
BA_ "FlexKomSigName" SG_ 766 RelativeThrtPct "EDR2_Pkt";
BA_ "FlexKomSigLaenge" SG_ 766 RelativeThrtPct 64;
BA_ "FlexKomSigStartPos" SG_ 766 RelativeThrtPct 7;
BA_ "FlexKomSID" SG_ 766 RelativeThrtPct 1093;
BA_ "GenSigTimeout_ORC" SG_ 766 RelativeThrtPct 350;
BA_ "GenSigStartValue" SG_ 766 RelativeThrtPct 255;
BA_ "FlexKomSigStartValue" SG_ 766 RelativeThrtPct "FFFFFFFF0000FF00h";
BA_ "GenSigCycleTime" SG_ 766 RelativeThrtPct 100;
BA_ "GenSigSNA" SG_ 766 GF_Charge "FFFFh";
BA_ "FlexKomIsMotorola" SG_ 766 GF_Charge 1;
BA_ "FlexKomComment" SG_ 766 GF_Charge "EDR2 information packet only";
BA_ "FlexKomSigName" SG_ 766 GF_Charge "EDR2_Pkt";
BA_ "FlexKomSigLaenge" SG_ 766 GF_Charge 64;
BA_ "FlexKomSigStartPos" SG_ 766 GF_Charge 7;
BA_ "FlexKomSID" SG_ 766 GF_Charge 1093;
BA_ "GenSigTimeout_ORC" SG_ 766 GF_Charge 350;
BA_ "FlexKomSigStartValue" SG_ 766 GF_Charge "FFFFFFFF0000FF00h";
BA_ "GenSigCycleTime" SG_ 766 GF_Charge 100;
BA_ "GenMsgStartValue" BO_ 764 "00FFFFFFFFFFFFFFh";
BA_ "GenMsgNrOfRepetitions" BO_ 764 2;
BA_ "GenMsgDelayTime" BO_ 764 20;
BA_ "GenMsgCycleTime" BO_ 764 100;
BA_ "GenSigSNA" SG_ 764 RelativeThrt "FFh";
BA_ "FlexKomIsMotorola" SG_ 764 RelativeThrt 1;
BA_ "FlexKomComment" SG_ 764 RelativeThrt "EDR Only information packet";
BA_ "FlexKomSigName" SG_ 764 RelativeThrt "EDR_Pkt";
BA_ "FlexKomSigLaenge" SG_ 764 RelativeThrt 64;
BA_ "FlexKomSigStartPos" SG_ 764 RelativeThrt 7;
BA_ "FlexKomSID" SG_ 764 RelativeThrt 762;
BA_ "GenSigTimeout_ORC" SG_ 764 RelativeThrt 350;
BA_ "GenSigStartValue" SG_ 764 RelativeThrt 255;
BA_ "FlexKomSigStartValue" SG_ 764 RelativeThrt "00FFFFFFFFFFFFFFh";
BA_ "GenSigCycleTime" SG_ 764 RelativeThrt 100;
BA_ "GenSigSNA" SG_ 764 RelativePdl "FFh";
BA_ "FlexKomIsMotorola" SG_ 764 RelativePdl 1;
BA_ "FlexKomComment" SG_ 764 RelativePdl "EDR Only information packet";
BA_ "FlexKomSigName" SG_ 764 RelativePdl "EDR_Pkt";
BA_ "FlexKomSigLaenge" SG_ 764 RelativePdl 64;
BA_ "FlexKomSigStartPos" SG_ 764 RelativePdl 7;
BA_ "FlexKomSID" SG_ 764 RelativePdl 762;
BA_ "GenSigTimeout_ORC" SG_ 764 RelativePdl 350;
BA_ "GenSigStartValue" SG_ 764 RelativePdl 255;
BA_ "FlexKomSigStartValue" SG_ 764 RelativePdl "00FFFFFFFFFFFFFFh";
BA_ "GenSigCycleTime" SG_ 764 RelativePdl 100;
BA_ "GenSigSNA" SG_ 764 RawTPS2 "FFh";
BA_ "FlexKomIsMotorola" SG_ 764 RawTPS2 1;
BA_ "FlexKomComment" SG_ 764 RawTPS2 "EDR Only information packet";
BA_ "FlexKomSigName" SG_ 764 RawTPS2 "EDR_Pkt";
BA_ "FlexKomSigLaenge" SG_ 764 RawTPS2 64;
BA_ "FlexKomSigStartPos" SG_ 764 RawTPS2 7;
BA_ "FlexKomSID" SG_ 764 RawTPS2 762;
BA_ "GenSigTimeout_ORC" SG_ 764 RawTPS2 350;
BA_ "GenSigStartValue" SG_ 764 RawTPS2 255;
BA_ "FlexKomSigStartValue" SG_ 764 RawTPS2 "00FFFFFFFFFFFFFFh";
BA_ "GenSigCycleTime" SG_ 764 RawTPS2 100;
BA_ "GenSigSNA" SG_ 764 RawTPS1 "FFh";
BA_ "FlexKomIsMotorola" SG_ 764 RawTPS1 1;
BA_ "FlexKomComment" SG_ 764 RawTPS1 "EDR Only information packet";
BA_ "FlexKomSigName" SG_ 764 RawTPS1 "EDR_Pkt";
BA_ "FlexKomSigLaenge" SG_ 764 RawTPS1 64;
BA_ "FlexKomSigStartPos" SG_ 764 RawTPS1 7;
BA_ "FlexKomSID" SG_ 764 RawTPS1 762;
BA_ "GenSigTimeout_ORC" SG_ 764 RawTPS1 350;
BA_ "GenSigStartValue" SG_ 764 RawTPS1 255;
BA_ "FlexKomSigStartValue" SG_ 764 RawTPS1 "00FFFFFFFFFFFFFFh";
BA_ "GenSigCycleTime" SG_ 764 RawTPS1 100;
BA_ "GenSigSNA" SG_ 764 RawPVS2 "FFh";
BA_ "FlexKomIsMotorola" SG_ 764 RawPVS2 1;
BA_ "FlexKomComment" SG_ 764 RawPVS2 "EDR Only information packet";
BA_ "FlexKomSigName" SG_ 764 RawPVS2 "EDR_Pkt";
BA_ "FlexKomSigLaenge" SG_ 764 RawPVS2 64;
BA_ "FlexKomSigStartPos" SG_ 764 RawPVS2 7;
BA_ "FlexKomSID" SG_ 764 RawPVS2 762;
BA_ "GenSigTimeout_ORC" SG_ 764 RawPVS2 350;
BA_ "GenSigStartValue" SG_ 764 RawPVS2 255;
BA_ "FlexKomSigStartValue" SG_ 764 RawPVS2 "00FFFFFFFFFFFFFFh";
BA_ "GenSigCycleTime" SG_ 764 RawPVS2 100;
BA_ "GenSigSNA" SG_ 764 RawPVS1 "FFh";
BA_ "FlexKomIsMotorola" SG_ 764 RawPVS1 1;
BA_ "FlexKomComment" SG_ 764 RawPVS1 "EDR Only information packet";
BA_ "FlexKomSigName" SG_ 764 RawPVS1 "EDR_Pkt";
BA_ "FlexKomSigLaenge" SG_ 764 RawPVS1 64;
BA_ "FlexKomSigStartPos" SG_ 764 RawPVS1 7;
BA_ "FlexKomSID" SG_ 764 RawPVS1 762;
BA_ "GenSigTimeout_ORC" SG_ 764 RawPVS1 350;
BA_ "GenSigStartValue" SG_ 764 RawPVS1 255;
BA_ "FlexKomSigStartValue" SG_ 764 RawPVS1 "00FFFFFFFFFFFFFFh";
BA_ "GenSigCycleTime" SG_ 764 RawPVS1 100;
BA_ "GenSigSNA" SG_ 764 MAP "FFh";
BA_ "FlexKomIsMotorola" SG_ 764 MAP 1;
BA_ "FlexKomComment" SG_ 764 MAP "EDR Only information packet";
BA_ "FlexKomSigName" SG_ 764 MAP "EDR_Pkt";
BA_ "FlexKomSigLaenge" SG_ 764 MAP 64;
BA_ "FlexKomSigStartPos" SG_ 764 MAP 7;
BA_ "FlexKomSID" SG_ 764 MAP 762;
BA_ "GenSigTimeout_ORC" SG_ 764 MAP 350;
BA_ "GenSigStartValue" SG_ 764 MAP 255;
BA_ "FlexKomSigStartValue" SG_ 764 MAP "00FFFFFFFFFFFFFFh";
BA_ "GenSigCycleTime" SG_ 764 MAP 100;
BA_ "GenSigSNA" SG_ 764 Lv1CrsCtrlOff "0h";
BA_ "FlexKomIsMotorola" SG_ 764 Lv1CrsCtrlOff 1;
BA_ "FlexKomComment" SG_ 764 Lv1CrsCtrlOff "EDR Only information packet";
BA_ "FlexKomSigName" SG_ 764 Lv1CrsCtrlOff "EDR_Pkt";
BA_ "FlexKomSigLaenge" SG_ 764 Lv1CrsCtrlOff 64;
BA_ "FlexKomSigStartPos" SG_ 764 Lv1CrsCtrlOff 7;
BA_ "FlexKomSID" SG_ 764 Lv1CrsCtrlOff 762;
BA_ "GenSigTimeout_ORC" SG_ 764 Lv1CrsCtrlOff 350;
BA_ "FlexKomSigStartValue" SG_ 764 Lv1CrsCtrlOff "00FFFFFFFFFFFFFFh";
BA_ "GenSigCycleTime" SG_ 764 Lv1CrsCtrlOff 100;
BA_ "GenSigSNA" SG_ 764 ETC_LmpOn "0h";
BA_ "FlexKomIsMotorola" SG_ 764 ETC_LmpOn 1;
BA_ "FlexKomComment" SG_ 764 ETC_LmpOn "EDR Only information packet";
BA_ "FlexKomSigName" SG_ 764 ETC_LmpOn "EDR_Pkt";
BA_ "FlexKomSigLaenge" SG_ 764 ETC_LmpOn 64;
BA_ "FlexKomSigStartPos" SG_ 764 ETC_LmpOn 7;
BA_ "FlexKomSID" SG_ 764 ETC_LmpOn 762;
BA_ "GenSigTimeout_ORC" SG_ 764 ETC_LmpOn 350;
BA_ "FlexKomSigStartValue" SG_ 764 ETC_LmpOn "00FFFFFFFFFFFFFFh";
BA_ "GenSigCycleTime" SG_ 764 ETC_LmpOn 100;
BA_ "GenSigSNA" SG_ 764 ETC_LmpFlash "0h";
BA_ "FlexKomIsMotorola" SG_ 764 ETC_LmpFlash 1;
BA_ "FlexKomComment" SG_ 764 ETC_LmpFlash "EDR Only information packet";
BA_ "FlexKomSigName" SG_ 764 ETC_LmpFlash "EDR_Pkt";
BA_ "FlexKomSigLaenge" SG_ 764 ETC_LmpFlash 64;
BA_ "FlexKomSigStartPos" SG_ 764 ETC_LmpFlash 7;
BA_ "FlexKomSID" SG_ 764 ETC_LmpFlash 762;
BA_ "GenSigTimeout_ORC" SG_ 764 ETC_LmpFlash 350;
BA_ "FlexKomSigStartValue" SG_ 764 ETC_LmpFlash "00FFFFFFFFFFFFFFh";
BA_ "GenSigCycleTime" SG_ 764 ETC_LmpFlash 100;
BA_ "GenSigSNA" SG_ 764 ESP_TrqRqEnabl "0h";
BA_ "FlexKomIsMotorola" SG_ 764 ESP_TrqRqEnabl 1;
BA_ "FlexKomComment" SG_ 764 ESP_TrqRqEnabl "EDR Only information packet";
BA_ "FlexKomSigName" SG_ 764 ESP_TrqRqEnabl "EDR_Pkt";
BA_ "FlexKomSigLaenge" SG_ 764 ESP_TrqRqEnabl 64;
BA_ "FlexKomSigStartPos" SG_ 764 ESP_TrqRqEnabl 7;
BA_ "FlexKomSID" SG_ 764 ESP_TrqRqEnabl 762;
BA_ "GenSigTimeout_ORC" SG_ 764 ESP_TrqRqEnabl 350;
BA_ "FlexKomSigStartValue" SG_ 764 ESP_TrqRqEnabl "00FFFFFFFFFFFFFFh";
BA_ "GenSigCycleTime" SG_ 764 ESP_TrqRqEnabl 100;
BA_ "GenSigSNA" SG_ 764 CruiseEGD "0h";
BA_ "FlexKomIsMotorola" SG_ 764 CruiseEGD 1;
BA_ "FlexKomComment" SG_ 764 CruiseEGD "EDR Only information packet";
BA_ "FlexKomSigName" SG_ 764 CruiseEGD "EDR_Pkt";
BA_ "FlexKomSigLaenge" SG_ 764 CruiseEGD 64;
BA_ "FlexKomSigStartPos" SG_ 764 CruiseEGD 7;
BA_ "FlexKomSID" SG_ 764 CruiseEGD 762;
BA_ "GenSigTimeout_ORC" SG_ 764 CruiseEGD 350;
BA_ "FlexKomSigStartValue" SG_ 764 CruiseEGD "00FFFFFFFFFFFFFFh";
BA_ "GenSigCycleTime" SG_ 764 CruiseEGD 100;
BA_ "GenSigSNA" SG_ 764 BrkSw1Stat "0h";
BA_ "FlexKomIsMotorola" SG_ 764 BrkSw1Stat 1;
BA_ "FlexKomComment" SG_ 764 BrkSw1Stat "EDR Only information packet";
BA_ "FlexKomSigName" SG_ 764 BrkSw1Stat "EDR_Pkt";
BA_ "FlexKomSigLaenge" SG_ 764 BrkSw1Stat 64;
BA_ "FlexKomSigStartPos" SG_ 764 BrkSw1Stat 7;
BA_ "FlexKomSID" SG_ 764 BrkSw1Stat 762;
BA_ "FlexKomSigStartValue" SG_ 764 BrkSw1Stat "00FFFFFFFFFFFFFFh";
BA_ "GenSigCycleTime" SG_ 764 BrkSw1Stat 100;
BA_ "GenSigSNA" SG_ 764 ApplyTrq "0h";
BA_ "FlexKomIsMotorola" SG_ 764 ApplyTrq 1;
BA_ "FlexKomComment" SG_ 764 ApplyTrq "EDR Only information packet";
BA_ "FlexKomSigName" SG_ 764 ApplyTrq "EDR_Pkt";
BA_ "FlexKomSigLaenge" SG_ 764 ApplyTrq 64;
BA_ "FlexKomSigStartPos" SG_ 764 ApplyTrq 7;
BA_ "FlexKomSID" SG_ 764 ApplyTrq 762;
BA_ "GenSigTimeout_ORC" SG_ 764 ApplyTrq 350;
BA_ "FlexKomSigStartValue" SG_ 764 ApplyTrq "00FFFFFFFFFFFFFFh";
BA_ "GenSigCycleTime" SG_ 764 ApplyTrq 100;
BA_ "GenMsgStartValue" BO_ 760 "5FFF1FFF00FF0FFFh";
BA_ "GenMsgNrOfRepetitions" BO_ 760 2;
BA_ "GenMsgDelayTime" BO_ 760 20;
BA_ "GenMsgCycleTime" BO_ 760 10;
BA_ "GenSigSNA" SG_ 760 MC_ECM_A3 "0h";
BA_ "FlexKomIsMotorola" SG_ 760 MC_ECM_A3 1;
BA_ "FlexKomComment" SG_ 760 MC_ECM_A3 "ECM_A3 message packet";
BA_ "FlexKomSigName" SG_ 760 MC_ECM_A3 "ECM_A3_PKT";
BA_ "FlexKomSigLaenge" SG_ 760 MC_ECM_A3 64;
BA_ "FlexKomSigStartPos" SG_ 760 MC_ECM_A3 7;
BA_ "FlexKomSID" SG_ 760 MC_ECM_A3 1369;
BA_ "FlexKomSigStartValue" SG_ 760 MC_ECM_A3 "5FFF1FFF00FF0FFFh";
BA_ "GenSigCycleTime" SG_ 760 MC_ECM_A3 10;
BA_ "GenSigSNA" SG_ 760 ESS_ENG_ST "Fh";
BA_ "FlexKomIsMotorola" SG_ 760 ESS_ENG_ST 1;
BA_ "FlexKomComment" SG_ 760 ESS_ENG_ST "ECM_A3 message packet";
BA_ "FlexKomSigName" SG_ 760 ESS_ENG_ST "ECM_A3_PKT";
BA_ "FlexKomSigLaenge" SG_ 760 ESS_ENG_ST 64;
BA_ "FlexKomSigStartPos" SG_ 760 ESS_ENG_ST 7;
BA_ "FlexKomSID" SG_ 760 ESS_ENG_ST 1369;
BA_ "GenSigTimeout_ORC" SG_ 760 ESS_ENG_ST 35;
BA_ "GenSigTimeout_CBC" SG_ 760 ESS_ENG_ST 105;
BA_ "GenSigStartValue" SG_ 760 ESS_ENG_ST 15;
BA_ "FlexKomSigStartValue" SG_ 760 ESS_ENG_ST "5FFF1FFF00FF0FFFh";
BA_ "GenSigCycleTime" SG_ 760 ESS_ENG_ST 10;
BA_ "GenSigSNA" SG_ 760 CRC_ECM_A3 "FFh";
BA_ "FlexKomIsMotorola" SG_ 760 CRC_ECM_A3 1;
BA_ "FlexKomComment" SG_ 760 CRC_ECM_A3 "ECM_A3 message packet";
BA_ "FlexKomSigName" SG_ 760 CRC_ECM_A3 "ECM_A3_PKT";
BA_ "FlexKomSigLaenge" SG_ 760 CRC_ECM_A3 64;
BA_ "FlexKomSigStartPos" SG_ 760 CRC_ECM_A3 7;
BA_ "FlexKomSID" SG_ 760 CRC_ECM_A3 1369;
BA_ "GenSigStartValue" SG_ 760 CRC_ECM_A3 255;
BA_ "FlexKomSigStartValue" SG_ 760 CRC_ECM_A3 "5FFF1FFF00FF0FFFh";
BA_ "GenSigCycleTime" SG_ 760 CRC_ECM_A3 10;
BA_ "GenMsgStartValue" BO_ 746 "00000000FFh";
BA_ "GenMsgNrOfRepetitions" BO_ 746 2;
BA_ "GenMsgDelayTime" BO_ 746 20;
BA_ "GenMsgCycleTime" BO_ 746 20;
BA_ "GenSigSNA" SG_ 746 ShftSensFltROT "0h";
BA_ "FlexKomIsMotorola" SG_ 746 ShftSensFltROT 1;
BA_ "FlexKomComment" SG_ 746 ShftSensFltROT "Shift by wire - rotary 1 packet";
BA_ "FlexKomSigName" SG_ 746 ShftSensFltROT "SBW_ROT1_PKT";
BA_ "FlexKomSigLaenge" SG_ 746 ShftSensFltROT 40;
BA_ "FlexKomSigStartPos" SG_ 746 ShftSensFltROT 7;
BA_ "FlexKomSID" SG_ 746 ShftSensFltROT 1661;
BA_ "FlexKomSigStartValue" SG_ 746 ShftSensFltROT "00000000FFh";
BA_ "GenSigCycleTime" SG_ 746 ShftSensFltROT 20;
BA_ "GenSigSNA" SG_ 746 ShftLkFltROT "0h";
BA_ "FlexKomIsMotorola" SG_ 746 ShftLkFltROT 1;
BA_ "FlexKomComment" SG_ 746 ShftLkFltROT "Shift by wire - rotary 1 packet";
BA_ "FlexKomSigName" SG_ 746 ShftLkFltROT "SBW_ROT1_PKT";
BA_ "FlexKomSigLaenge" SG_ 746 ShftLkFltROT 40;
BA_ "FlexKomSigStartPos" SG_ 746 ShftLkFltROT 7;
BA_ "FlexKomSID" SG_ 746 ShftLkFltROT 1661;
BA_ "FlexKomSigStartValue" SG_ 746 ShftLkFltROT "00000000FFh";
BA_ "GenSigCycleTime" SG_ 746 ShftLkFltROT 20;
BA_ "GenSigSNA" SG_ 746 ShftDispFltROT "0h";
BA_ "FlexKomIsMotorola" SG_ 746 ShftDispFltROT 1;
BA_ "FlexKomComment" SG_ 746 ShftDispFltROT "Shift by wire - rotary 1 packet";
BA_ "FlexKomSigName" SG_ 746 ShftDispFltROT "SBW_ROT1_PKT";
BA_ "FlexKomSigLaenge" SG_ 746 ShftDispFltROT 40;
BA_ "FlexKomSigStartPos" SG_ 746 ShftDispFltROT 7;
BA_ "FlexKomSID" SG_ 746 ShftDispFltROT 1661;
BA_ "FlexKomSigStartValue" SG_ 746 ShftDispFltROT "00000000FFh";
BA_ "GenSigCycleTime" SG_ 746 ShftDispFltROT 20;
BA_ "GenSigSNA" SG_ 746 RackFlt "0h";
BA_ "FlexKomIsMotorola" SG_ 746 RackFlt 1;
BA_ "FlexKomComment" SG_ 746 RackFlt "Shift by wire - rotary 1 packet";
BA_ "FlexKomSigName" SG_ 746 RackFlt "SBW_ROT1_PKT";
BA_ "FlexKomSigLaenge" SG_ 746 RackFlt 40;
BA_ "FlexKomSigStartPos" SG_ 746 RackFlt 7;
BA_ "FlexKomSID" SG_ 746 RackFlt 1661;
BA_ "FlexKomSigStartValue" SG_ 746 RackFlt "00000000FFh";
BA_ "GenSigCycleTime" SG_ 746 RackFlt 20;
BA_ "GenSigSNA" SG_ 746 MC_SBW_ROT1 "0h";
BA_ "FlexKomIsMotorola" SG_ 746 MC_SBW_ROT1 1;
BA_ "FlexKomComment" SG_ 746 MC_SBW_ROT1 "Shift by wire - rotary 1 packet";
BA_ "FlexKomSigName" SG_ 746 MC_SBW_ROT1 "SBW_ROT1_PKT";
BA_ "FlexKomSigLaenge" SG_ 746 MC_SBW_ROT1 40;
BA_ "FlexKomSigStartPos" SG_ 746 MC_SBW_ROT1 7;
BA_ "FlexKomSID" SG_ 746 MC_SBW_ROT1 1661;
BA_ "FlexKomSigStartValue" SG_ 746 MC_SBW_ROT1 "00000000FFh";
BA_ "GenSigCycleTime" SG_ 746 MC_SBW_ROT1 20;
BA_ "GenSigSNA" SG_ 746 DrvRqShftROT "7h";
BA_ "FlexKomIsMotorola" SG_ 746 DrvRqShftROT 1;
BA_ "FlexKomComment" SG_ 746 DrvRqShftROT "Shift by wire - rotary 1 packet";
BA_ "FlexKomSigName" SG_ 746 DrvRqShftROT "SBW_ROT1_PKT";
BA_ "FlexKomSigLaenge" SG_ 746 DrvRqShftROT 40;
BA_ "FlexKomSigStartPos" SG_ 746 DrvRqShftROT 7;
BA_ "FlexKomSID" SG_ 746 DrvRqShftROT 1661;
BA_ "GenSigTimeout_RF_HUB" SG_ 746 DrvRqShftROT 210;
BA_ "FlexKomSigStartValue" SG_ 746 DrvRqShftROT "00000000FFh";
BA_ "GenSigCycleTime" SG_ 746 DrvRqShftROT 20;
BA_ "GenSigSNA" SG_ 746 CRC_SBW_ROT1 "FFh";
BA_ "FlexKomIsMotorola" SG_ 746 CRC_SBW_ROT1 1;
BA_ "FlexKomComment" SG_ 746 CRC_SBW_ROT1 "Shift by wire - rotary 1 packet";
BA_ "FlexKomSigName" SG_ 746 CRC_SBW_ROT1 "SBW_ROT1_PKT";
BA_ "FlexKomSigLaenge" SG_ 746 CRC_SBW_ROT1 40;
BA_ "FlexKomSigStartPos" SG_ 746 CRC_SBW_ROT1 7;
BA_ "FlexKomSID" SG_ 746 CRC_SBW_ROT1 1661;
BA_ "GenSigStartValue" SG_ 746 CRC_SBW_ROT1 255;
BA_ "FlexKomSigStartValue" SG_ 746 CRC_SBW_ROT1 "00000000FFh";
BA_ "GenSigCycleTime" SG_ 746 CRC_SBW_ROT1 20;
BA_ "GenSigSNA" SG_ 746 APCM_Stat "3h";
BA_ "FlexKomIsMotorola" SG_ 746 APCM_Stat 1;
BA_ "FlexKomComment" SG_ 746 APCM_Stat "Shift by wire - rotary 1 packet";
BA_ "FlexKomSigName" SG_ 746 APCM_Stat "SBW_ROT1_PKT";
BA_ "FlexKomSigLaenge" SG_ 746 APCM_Stat 40;
BA_ "FlexKomSigStartPos" SG_ 746 APCM_Stat 7;
BA_ "FlexKomSID" SG_ 746 APCM_Stat 1661;
BA_ "FlexKomSigStartValue" SG_ 746 APCM_Stat "00000000FFh";
BA_ "GenSigCycleTime" SG_ 746 APCM_Stat 20;
BA_ "GenMsgStartValue" BO_ 737 "C1FE01FE00000000h";
BA_ "GenMsgNrOfRepetitions" BO_ 737 2;
BA_ "GenMsgDelayTime" BO_ 737 20;
BA_ "GenMsgCycleTime" BO_ 737 100;
BA_ "GenSigSNA" SG_ 737 MIL_OnRq_ESC "0h";
BA_ "FlexKomIsMotorola" SG_ 737 MIL_OnRq_ESC 1;
BA_ "FlexKomComment" SG_ 737 MIL_OnRq_ESC "MIL on request from the ESC";
BA_ "FlexKomSigName" SG_ 737 MIL_OnRq_ESC "MIL_OnRq_ESC";
BA_ "FlexKomSigLaenge" SG_ 737 MIL_OnRq_ESC 1;
BA_ "FlexKomSigStartPos" SG_ 737 MIL_OnRq_ESC 2;
BA_ "FlexKomSID" SG_ 737 MIL_OnRq_ESC 2375;
BA_ "FlexKomSigStartValue" SG_ 737 MIL_OnRq_ESC "00h";
BA_ "GenSigCycleTime" SG_ 737 MIL_OnRq_ESC 100;
BA_ "GenSigSNA" SG_ 737 ESCSysEmsMlfAtv "0h";
BA_ "FlexKomIsMotorola" SG_ 737 ESCSysEmsMlfAtv 1;
BA_ "FlexKomComment" SG_ 737 ESCSysEmsMlfAtv "ESC emissions related malfunction active";
BA_ "FlexKomSigName" SG_ 737 ESCSysEmsMlfAtv "ESCSysEmsMlfAtv";
BA_ "FlexKomSigLaenge" SG_ 737 ESCSysEmsMlfAtv 1;
BA_ "FlexKomSigStartPos" SG_ 737 ESCSysEmsMlfAtv 18;
BA_ "FlexKomSID" SG_ 737 ESCSysEmsMlfAtv 2376;
BA_ "FlexKomSigStartValue" SG_ 737 ESCSysEmsMlfAtv "00h";
BA_ "GenSigCycleTime" SG_ 737 ESCSysEmsMlfAtv 100;
BA_ "GenMsgStartValue" BO_ 736 "FFFFFFFF0000003Fh";
BA_ "GenMsgNrOfRepetitions" BO_ 736 2;
BA_ "GenMsgDelayTime" BO_ 736 20;
BA_ "GenMsgCycleTime" BO_ 736 50;
BA_ "GenSigSNA" SG_ 736 YRS_DataRq "0h";
BA_ "FlexKomIsMotorola" SG_ 736 YRS_DataRq 1;
BA_ "FlexKomComment" SG_ 736 YRS_DataRq "Request from ESC for YRS information";
BA_ "FlexKomSigName" SG_ 736 YRS_DataRq "YRS_DataRq";
BA_ "FlexKomSigLaenge" SG_ 736 YRS_DataRq 1;
BA_ "FlexKomSigStartPos" SG_ 736 YRS_DataRq 32;
BA_ "FlexKomSID" SG_ 736 YRS_DataRq 1589;
BA_ "GenSigTimeout_ORC" SG_ 736 YRS_DataRq 175;
BA_ "FlexKomSigStartValue" SG_ 736 YRS_DataRq "00h";
BA_ "GenSigCycleTime" SG_ 736 YRS_DataRq 50;
BA_ "GenSigSNA" SG_ 736 RT_DIST "FFFFh";
BA_ "FlexKomIsMotorola" SG_ 736 RT_DIST 1;
BA_ "FlexKomComment" SG_ 736 RT_DIST "Distance traveled by wheels";
BA_ "FlexKomSigName" SG_ 736 RT_DIST "ESP_DIST";
BA_ "FlexKomSigLaenge" SG_ 736 RT_DIST 32;
BA_ "FlexKomSigStartPos" SG_ 736 RT_DIST 7;
BA_ "FlexKomSID" SG_ 736 RT_DIST 395;
BA_ "GenSigTimeout_PTS" SG_ 736 RT_DIST 525;
BA_ "GenSigTimeout_IC" SG_ 736 RT_DIST 525;
BA_ "GenSigTimeout_CBC" SG_ 736 RT_DIST 525;
BA_ "GenSigStartValue" SG_ 736 RT_DIST 65535;
BA_ "FlexKomSigStartValue" SG_ 736 RT_DIST "FFFFFFFFh";
BA_ "GenSigCycleTime" SG_ 736 RT_DIST 50;
BA_ "GenSigSNA" SG_ 736 LT_DIST "FFFFh";
BA_ "FlexKomIsMotorola" SG_ 736 LT_DIST 1;
BA_ "FlexKomComment" SG_ 736 LT_DIST "Distance traveled by wheels";
BA_ "FlexKomSigName" SG_ 736 LT_DIST "ESP_DIST";
BA_ "FlexKomSigLaenge" SG_ 736 LT_DIST 32;
BA_ "FlexKomSigStartPos" SG_ 736 LT_DIST 7;
BA_ "FlexKomSID" SG_ 736 LT_DIST 395;
BA_ "GenSigTimeout_PTS" SG_ 736 LT_DIST 525;
BA_ "GenSigTimeout_IC" SG_ 736 LT_DIST 525;
BA_ "GenSigTimeout_CBC" SG_ 736 LT_DIST 525;
BA_ "GenSigStartValue" SG_ 736 LT_DIST 65535;
BA_ "FlexKomSigStartValue" SG_ 736 LT_DIST "FFFFFFFFh";
BA_ "GenSigCycleTime" SG_ 736 LT_DIST 50;
BA_ "GenSigSNA" SG_ 736 HSA_EN "0h";
BA_ "FlexKomIsMotorola" SG_ 736 HSA_EN 1;
BA_ "FlexKomComment" SG_ 736 HSA_EN "ESP feature present and enabled";
BA_ "FlexKomSigName" SG_ 736 HSA_EN "EBC_Feature_Status";
BA_ "FlexKomSigLaenge" SG_ 736 HSA_EN 8;
BA_ "FlexKomSigStartPos" SG_ 736 HSA_EN 47;
BA_ "FlexKomSID" SG_ 736 HSA_EN 396;
BA_ "GenSigTimeout_IC" SG_ 736 HSA_EN 525;
BA_ "FlexKomSigStartValue" SG_ 736 HSA_EN "00h";
BA_ "GenSigCycleTime" SG_ 736 HSA_EN 50;
BA_ "GenSigSNA" SG_ 736 ESP_Off_IndLmp_On_Rq "0h";
BA_ "FlexKomIsMotorola" SG_ 736 ESP_Off_IndLmp_On_Rq 1;
BA_ "FlexKomComment" SG_ 736 ESP_Off_IndLmp_On_Rq "ESP Customer Indicators";
BA_ "FlexKomSigName" SG_ 736 ESP_Off_IndLmp_On_Rq "ESP_HMI";
BA_ "FlexKomSigLaenge" SG_ 736 ESP_Off_IndLmp_On_Rq 16;
BA_ "FlexKomSigStartPos" SG_ 736 ESP_Off_IndLmp_On_Rq 55;
BA_ "FlexKomSID" SG_ 736 ESP_Off_IndLmp_On_Rq 397;
BA_ "GenSigTimeout_ETM" SG_ 736 ESP_Off_IndLmp_On_Rq 525;
BA_ "GenSigTimeout_ORC" SG_ 736 ESP_Off_IndLmp_On_Rq 175;
BA_ "GenSigTimeout_IC" SG_ 736 ESP_Off_IndLmp_On_Rq 275;
BA_ "FlexKomSigStartValue" SG_ 736 ESP_Off_IndLmp_On_Rq "003Fh";
BA_ "GenSigCycleTime" SG_ 736 ESP_Off_IndLmp_On_Rq 50;
BA_ "GenSigSNA" SG_ 736 ESC_CtrlLmp_Info "3h";
BA_ "FlexKomIsMotorola" SG_ 736 ESC_CtrlLmp_Info 1;
BA_ "FlexKomComment" SG_ 736 ESC_CtrlLmp_Info "ESP Customer Indicators";
BA_ "FlexKomSigName" SG_ 736 ESC_CtrlLmp_Info "ESP_HMI";
BA_ "FlexKomSigLaenge" SG_ 736 ESC_CtrlLmp_Info 16;
BA_ "FlexKomSigStartPos" SG_ 736 ESC_CtrlLmp_Info 55;
BA_ "FlexKomSID" SG_ 736 ESC_CtrlLmp_Info 397;
BA_ "GenSigTimeout_ETM" SG_ 736 ESC_CtrlLmp_Info 525;
BA_ "GenSigTimeout_ORC" SG_ 736 ESC_CtrlLmp_Info 175;
BA_ "GenSigTimeout_IC" SG_ 736 ESC_CtrlLmp_Info 275;
BA_ "GenSigStartValue" SG_ 736 ESC_CtrlLmp_Info 3;
BA_ "FlexKomSigStartValue" SG_ 736 ESC_CtrlLmp_Info "003Fh";
BA_ "GenSigCycleTime" SG_ 736 ESC_CtrlLmp_Info 50;
BA_ "GenSigSNA" SG_ 736 BrkIndLmp_On_Rq_ESC "3h";
BA_ "FlexKomIsMotorola" SG_ 736 BrkIndLmp_On_Rq_ESC 1;
BA_ "FlexKomComment" SG_ 736 BrkIndLmp_On_Rq_ESC "ESP Customer Indicators";
BA_ "FlexKomSigName" SG_ 736 BrkIndLmp_On_Rq_ESC "ESP_HMI";
BA_ "FlexKomSigLaenge" SG_ 736 BrkIndLmp_On_Rq_ESC 16;
BA_ "FlexKomSigStartPos" SG_ 736 BrkIndLmp_On_Rq_ESC 55;
BA_ "FlexKomSID" SG_ 736 BrkIndLmp_On_Rq_ESC 397;
BA_ "GenSigTimeout_ETM" SG_ 736 BrkIndLmp_On_Rq_ESC 525;
BA_ "GenSigTimeout_IC" SG_ 736 BrkIndLmp_On_Rq_ESC 275;
BA_ "GenSigStartValue" SG_ 736 BrkIndLmp_On_Rq_ESC 3;
BA_ "FlexKomSigStartValue" SG_ 736 BrkIndLmp_On_Rq_ESC "003Fh";
BA_ "GenSigCycleTime" SG_ 736 BrkIndLmp_On_Rq_ESC 50;
BA_ "GenSigSNA" SG_ 736 ABS_IndLmp_On_Rq "3h";
BA_ "FlexKomIsMotorola" SG_ 736 ABS_IndLmp_On_Rq 1;
BA_ "FlexKomComment" SG_ 736 ABS_IndLmp_On_Rq "ESP Customer Indicators";
BA_ "FlexKomSigName" SG_ 736 ABS_IndLmp_On_Rq "ESP_HMI";
BA_ "FlexKomSigLaenge" SG_ 736 ABS_IndLmp_On_Rq 16;
BA_ "FlexKomSigStartPos" SG_ 736 ABS_IndLmp_On_Rq 55;
BA_ "FlexKomSID" SG_ 736 ABS_IndLmp_On_Rq 397;
BA_ "GenSigTimeout_ETM" SG_ 736 ABS_IndLmp_On_Rq 525;
BA_ "GenSigTimeout_IC" SG_ 736 ABS_IndLmp_On_Rq 275;
BA_ "GenSigStartValue" SG_ 736 ABS_IndLmp_On_Rq 3;
BA_ "FlexKomSigStartValue" SG_ 736 ABS_IndLmp_On_Rq "003Fh";
BA_ "GenSigCycleTime" SG_ 736 ABS_IndLmp_On_Rq 50;
BA_ "GenMsgStartValue" BO_ 729 "0000000020h";
BA_ "GenMsgNrOfRepetitions" BO_ 729 2;
BA_ "GenMsgDelayTime" BO_ 729 20;
BA_ "GenMsgCycleTime" BO_ 729 100;
BA_ "GenMsgSendType" BO_ 729 5;
BA_ "GenSigSNA" SG_ 729 TorqueIntensitySts "7h";
BA_ "FlexKomIsMotorola" SG_ 729 TorqueIntensitySts 1;
BA_ "FlexKomComment" SG_ 729 TorqueIntensitySts "LDW Torque Intesity Level";
BA_ "FlexKomSigName" SG_ 729 TorqueIntensitySts "TorqueIntensitySts";
BA_ "FlexKomSigLaenge" SG_ 729 TorqueIntensitySts 3;
BA_ "FlexKomSigStartPos" SG_ 729 TorqueIntensitySts 28;
BA_ "FlexKomSID" SG_ 729 TorqueIntensitySts 2025;
BA_ "GenSigTimeout_CBC" SG_ 729 TorqueIntensitySts 1050;
BA_ "FlexKomSigStartValue" SG_ 729 TorqueIntensitySts "00h";
BA_ "GenSigCycleTime" SG_ 729 TorqueIntensitySts 100;
BA_ "GenSigSendType" SG_ 729 TorqueIntensitySts 5;
BA_ "GenSigSNA" SG_ 729 LDW_LEDControlSts "3h";
BA_ "FlexKomIsMotorola" SG_ 729 LDW_LEDControlSts 1;
BA_ "FlexKomComment" SG_ 729 LDW_LEDControlSts "LDW switch LED status";
BA_ "FlexKomSigName" SG_ 729 LDW_LEDControlSts "LDW_LEDControlSts";
BA_ "FlexKomSigLaenge" SG_ 729 LDW_LEDControlSts 2;
BA_ "FlexKomSigStartPos" SG_ 729 LDW_LEDControlSts 25;
BA_ "FlexKomSID" SG_ 729 LDW_LEDControlSts 2024;
BA_ "GenSigTimeout_CBC" SG_ 729 LDW_LEDControlSts 1050;
BA_ "FlexKomSigStartValue" SG_ 729 LDW_LEDControlSts "00h";
BA_ "GenSigCycleTime" SG_ 729 LDW_LEDControlSts 100;
BA_ "GenSigSendType" SG_ 729 LDW_LEDControlSts 5;
BA_ "GenSigSNA" SG_ 729 HALF_AHB_On "0h";
BA_ "FlexKomIsMotorola" SG_ 729 HALF_AHB_On 1;
BA_ "FlexKomComment" SG_ 729 HALF_AHB_On "Auto high beam on request from the HALF ECU";
BA_ "FlexKomSigName" SG_ 729 HALF_AHB_On "HALF_AHB_On";
BA_ "FlexKomSigLaenge" SG_ 729 HALF_AHB_On 1;
BA_ "FlexKomSigStartPos" SG_ 729 HALF_AHB_On 31;
BA_ "FlexKomSID" SG_ 729 HALF_AHB_On 1877;
BA_ "FlexKomSigStartValue" SG_ 729 HALF_AHB_On "00h";
BA_ "GenSigCycleTime" SG_ 729 HALF_AHB_On 100;
BA_ "GenSigSendType" SG_ 729 HALF_AHB_On 5;
BA_ "GenSigSNA" SG_ 729 ConfigSts "7h";
BA_ "FlexKomIsMotorola" SG_ 729 ConfigSts 1;
BA_ "FlexKomComment" SG_ 729 ConfigSts "Configuration status";
BA_ "FlexKomSigName" SG_ 729 ConfigSts "ConfigSts";
BA_ "FlexKomSigLaenge" SG_ 729 ConfigSts 3;
BA_ "FlexKomSigStartPos" SG_ 729 ConfigSts 38;
BA_ "FlexKomSID" SG_ 729 ConfigSts 1638;
BA_ "GenSigStartValue" SG_ 729 ConfigSts 2;
BA_ "FlexKomSigStartValue" SG_ 729 ConfigSts "02h";
BA_ "GenSigCycleTime" SG_ 729 ConfigSts 100;
BA_ "GenSigSendType" SG_ 729 ConfigSts 5;
BA_ "GenMsgStartValue" BO_ 720 "0003C0000000h";
BA_ "GenMsgNrOfRepetitions" BO_ 720 2;
BA_ "GenMsgDelayTime" BO_ 720 20;
BA_ "GenMsgCycleTime" BO_ 720 500;
BA_ "GenMsgSendType" BO_ 720 5;
BA_ "GenSigSNA" SG_ 720 BSM_SRV_RQ "0h";
BA_ "FlexKomIsMotorola" SG_ 720 BSM_SRV_RQ 1;
BA_ "FlexKomComment" SG_ 720 BSM_SRV_RQ "BSM service warning request; 1= service request";
BA_ "FlexKomSigName" SG_ 720 BSM_SRV_RQ "BSM_SRV_RQ";
BA_ "FlexKomSigLaenge" SG_ 720 BSM_SRV_RQ 1;
BA_ "FlexKomSigStartPos" SG_ 720 BSM_SRV_RQ 10;
BA_ "FlexKomSID" SG_ 720 BSM_SRV_RQ 6;
BA_ "GenSigTimeout_HaLF" SG_ 720 BSM_SRV_RQ 5250;
BA_ "GenSigTimeout_IC" SG_ 720 BSM_SRV_RQ 5250;
BA_ "FlexKomSigStartValue" SG_ 720 BSM_SRV_RQ "00h";
BA_ "GenSigCycleTime" SG_ 720 BSM_SRV_RQ 500;
BA_ "GenSigSendType" SG_ 720 BSM_SRV_RQ 5;
BA_ "GenSigSNA" SG_ 720 BSM_RT_WRN "7h";
BA_ "FlexKomIsMotorola" SG_ 720 BSM_RT_WRN 1;
BA_ "FlexKomComment" SG_ 720 BSM_RT_WRN "Blind spot detection warning status";
BA_ "FlexKomSigName" SG_ 720 BSM_RT_WRN "BSM_WRN";
BA_ "FlexKomSigLaenge" SG_ 720 BSM_RT_WRN 6;
BA_ "FlexKomSigStartPos" SG_ 720 BSM_RT_WRN 5;
BA_ "FlexKomSID" SG_ 720 BSM_RT_WRN 9;
BA_ "GenSigTimeout_HaLF" SG_ 720 BSM_RT_WRN 5250;
BA_ "GenSigTimeout_IC" SG_ 720 BSM_RT_WRN 5250;
BA_ "FlexKomSigStartValue" SG_ 720 BSM_RT_WRN "00h";
BA_ "GenSigCycleTime" SG_ 720 BSM_RT_WRN 500;
BA_ "GenSigSendType" SG_ 720 BSM_RT_WRN 5;
BA_ "GenSigSNA" SG_ 720 BSM_OPR_STAT "0h";
BA_ "FlexKomIsMotorola" SG_ 720 BSM_OPR_STAT 1;
BA_ "FlexKomComment" SG_ 720 BSM_OPR_STAT "BSM operation status; 1= operational failure";
BA_ "FlexKomSigName" SG_ 720 BSM_OPR_STAT "BSM_OPR_STAT";
BA_ "FlexKomSigLaenge" SG_ 720 BSM_OPR_STAT 1;
BA_ "FlexKomSigStartPos" SG_ 720 BSM_OPR_STAT 11;
BA_ "FlexKomSID" SG_ 720 BSM_OPR_STAT 7;
BA_ "GenSigTimeout_HaLF" SG_ 720 BSM_OPR_STAT 5250;
BA_ "GenSigTimeout_IC" SG_ 720 BSM_OPR_STAT 5250;
BA_ "FlexKomSigStartValue" SG_ 720 BSM_OPR_STAT "00h";
BA_ "GenSigCycleTime" SG_ 720 BSM_OPR_STAT 500;
BA_ "GenSigSendType" SG_ 720 BSM_OPR_STAT 5;
BA_ "GenSigSNA" SG_ 720 BSM_LT_WRN "7h";
BA_ "FlexKomIsMotorola" SG_ 720 BSM_LT_WRN 1;
BA_ "FlexKomComment" SG_ 720 BSM_LT_WRN "Blind spot detection warning status";
BA_ "FlexKomSigName" SG_ 720 BSM_LT_WRN "BSM_WRN";
BA_ "FlexKomSigLaenge" SG_ 720 BSM_LT_WRN 6;
BA_ "FlexKomSigStartPos" SG_ 720 BSM_LT_WRN 5;
BA_ "FlexKomSID" SG_ 720 BSM_LT_WRN 9;
BA_ "GenSigTimeout_HaLF" SG_ 720 BSM_LT_WRN 5250;
BA_ "GenSigTimeout_IC" SG_ 720 BSM_LT_WRN 5250;
BA_ "FlexKomSigStartValue" SG_ 720 BSM_LT_WRN "00h";
BA_ "GenSigCycleTime" SG_ 720 BSM_LT_WRN 500;
BA_ "GenSigSendType" SG_ 720 BSM_LT_WRN 5;
BA_ "GenSigSNA" SG_ 720 BSM_CFG_STAT_TeenKey "3h";
BA_ "FlexKomIsMotorola" SG_ 720 BSM_CFG_STAT_TeenKey 1;
BA_ "FlexKomComment" SG_ 720 BSM_CFG_STAT_TeenKey "BSM configuration status for teen key";
BA_ "FlexKomSigName" SG_ 720 BSM_CFG_STAT_TeenKey "BSM_CFG_STAT_TeenKey";
BA_ "FlexKomSigLaenge" SG_ 720 BSM_CFG_STAT_TeenKey 2;
BA_ "FlexKomSigStartPos" SG_ 720 BSM_CFG_STAT_TeenKey 23;
BA_ "FlexKomSID" SG_ 720 BSM_CFG_STAT_TeenKey 2328;
BA_ "GenSigStartValue" SG_ 720 BSM_CFG_STAT_TeenKey 3;
BA_ "FlexKomSigStartValue" SG_ 720 BSM_CFG_STAT_TeenKey "03h";
BA_ "GenSigCycleTime" SG_ 720 BSM_CFG_STAT_TeenKey 500;
BA_ "GenSigSendType" SG_ 720 BSM_CFG_STAT_TeenKey 5;
BA_ "GenSigSNA" SG_ 720 BSM_CFG_STAT "3h";
BA_ "FlexKomIsMotorola" SG_ 720 BSM_CFG_STAT 1;
BA_ "FlexKomComment" SG_ 720 BSM_CFG_STAT "BSM configuration status";
BA_ "FlexKomSigName" SG_ 720 BSM_CFG_STAT "BSM_CFG_STAT";
BA_ "FlexKomSigLaenge" SG_ 720 BSM_CFG_STAT 2;
BA_ "FlexKomSigStartPos" SG_ 720 BSM_CFG_STAT 9;
BA_ "FlexKomSID" SG_ 720 BSM_CFG_STAT 4;
BA_ "GenSigTimeout_HaLF" SG_ 720 BSM_CFG_STAT 5250;
BA_ "GenSigTimeout_IC" SG_ 720 BSM_CFG_STAT 5250;
BA_ "GenSigStartValue" SG_ 720 BSM_CFG_STAT 3;
BA_ "FlexKomSigStartValue" SG_ 720 BSM_CFG_STAT "03h";
BA_ "GenSigCycleTime" SG_ 720 BSM_CFG_STAT 500;
BA_ "GenSigSendType" SG_ 720 BSM_CFG_STAT 5;
BA_ "GenSigSNA" SG_ 720 BSM_Blind_RQ "0h";
BA_ "FlexKomIsMotorola" SG_ 720 BSM_Blind_RQ 1;
BA_ "FlexKomComment" SG_ 720 BSM_Blind_RQ "Sensor blinded request from BSM; 1= sensor blocked";
BA_ "FlexKomSigName" SG_ 720 BSM_Blind_RQ "BSM_Blind_RQ";
BA_ "FlexKomSigLaenge" SG_ 720 BSM_Blind_RQ 1;
BA_ "FlexKomSigStartPos" SG_ 720 BSM_Blind_RQ 13;
BA_ "FlexKomSID" SG_ 720 BSM_Blind_RQ 1362;
BA_ "GenSigTimeout_HaLF" SG_ 720 BSM_Blind_RQ 5250;
BA_ "GenSigTimeout_IC" SG_ 720 BSM_Blind_RQ 5250;
BA_ "FlexKomSigStartValue" SG_ 720 BSM_Blind_RQ "00h";
BA_ "GenSigCycleTime" SG_ 720 BSM_Blind_RQ 500;
BA_ "GenSigSendType" SG_ 720 BSM_Blind_RQ 5;
BA_ "GenMsgStartValue" BO_ 719 "0000000000000000h";
BA_ "GenMsgNrOfRepetitions" BO_ 719 2;
BA_ "GenMsgDelayTime" BO_ 719 20;
BA_ "GenMsgCycleTime" BO_ 719 500;
BA_ "GenMsgSendType" BO_ 719 5;
BA_ "GenSigSNA" SG_ 719 PTS_DBD "0h";
BA_ "FlexKomIsMotorola" SG_ 719 PTS_DBD 1;
BA_ "FlexKomComment" SG_ 719 PTS_DBD "Park assist system disabled; System_Disabled = [1]";
BA_ "FlexKomSigName" SG_ 719 PTS_DBD "PTS_DBD";
BA_ "FlexKomSigLaenge" SG_ 719 PTS_DBD 1;
BA_ "FlexKomSigStartPos" SG_ 719 PTS_DBD 16;
BA_ "FlexKomSID" SG_ 719 PTS_DBD 1949;
BA_ "GenSigTimeout_IC" SG_ 719 PTS_DBD 5250;
BA_ "FlexKomSigStartValue" SG_ 719 PTS_DBD "00h";
BA_ "GenSigCycleTime" SG_ 719 PTS_DBD 500;
BA_ "GenSigSendType" SG_ 719 PTS_DBD 5;
BA_ "GenSigSNA" SG_ 719 PPPASystemFault "0h";
BA_ "FlexKomIsMotorola" SG_ 719 PPPASystemFault 1;
BA_ "FlexKomComment" SG_ 719 PPPASystemFault "Indicates the fail status of PPPA; true = [1]";
BA_ "FlexKomSigName" SG_ 719 PPPASystemFault "PPPASystemFault";
BA_ "FlexKomSigLaenge" SG_ 719 PPPASystemFault 1;
BA_ "FlexKomSigStartPos" SG_ 719 PPPASystemFault 8;
BA_ "FlexKomSID" SG_ 719 PPPASystemFault 1917;
BA_ "GenSigTimeout_IC" SG_ 719 PPPASystemFault 5250;
BA_ "FlexKomSigStartValue" SG_ 719 PPPASystemFault "00h";
BA_ "GenSigCycleTime" SG_ 719 PPPASystemFault 500;
BA_ "GenSigSendType" SG_ 719 PPPASystemFault 5;
BA_ "GenSigSNA" SG_ 719 PPPAControlSts "0h";
BA_ "FlexKomIsMotorola" SG_ 719 PPPAControlSts 1;
BA_ "FlexKomComment" SG_ 719 PPPAControlSts "Indicates the active state of PPPA; active = [1]";
BA_ "FlexKomSigName" SG_ 719 PPPAControlSts "PPPAControlSts";
BA_ "FlexKomSigLaenge" SG_ 719 PPPAControlSts 1;
BA_ "FlexKomSigStartPos" SG_ 719 PPPAControlSts 9;
BA_ "FlexKomSID" SG_ 719 PPPAControlSts 1918;
BA_ "GenSigTimeout_IC" SG_ 719 PPPAControlSts 5250;
BA_ "FlexKomSigStartValue" SG_ 719 PPPAControlSts "00h";
BA_ "GenSigCycleTime" SG_ 719 PPPAControlSts 500;
BA_ "GenSigSendType" SG_ 719 PPPAControlSts 5;
BA_ "GenSigSNA" SG_ 719 PPPA_STAT "3h";
BA_ "FlexKomIsMotorola" SG_ 719 PPPA_STAT 1;
BA_ "FlexKomComment" SG_ 719 PPPA_STAT "Parallel & perpendicular park assist switch status";
BA_ "FlexKomSigName" SG_ 719 PPPA_STAT "PPPA_STAT";
BA_ "FlexKomSigLaenge" SG_ 719 PPPA_STAT 2;
BA_ "FlexKomSigStartPos" SG_ 719 PPPA_STAT 15;
BA_ "FlexKomSID" SG_ 719 PPPA_STAT 1922;
BA_ "GenSigTimeout_CBC" SG_ 719 PPPA_STAT 5250;
BA_ "FlexKomSigStartValue" SG_ 719 PPPA_STAT "00h";
BA_ "GenSigCycleTime" SG_ 719 PPPA_STAT 500;
BA_ "GenSigSendType" SG_ 719 PPPA_STAT 5;
BA_ "GenSigSNA" SG_ 719 HMICode "0h";
BA_ "FlexKomIsMotorola" SG_ 719 HMICode 1;
BA_ "FlexKomComment" SG_ 719 HMICode "HMI codes to be displayed";
BA_ "FlexKomSigName" SG_ 719 HMICode "HMICode";
BA_ "FlexKomSigLaenge" SG_ 719 HMICode 8;
BA_ "FlexKomSigStartPos" SG_ 719 HMICode 7;
BA_ "FlexKomSID" SG_ 719 HMICode 1919;
BA_ "GenSigTimeout_IC" SG_ 719 HMICode 5250;
BA_ "FlexKomSigStartValue" SG_ 719 HMICode "00h";
BA_ "GenSigCycleTime" SG_ 719 HMICode 500;
BA_ "GenSigSendType" SG_ 719 HMICode 5;
BA_ "GenMsgSendType" BO_ 710 5;
BA_ "GenMsgCycleTime" BO_ 710 2000;
BA_ "GenMsgDelayTime" BO_ 710 20;
BA_ "GenMsgNrOfRepetitions" BO_ 710 2;
BA_ "GenMsgStartValue" BO_ 710 "0300000000000000h";
BA_ "GenSigSendType" SG_ 710 EC_PTS 5;
BA_ "GenSigCycleTime" SG_ 710 EC_PTS 2000;
BA_ "FlexKomSigStartValue" SG_ 710 EC_PTS "0300000000000000h";
BA_ "GenSigTimeout_PTS" SG_ 710 EC_PTS 21000;
BA_ "FlexKomSID" SG_ 710 EC_PTS 2478;
BA_ "FlexKomSigStartPos" SG_ 710 EC_PTS 7;
BA_ "FlexKomSigLaenge" SG_ 710 EC_PTS 64;
BA_ "FlexKomSigName" SG_ 710 EC_PTS "EcuCfg17Pkt";
BA_ "FlexKomComment" SG_ 710 EC_PTS "ECU Configuration 17 packet";
BA_ "FlexKomIsMotorola" SG_ 710 EC_PTS 1;
BA_ "GenSigSNA" SG_ 710 EC_PTS "0h";
BA_ "GenSigSendType" SG_ 710 EC_ECUCfg17_Stat 5;
BA_ "GenSigCycleTime" SG_ 710 EC_ECUCfg17_Stat 2000;
BA_ "FlexKomSigStartValue" SG_ 710 EC_ECUCfg17_Stat "0300000000000000h";
BA_ "GenSigStartValue" SG_ 710 EC_ECUCfg17_Stat 3;
BA_ "GenSigTimeout_PTS" SG_ 710 EC_ECUCfg17_Stat 21000;
BA_ "FlexKomSID" SG_ 710 EC_ECUCfg17_Stat 2478;
BA_ "FlexKomSigStartPos" SG_ 710 EC_ECUCfg17_Stat 7;
BA_ "FlexKomSigLaenge" SG_ 710 EC_ECUCfg17_Stat 64;
BA_ "FlexKomSigName" SG_ 710 EC_ECUCfg17_Stat "EcuCfg17Pkt";
BA_ "FlexKomComment" SG_ 710 EC_ECUCfg17_Stat "ECU Configuration 17 packet";
BA_ "FlexKomIsMotorola" SG_ 710 EC_ECUCfg17_Stat 1;
BA_ "GenSigSNA" SG_ 710 EC_ECUCfg17_Stat "3h";
BA_ "GenMsgStartValue" BO_ 709 "0300000000000000h";
BA_ "GenMsgNrOfRepetitions" BO_ 709 2;
BA_ "GenMsgDelayTime" BO_ 709 20;
BA_ "GenMsgCycleTime" BO_ 709 2000;
BA_ "GenMsgSendType" BO_ 709 5;
BA_ "GenSigSNA" SG_ 709 EC_ECUCfg16_Stat "3h";
BA_ "FlexKomIsMotorola" SG_ 709 EC_ECUCfg16_Stat 1;
BA_ "FlexKomComment" SG_ 709 EC_ECUCfg16_Stat "ECU Configuration messages status 16";
BA_ "FlexKomSigName" SG_ 709 EC_ECUCfg16_Stat "EC_ECUCfg16_Stat";
BA_ "FlexKomSigLaenge" SG_ 709 EC_ECUCfg16_Stat 2;
BA_ "FlexKomSigStartPos" SG_ 709 EC_ECUCfg16_Stat 1;
BA_ "FlexKomSID" SG_ 709 EC_ECUCfg16_Stat 2286;
BA_ "GenSigStartValue" SG_ 709 EC_ECUCfg16_Stat 3;
BA_ "FlexKomSigStartValue" SG_ 709 EC_ECUCfg16_Stat "03h";
BA_ "GenSigCycleTime" SG_ 709 EC_ECUCfg16_Stat 2000;
BA_ "GenSigSendType" SG_ 709 EC_ECUCfg16_Stat 5;
BA_ "GenSigSNA" SG_ 709 EC_AudTel3B "0h";
BA_ "FlexKomIsMotorola" SG_ 709 EC_AudTel3B 1;
BA_ "FlexKomComment" SG_ 709 EC_AudTel3B "Audio and telematics ecu configuration 3";
BA_ "FlexKomSigName" SG_ 709 EC_AudTel3B "EC_AudTel3";
BA_ "FlexKomSigLaenge" SG_ 709 EC_AudTel3B 64;
BA_ "FlexKomSigStartPos" SG_ 709 EC_AudTel3B 7;
BA_ "FlexKomSID" SG_ 709 EC_AudTel3B 2288;
BA_ "FlexKomSigStartValue" SG_ 709 EC_AudTel3B "0000000000000000h";
BA_ "GenSigCycleTime" SG_ 709 EC_AudTel3B 2000;
BA_ "GenSigSendType" SG_ 709 EC_AudTel3B 5;
BA_ "GenSigSNA" SG_ 709 EC_AudTel3A "0h";
BA_ "FlexKomIsMotorola" SG_ 709 EC_AudTel3A 1;
BA_ "FlexKomComment" SG_ 709 EC_AudTel3A "Audio and telematics ecu configuration 3";
BA_ "FlexKomSigName" SG_ 709 EC_AudTel3A "EC_AudTel3";
BA_ "FlexKomSigLaenge" SG_ 709 EC_AudTel3A 64;
BA_ "FlexKomSigStartPos" SG_ 709 EC_AudTel3A 7;
BA_ "FlexKomSID" SG_ 709 EC_AudTel3A 2288;
BA_ "FlexKomSigStartValue" SG_ 709 EC_AudTel3A "0000000000000000h";
BA_ "GenSigCycleTime" SG_ 709 EC_AudTel3A 2000;
BA_ "GenSigSendType" SG_ 709 EC_AudTel3A 5;
BA_ "GenMsgStartValue" BO_ 706 "0300000000000000h";
BA_ "GenMsgNrOfRepetitions" BO_ 706 2;
BA_ "GenMsgDelayTime" BO_ 706 20;
BA_ "GenMsgCycleTime" BO_ 706 2000;
BA_ "GenMsgSendType" BO_ 706 5;
BA_ "GenSigSNA" SG_ 706 EC_Suspension "0h";
BA_ "FlexKomIsMotorola" SG_ 706 EC_Suspension 1;
BA_ "FlexKomComment" SG_ 706 EC_Suspension "Suspension ecu configuration";
BA_ "FlexKomSigName" SG_ 706 EC_Suspension "EC_Suspension";
BA_ "FlexKomSigLaenge" SG_ 706 EC_Suspension 16;
BA_ "FlexKomSigStartPos" SG_ 706 EC_Suspension 55;
BA_ "FlexKomSID" SG_ 706 EC_Suspension 891;
BA_ "FlexKomSigStartValue" SG_ 706 EC_Suspension "0000h";
BA_ "GenSigCycleTime" SG_ 706 EC_Suspension 2000;
BA_ "GenSigSendType" SG_ 706 EC_Suspension 5;
BA_ "GenSigSNA" SG_ 706 EC_ECUCfg15_Stat "3h";
BA_ "FlexKomIsMotorola" SG_ 706 EC_ECUCfg15_Stat 1;
BA_ "FlexKomComment" SG_ 706 EC_ECUCfg15_Stat "ECU Configuration messages status 15";
BA_ "FlexKomSigName" SG_ 706 EC_ECUCfg15_Stat "EC_ECUCfg15_Stat";
BA_ "FlexKomSigLaenge" SG_ 706 EC_ECUCfg15_Stat 2;
BA_ "FlexKomSigStartPos" SG_ 706 EC_ECUCfg15_Stat 1;
BA_ "FlexKomSID" SG_ 706 EC_ECUCfg15_Stat 2071;
BA_ "GenSigStartValue" SG_ 706 EC_ECUCfg15_Stat 3;
BA_ "FlexKomSigStartValue" SG_ 706 EC_ECUCfg15_Stat "03h";
BA_ "GenSigCycleTime" SG_ 706 EC_ECUCfg15_Stat 2000;
BA_ "GenSigSendType" SG_ 706 EC_ECUCfg15_Stat 5;
BA_ "GenSigSNA" SG_ 706 EC_CBC15B "0h";
BA_ "FlexKomIsMotorola" SG_ 706 EC_CBC15B 1;
BA_ "FlexKomComment" SG_ 706 EC_CBC15B "CBC ecu configuration 15";
BA_ "FlexKomSigName" SG_ 706 EC_CBC15B "EC_CBC15";
BA_ "FlexKomSigLaenge" SG_ 706 EC_CBC15B 48;
BA_ "FlexKomSigStartPos" SG_ 706 EC_CBC15B 7;
BA_ "FlexKomSID" SG_ 706 EC_CBC15B 2072;
BA_ "FlexKomSigStartValue" SG_ 706 EC_CBC15B "000000000000h";
BA_ "GenSigCycleTime" SG_ 706 EC_CBC15B 2000;
BA_ "GenSigSendType" SG_ 706 EC_CBC15B 5;
BA_ "GenSigSNA" SG_ 706 EC_CBC15A "0h";
BA_ "FlexKomIsMotorola" SG_ 706 EC_CBC15A 1;
BA_ "FlexKomComment" SG_ 706 EC_CBC15A "CBC ecu configuration 15";
BA_ "FlexKomSigName" SG_ 706 EC_CBC15A "EC_CBC15";
BA_ "FlexKomSigLaenge" SG_ 706 EC_CBC15A 48;
BA_ "FlexKomSigStartPos" SG_ 706 EC_CBC15A 7;
BA_ "FlexKomSID" SG_ 706 EC_CBC15A 2072;
BA_ "FlexKomSigStartValue" SG_ 706 EC_CBC15A "000000000000h";
BA_ "GenSigCycleTime" SG_ 706 EC_CBC15A 2000;
BA_ "GenSigSendType" SG_ 706 EC_CBC15A 5;
BA_ "GenMsgStartValue" BO_ 705 "0000FFFFFF7F7F7Fh";
BA_ "GenMsgNrOfRepetitions" BO_ 705 2;
BA_ "GenMsgDelayTime" BO_ 705 20;
BA_ "GenMsgCycleTime" BO_ 705 1000;
BA_ "GenMsgSendType" BO_ 705 5;
BA_ "GenSigSNA" SG_ 705 VEH_INT_TEMP "FFFFh";
BA_ "FlexKomIsMotorola" SG_ 705 VEH_INT_TEMP 1;
BA_ "FlexKomComment" SG_ 705 VEH_INT_TEMP "-";
BA_ "FlexKomSigName" SG_ 705 VEH_INT_TEMP "GW_LIN_I_C5_Pkt";
BA_ "FlexKomSigLaenge" SG_ 705 VEH_INT_TEMP 64;
BA_ "FlexKomSigStartPos" SG_ 705 VEH_INT_TEMP 7;
BA_ "FlexKomSID" SG_ 705 VEH_INT_TEMP 2511;
BA_ "GenSigStartValue" SG_ 705 VEH_INT_TEMP 65535;
BA_ "FlexKomSigStartValue" SG_ 705 VEH_INT_TEMP "0000FFFFFF7F7F7Fh";
BA_ "GenSigCycleTime" SG_ 705 VEH_INT_TEMP 1000;
BA_ "GenSigSendType" SG_ 705 VEH_INT_TEMP 5;
BA_ "GenSigSendType" SG_ 705 R_Temp1_Pos 5;
BA_ "GenSigCycleTime" SG_ 705 R_Temp1_Pos 1000;
BA_ "FlexKomSigStartValue" SG_ 705 R_Temp1_Pos "0000FFFFFF7F7F7Fh";
BA_ "GenSigStartValue" SG_ 705 R_Temp1_Pos 127;
BA_ "FlexKomSID" SG_ 705 R_Temp1_Pos 2511;
BA_ "FlexKomSigStartPos" SG_ 705 R_Temp1_Pos 7;
BA_ "FlexKomSigLaenge" SG_ 705 R_Temp1_Pos 64;
BA_ "FlexKomSigName" SG_ 705 R_Temp1_Pos "GW_LIN_I_C5_Pkt";
BA_ "FlexKomComment" SG_ 705 R_Temp1_Pos "-";
BA_ "FlexKomIsMotorola" SG_ 705 R_Temp1_Pos 1;
BA_ "GenSigSNA" SG_ 705 R_Temp1_Pos "7Fh";
BA_ "GenSigSendType" SG_ 705 R_Blw1_Pos 5;
BA_ "GenSigCycleTime" SG_ 705 R_Blw1_Pos 1000;
BA_ "FlexKomSigStartValue" SG_ 705 R_Blw1_Pos "0000FFFFFF7F7F7Fh";
BA_ "GenSigStartValue" SG_ 705 R_Blw1_Pos 127;
BA_ "FlexKomSID" SG_ 705 R_Blw1_Pos 2511;
BA_ "FlexKomSigStartPos" SG_ 705 R_Blw1_Pos 7;
BA_ "FlexKomSigLaenge" SG_ 705 R_Blw1_Pos 64;
BA_ "FlexKomSigName" SG_ 705 R_Blw1_Pos "GW_LIN_I_C5_Pkt";
BA_ "FlexKomComment" SG_ 705 R_Blw1_Pos "-";
BA_ "FlexKomIsMotorola" SG_ 705 R_Blw1_Pos 1;
BA_ "GenSigSNA" SG_ 705 R_Blw1_Pos "7Fh";
BA_ "GenSigSendType" SG_ 705 HVAC_Blwr_Perct 5;
BA_ "GenSigCycleTime" SG_ 705 HVAC_Blwr_Perct 1000;
BA_ "FlexKomSigStartValue" SG_ 705 HVAC_Blwr_Perct "0000FFFFFF7F7F7Fh";
BA_ "GenSigStartValue" SG_ 705 HVAC_Blwr_Perct 127;
BA_ "FlexKomSID" SG_ 705 HVAC_Blwr_Perct 2511;
BA_ "FlexKomSigStartPos" SG_ 705 HVAC_Blwr_Perct 7;
BA_ "FlexKomSigLaenge" SG_ 705 HVAC_Blwr_Perct 64;
BA_ "FlexKomSigName" SG_ 705 HVAC_Blwr_Perct "GW_LIN_I_C5_Pkt";
BA_ "FlexKomComment" SG_ 705 HVAC_Blwr_Perct "-";
BA_ "FlexKomIsMotorola" SG_ 705 HVAC_Blwr_Perct 1;
BA_ "GenSigSNA" SG_ 705 HVAC_Blwr_Perct "7Fh";
BA_ "GenSigSNA" SG_ 705 HtrCorTmp_InTgt "FFh";
BA_ "FlexKomIsMotorola" SG_ 705 HtrCorTmp_InTgt 1;
BA_ "FlexKomComment" SG_ 705 HtrCorTmp_InTgt "-";
BA_ "FlexKomSigName" SG_ 705 HtrCorTmp_InTgt "GW_LIN_I_C5_Pkt";
BA_ "FlexKomSigLaenge" SG_ 705 HtrCorTmp_InTgt 64;
BA_ "FlexKomSigStartPos" SG_ 705 HtrCorTmp_InTgt 7;
BA_ "FlexKomSID" SG_ 705 HtrCorTmp_InTgt 2511;
BA_ "GenSigStartValue" SG_ 705 HtrCorTmp_InTgt 255;
BA_ "FlexKomSigStartValue" SG_ 705 HtrCorTmp_InTgt "0000FFFFFF7F7F7Fh";
BA_ "GenSigCycleTime" SG_ 705 HtrCorTmp_InTgt 1000;
BA_ "GenSigSendType" SG_ 705 HtrCorTmp_InTgt 5;
VAL_ 863 RevOilLifeRst 65535 "SNA" ;
VAL_ 860 UNITS 7 "SNA" 5 "YARD" 4 "METER" 3 "KM" 2 "FEET" 1 "MILE" 0 "NO_UNITS" ;
VAL_ 860 NAV_ARROW 0 "NAV_NOT_ACT" ;
VAL_ 860 DIST_TO_TURN 65535 "SNA" ;
VAL_ 856 CMP_DIR 15 "SNA" 8 "NONE" 7 "CMP_N_W" 6 "CMP_W" 5 "CMP_S_W" 4 "CMP_S" 3 "CMP_S_E" 2 "CMP_E" 1 "CMP_N_E" 0 "CMP_N" ;
VAL_ 853 IBS_IBATT_QUIESCENT 255 "SNA" 254 "MEAS_GT_1A" 253 "MEAS_NOT_DONE" ;
VAL_ 848 DateTmYear 65535 "SNA" ;
VAL_ 848 DateTmSec 255 "SNA" ;
VAL_ 848 DateTmMonth 255 "SNA" ;
VAL_ 848 DateTmMinute 255 "SNA" ;
VAL_ 848 DateTmHour 255 "SNA" ;
VAL_ 848 DateTmFormat 7 "SNA" 6 "FORMAT_3" 5 "FORMAT_2" 4 "FORMAT_1" 3 "FORMAT_0" 2 "FORMAT_24H" 1 "FORMAT_12H" 0 "NDEF0" ;
VAL_ 848 DateTmDay 255 "SNA" ;
VAL_ 840 FailSafeError 65535 "SNA" ;
VAL_ 838 AS_CHIME_TYPE 0 "NONE" 1 "TYP_1_FastBeeps_FcwBrakeWarn" 2 "TYP_2_CrossTrafficAlert" 3 "TYP_3_TripleBeeps_FcwBrakeLoud" 4 "TYP_4_RealSlow_ParkAsssist_Dist0_Furthest" 5 "TYP_5_LikeType4ButLouder" 6 "TYP_6_RealSlow_ParkAsssist_Dist1" 7 "TYP_7_SoundsJustLikeType6" 8 "TYP_6_RealSlow_ParkAsssist_Dist2" 9 "TYP_9_SlowBeeps_FcwBrake" 10 "TYP_10_SoundsJustLikeType9" 11 "TYP_11_SoundsJustLikeType9" 12 "TYP_12_SoundsJustLikeType9" 13 "TYP_13_SoundsJustLikeType9" 14 "TYP_14_SoundsJustLikeType9" 15 "SNA" ;
VAL_ 832 VehSpdDisp 65535 "SNA" ;
VAL_ 832 Est_Range_Disp 255 "SNA" ;
VAL_ 826 PTS_STAT 3 "SNA" 2 "BLINK" 1 "CONT" 0 "OFF" ;
VAL_ 826 PTS_GraphicRR 3 "None" 2 "CONT_FLS_RQ" 1 "FAST_FLS_RQ" 0 "SLOW_FLS_RQ" ;
VAL_ 826 PTS_GraphicRL 3 "None" 2 "CONT_FLS_RQ" 1 "FAST_FLS_RQ" 0 "SLOW_FLS_RQ" ;
VAL_ 826 PTS_GraphicRC 3 "None" 2 "CONT_FLS_RQ" 1 "FAST_FLS_RQ" 0 "SLOW_FLS_RQ" ;
VAL_ 826 PTS_GraphicFR 3 "None" 2 "CONT_FLS_RQ" 1 "FAST_FLS_RQ" 0 "SLOW_FLS_RQ" ;
VAL_ 826 PTS_GraphicFL 3 "None" 2 "CONT_FLS_RQ" 1 "FAST_FLS_RQ" 0 "SLOW_FLS_RQ" ;
VAL_ 826 PTS_GraphicFC 3 "None" 2 "CONT_FLS_RQ" 1 "FAST_FLS_RQ" 0 "SLOW_FLS_RQ" ;
VAL_ 826 PTS_CFG_STAT 3 "SNA" 2 "SND_DISP" 1 "SND" 0 "OFF" ;
VAL_ 826 PTS_AlrRR 15 "SNA" 8 "ARC8" 7 "ARC7" 6 "ARC6" 5 "ARC5" 4 "ARC4" 3 "ARC3" 2 "ARC2" 1 "ARC1" 0 "PTS_ALR_NOD" ;
VAL_ 826 PTS_AlrRL 15 "SNA" 8 "ARC8" 7 "ARC7" 6 "ARC6" 5 "ARC5" 4 "ARC4" 3 "ARC3" 2 "ARC2" 1 "ARC1" 0 "PTS_ALR_NOD" ;
VAL_ 826 PTS_AlrRC 15 "SNA" 8 "ARC8" 7 "ARC7" 6 "ARC6" 5 "ARC5" 4 "ARC4" 3 "ARC3" 2 "ARC2" 1 "ARC1" 0 "PTS_ALR_NOD" ;
VAL_ 826 PTS_AlrFR 15 "SNA" 8 "ARC8" 7 "ARC7" 6 "ARC6" 5 "ARC5" 4 "ARC4" 3 "ARC3" 2 "ARC2" 1 "ARC1" 0 "PTS_ALR_NOD" ;
VAL_ 826 PTS_AlrFL 15 "SNA" 8 "ARC8" 7 "ARC7" 6 "ARC6" 5 "ARC5" 4 "ARC4" 3 "ARC3" 2 "ARC2" 1 "ARC1" 0 "PTS_ALR_NOD" ;
VAL_ 826 PTS_AlrFC 15 "SNA" 8 "ARC8" 7 "ARC7" 6 "ARC6" 5 "ARC5" 4 "ARC4" 3 "ARC3" 2 "ARC2" 1 "ARC1" 0 "PTS_ALR_NOD" ;
VAL_ 825 PTS_RR_VOL 3 "SNA" 2 "HIGH" 1 "MED" 0 "LOW" ;
VAL_ 825 PTS_FT_VOL 3 "SNA" 2 "HIGH" 1 "MED" 0 "LOW" ;
VAL_ 825 PTS_CHIME_TYPE 15 "SNA" 14 "TYP_14" 13 "TYP_13" 12 "TYP_12" 11 "TYP_11" 10 "TYP_10" 9 "TYP_9" 8 "TYP_8" 7 "TYP_7" 6 "TYP_6" 5 "TYP_5" 4 "TYP_4" 3 "TYP_3" 2 "TYP_2" 1 "TYP_1" 0 "NONE" ;
VAL_ 820 SHIP_STAT 3 "NOT_PROG" 2 "SHIP_MD" 1 "ABBRV_MD" 0 "CUST_MD" ;
VAL_ 820 PANEL_INTS 255 "SNA" ;
VAL_ 820 IGN_OFF_TIME_LNG 4095 "SNA" ;
VAL_ 820 FOB_SrchRq 2 "RCVD_RSLT" 1 "SEARCH" 0 "NO_ACT" ;
VAL_ 820 DR_LK_STAT 3 "SNA" 2 "ALL_DR_UNLKD" 1 "DRV_DR_UNLKD" 0 "LKD" ;
VAL_ 820 x334_ParkingBrakeState 0 "Not Applied" 1 "Applied" ;
VAL_ 817 PSD_RT_DisplayStat 14 "RMP_DPLY" 13 "UNLVL" 12 "RMP_DSBL" 11 "RMP_OBS" 10 "HF_CNTMNTD" 15 "RMP_STOW" 9 "FUEL_DR" 6 "MAN_CLS" 5 "OBS_DET" 4 "OLO" 3 "DSBL" 2 "PK" 1 "UNLK" 0 "OK" ;
VAL_ 817 PSD_LT_DisplayStat 14 "RMP_DPLY" 13 "UNLVL" 12 "RMP_DSBL" 11 "RMP_OBS" 10 "HF_CNTMNTD" 15 "RMP_STOW" 9 "FUEL_DR" 6 "MAN_CLS" 5 "OBS_DET" 4 "OLO" 3 "DSBL" 2 "PK" 1 "UNLK" 0 "OK" ;
VAL_ 816 PLG_Stat 15 "RMP_STOW" 14 "RMP_DPLY" 13 "UNLVL" 12 "RMP_DSBL" 11 "RMP_OBS" 10 "HF_CNTMNTD" 8 "HOT" 7 "COLD" 6 "MAN_CLS" 5 "OBS_DET" 4 "CLS_FG" 3 "DSBL" 2 "PK" 1 "UNLK" 0 "OK" ;
VAL_ 816 HVAC_CLNT_FLW_MIN 255 "SNA" 254 "CLOSE" 0 "OPEN" ;
VAL_ 808 TGW_GrpTyp_IC 63 "SNA" 0 "NO_TEXT" ;
VAL_ 804 WPR_SYS_WASH 0 "SNA" ;
VAL_ 804 WPR_SYS_OFF 1 "SNA" ;
VAL_ 804 WPR_SYS_MIST 0 "SNA" ;
VAL_ 804 WPR_SYS_LOW 0 "SNA" ;
VAL_ 804 WPR_SYS_INT 0 "SNA" ;
VAL_ 804 WPR_SYS_HIGH 0 "SNA" ;
VAL_ 804 WPR_SYS_FLT 0 "SNA" ;
VAL_ 804 WPR_SYS_AUTO 0 "SNA" ;
VAL_ 804 RemSt_Inhibit 255 "SNA" 44 "PSA_Not_Active" 43 "RFHUB_HS_FAIL" 42 "ESL_NOT_UNLOCK" 41 "COLD_START_LAMP" 40 "LOGISTIC_MODE" 39 "ETC_LAMP_ON" 38 "LOW_FUEL" 37 "GLOW_PLUG_TIMEOUT" 36 "IGN_NOT_LOCK" 35 "IGN_SNA" 34 "INVALID_SKIM_KEY" 33 "NOT_ENABLED" 32 "NO_AUTO_TRANS" 31 "NO_HOOD_SWITCH" 30 "NOT_CONFIGURED" 29 "RS_DISABLED_PREV" 28 "REMOTE_OFF_RQ" 27 "CRANK_NO_START" 26 "RPM_HIGH" 25 "COOLANT_TEMP_HIGH" 24 "OIL_PRESSURE_LOW" 23 "MIL_ON" 22 "POWER_LOSS" 21 "BATT_VOLT_LOW" 20 "BATT_VOLT_HIGH" 19 "PANIC_MODE" 18 "VTA_ALARM" 17 "TRUNK_LIFTGATE" 16 "HOOD_AJAR" 15 "VEH_SPEED_HIGH" 14 "NOT_IN_PARK" 13 "HAZARD_LAMP_ON" 12 "BRAKE_PRESSED" 11 "KEY_IN_IGN" 10 "LOW_RPM_SHUTDOWN" 9 "FAIL_COUNTER" 8 "START_COUNTER" 7 "RR_DOOR_AJAR" 6 "LR_DOOR_AJAR" 5 "PASS_DOOR_AJAR" 4 "DRV_DOOR_AJAR" 3 "KEY_IN_RUN" 2 "TIME_OUT_CUST_MODE" 1 "TIME_OUT_RUN" 0 "INHIBIT_DEFAUILT" ;
VAL_ 800 RefuelIndication 4 "DOOR" 3 "OK" 2 "PARK" 1 "WAIT" 0 "NONE" ;
VAL_ 800 RefuelEvent 4 "FAULT" 3 "COMP" 2 "TRUE" 1 "PEND" 0 "NONE" ;
VAL_ 800 LeakTestSts 3 "DELAY" 2 "COMPLETE" 1 "PEND" 0 "NONE" ;
VAL_ 800 LeakCheckTimerValue 511 "SNA" ;
VAL_ 800 KeySense_SetSpdOpt 7 "SNA" 5 "OPT_5" 4 "OPT_4" 3 "OPT_3" 2 "OPT_2" 1 "OPT_1" 0 "NOT_PROG" ;
VAL_ 800 KeySense_DispReq 2 "SPD_LMT" 1 "WARN" 0 "NONE" ;
VAL_ 799 TGW_AUD_MD_CAB_DR 31 "SNA" 30 "RAD_LOCK" 29 "RAD_OFF" 28 "IR_OFF" 27 "AUD_MUTED" 26 "APPS_SEL" 25 "USB2_SEL" 24 "TV_SEL" 23 "PASS_BT1_SEL" 22 "VES_AUX4_SEL" 21 "VES_AUX3_SEL" 20 "ES_SEL" 19 "TGW_USB1_SEL" 18 "DAB_SEL" 16 "PPR_SEL" 15 "SDARV_SEL" 14 "VES_AUX2_SEL" 13 "VES_AUX1_SEL" 12 "TMM_SEL" 11 "VES_DVD1_SEL" 10 "SW_SEL" 9 "SDAR1_SEL" 7 "INT_SLOT_SEL" 6 "INT_AUX_SEL" 5 "INT_HDD_SEL" 4 "INT_Disk_SEL" 3 "LW_SEL" 2 "MW_SEL" 1 "FM_SEL" 0 "AM_SEL" ;
VAL_ 799 IBS_R_Batt_25 2047 "SNA" ;
VAL_ 799 IBS_R_Batt 2047 "SNA" ;
VAL_ 792 WprWashSw_Psd 2 "WASH" 1 "MIST" 0 "NPSD" ;
VAL_ 792 WprWash_R_Sw_Posn_V3 3 "CONSTANT" 2 "WASH" 1 "INTERMITTENT" 0 "OFF" ;
VAL_ 792 WprSw6Posn 15 "SNA" 14 "WPR_HI" 13 "WPR_LOW" 6 "INTERVAL6" 5 "INTERVAL5" 4 "INTERVAL4" 3 "INTERVAL3" 2 "INTERVAL2" 1 "INTERVAL1" 0 "OFF" ;
VAL_ 792 TurnIndLvr_Stat 2 "RIGHT" 1 "LEFT" 0 "IDLE" ;
VAL_ 792 HiBmLvr_Stat 2 "HIBM_FLSH_ON_PSD" 1 "HIBM_ON_PSD" 0 "IDLE" ;
VAL_ 792 x318_StW_TiltTeleBtnPosn 0 "No Request" 1 "Up" 2 "Down" 3 "Forward" 4 "Backward" ;
VAL_ 784 SRS_LMP_STAT 3 "SNA" 2 "SRS_LMP_ON_IC" 1 "SRS_LMP_ON" 0 "SRS_LMP_OFF" ;
VAL_ 784 PTS_MODE_SELECTION 7 "SNA" 4 "OVER" 3 "PULL_OUT" 2 "PERP" 1 "PARA" 0 "None" ;
VAL_ 784 ODO 16777215 "SNA" ;
VAL_ 784 AvgFuelLvl 511 "SNA" ;
VAL_ 782 Total_Range 2047 "SNA" ;
VAL_ 782 Gas_Range 1023 "SNA" ;
VAL_ 779 OilLifeLeft 255 "SNA" ;
VAL_ 779 MntncSts 3 "SNA" 2 "NOW" 1 "SOON" 0 "NONE" ;
VAL_ 779 HoursOilLifeRst 4095 "SNA" ;
VAL_ 779 FuelMM_Sts 2 "DISABLED" 1 "ACTIVE" 0 "INACTIVE" ;
VAL_ 779 DisOilLifeRst 65535 "SNA" ;
VAL_ 773 TPM_SysStat 4 "LOCALIZATION_NOT_CMPLT" 7 "SNA" 3 "TPM_NA" 2 "LOCALIZATION_CMPLT" 1 "PERF_LOCALIZATION" 0 "NON_LOCALIZED" ;
VAL_ 773 TPM_IndLmpOnRq 3 "SNA" 2 "IND_LMP_FLASH" 1 "IND_LMP_ON" 0 "IND_LMP_OFF" ;
VAL_ 773 TirePrssSpr 255 "SNA" ;
VAL_ 773 TirePrssRR 255 "SNA" ;
VAL_ 773 TirePrssRL 255 "SNA" ;
VAL_ 773 TirePrssFR 255 "SNA" ;
VAL_ 773 TirePrssFL 255 "SNA" ;
VAL_ 773 Tire_Spr 3 "SNA" 2 "HIGH" 1 "LOW" 0 "NORMAL" ;
VAL_ 773 Tire_RR 3 "SNA" 2 "HIGH" 1 "LOW" 0 "NORMAL" ;
VAL_ 773 Tire_RL 3 "SNA" 2 "HIGH" 1 "LOW" 0 "NORMAL" ;
VAL_ 773 Tire_FR 3 "SNA" 2 "HIGH" 1 "LOW" 0 "NORMAL" ;
VAL_ 773 Tire_FL 3 "SNA" 2 "HIGH" 1 "LOW" 0 "NORMAL" ;
VAL_ 766 VVT_IntCam2Pos 0 "SNA" ;
VAL_ 766 VVT_IntCam1Pos 0 "SNA" ;
VAL_ 766 VVT_ExhCam2Pos 0 "SNA" ;
VAL_ 766 VVT_ExhCam1Pos 0 "SNA" ;
VAL_ 766 RelativeThrtPct 255 "SNA" ;
VAL_ 766 GF_Charge 65535 "SNA" ;
VAL_ 764 RelativeThrt 255 "SNA" ;
VAL_ 764 RelativePdl 255 "SNA" ;
VAL_ 764 RawTPS2 255 "SNA" ;
VAL_ 764 RawTPS1 255 "SNA" ;
VAL_ 764 RawPVS2 255 "SNA" ;
VAL_ 764 RawPVS1 255 "SNA" ;
VAL_ 764 MAP 255 "SNA" ;
VAL_ 760 ESS_ENG_ST 15 "SNA" 10 "KEY_START" 9 "ENS_STARTING" 8 "ENS_IHB_LATCH" 7 "ENS_DSBL" 6 "ENS_ST_INH" 5 "ENS_ST_PRTCT" 4 "ENS_STOP_PEND" 3 "ENS_RUN" 2 "ENS_RQ_ST" 1 "ENS_STOPPED" ;
VAL_ 746 DrvRqShftROT 7 "SNA" 5 "FIFTH" 4 "DRIVE" 3 "NEUT" 2 "REV" 1 "PARK" 0 "INIT" ;
VAL_ 746 APCM_Stat 3 "SNA" 2 "PENDING" 1 "ON" 0 "OFF" ;
VAL_ 746 x2EA_PrndManualUpDownPosn 0 "No Request" 1 "Unknown" 2 "+ Position" 3 "- Position" ;
VAL_ 736 RT_DIST 65535 "SNA" ;
VAL_ 736 LT_DIST 65535 "SNA" ;
VAL_ 736 ESP_Off_IndLmp_On_Rq 0 "SNA" ;
VAL_ 736 ESC_CtrlLmp_Info 3 "SNA" 2 "BLINK" 1 "CONT" 0 "OFF" ;
VAL_ 736 BrkIndLmp_On_Rq_ESC 3 "SNA" 2 "BLINK" 1 "CONT" 0 "OFF" ;
VAL_ 736 ABS_IndLmp_On_Rq 3 "SNA" 2 "BLINK" 1 "CONT" 0 "OFF" ;
VAL_ 729 TorqueIntensitySts 7 "SNA" 2 "T3" 1 "T2" 0 "T1" ;
VAL_ 729 LDW_LEDControlSts 3 "SNA" 2 "BLINK" 1 "CONT" 0 "OFF" ;
VAL_ 729 ConfigSts 7 "SNA" 4 "MOST" 3 "MORE" 2 "MID" 1 "LESS" 0 "LEAST" ;
VAL_ 720 BSM_RT_WRN 7 "SNA" 4 "FM_LED" 2 "RM_LED" 0 "NW" ;
VAL_ 720 BSM_LT_WRN 7 "SNA" 4 "FM_LED" 2 "RM_LED" 0 "NW" ;
VAL_ 720 BSM_CFG_STAT_TeenKey 3 "SNA" 2 "ENB_LED_CHM" 1 "ENB_LED" 0 "NT_ENB" ;
VAL_ 720 BSM_CFG_STAT 3 "SNA" 2 "ENB_LED_CHM" 1 "ENB_LED" 0 "NT_ENB" ;
VAL_ 719 PPPA_STAT 3 "SNA" 2 "BLINK" 1 "CONT" 0 "OFF" ;
VAL_ 710 EC_ECUCfg17_Stat 3 "SNA" 2 "REQUEST_DATA" 1 "PROGAMMED" 0 "NA" ;
VAL_ 709 EC_ECUCfg16_Stat 3 "SNA" 2 "REQUEST_DATA" 1 "PROGAMMED" 0 "NA" ;
VAL_ 706 EC_ECUCfg15_Stat 3 "SNA" 2 "REQUEST_DATA" 1 "PROGAMMED" 0 "NA" ;
VAL_ 705 VEH_INT_TEMP 65535 "SNA" ;
VAL_ 705 R_Temp1_Pos 127 "SNA" ;
VAL_ 705 R_Blw1_Pos 127 "SNA" ;
VAL_ 705 HVAC_Blwr_Perct 127 "SNA" ;
VAL_ 705 HtrCorTmp_InTgt 255 "SNA" ;
